VERSION "2021.24.4"

NS_ :

BS_:

BU_: VEH CH Receiver X

BO_ 259 VCRIGHT_doorStatus: 8 VEH
 SG_ VCRIGHT_frontHandlePWM: 14|7@1+ (1,0) [0|0] "%" X
 SG_ VCRIGHT_frontHandlePulled: 10|1@1+ (1,0) [0|0] "" X
 SG_ VCRIGHT_frontHandlePulledPersist: 30|1@1+ (1,0) [0|0] "" X
 SG_ VCRIGHT_frontIntSwitchPressed: 31|1@1+ (1,0) [0|0] "" X
 SG_ VCRIGHT_frontLatchStatus: 0|4@1+ (1,0) [0|0] "" X
 SG_ VCRIGHT_frontLatchSwitch: 8|1@1+ (1,0) [0|0] "" X
 SG_ VCRIGHT_frontRelActuatorSwitch: 12|1@1+ (1,0) [0|0] "" X
 SG_ VCRIGHT_mirrorDipped: 63|1@1+ (1,0) [0|0] "" X
 SG_ VCRIGHT_mirrorFoldState: 52|3@1+ (1,0) [0|0] "" X
 SG_ VCRIGHT_mirrorRecallState: 60|3@1+ (1,0) [0|0] "" X
 SG_ VCRIGHT_mirrorState: 49|3@1+ (1,0) [0|0] "" X
 SG_ VCRIGHT_mirrorTiltXPosition: 33|8@1+ (0.02,0) [0|0] "V" X
 SG_ VCRIGHT_mirrorTiltYPosition: 41|8@1+ (0.02,0) [0|0] "V" X
 SG_ VCRIGHT_rearHandlePWM: 21|7@1+ (1,0) [0|0] "%" X
 SG_ VCRIGHT_rearHandlePulled: 11|1@1+ (1,0) [0|0] "" X
 SG_ VCRIGHT_rearIntSwitchPressed: 32|1@1+ (1,0) [0|0] "" X
 SG_ VCRIGHT_rearLatchStatus: 4|4@1+ (1,0) [0|0] "" X
 SG_ VCRIGHT_rearLatchSwitch: 9|1@1+ (1,0) [0|0] "" X
 SG_ VCRIGHT_rearRelActuatorSwitch: 13|1@1+ (1,0) [0|0] "" X
 SG_ VCRIGHT_reservedForBackCompat: 28|2@1+ (1,0) [0|0] "" X
 SG_ VCRIGHT_trunkLatchStatus: 56|4@1+ (1,0) [0|0] "" X

BO_ 915 ID393VCRIGHT_epbmDebug: 8 VEH
 SG_ VCRIGHT_epbmDebugIndex M : 0|1@1+ (1,0) [0|1] ""  Receiver
 SG_ VCRIGHT_cdpEnumDummy m1 : 24|2@1+ (1,0) [0|2] ""  Receiver
 SG_ VCRIGHT_epbFaultStatus m0 : 58|2@1+ (1,0) [0|3] ""  Receiver
 SG_ VCRIGHT_epbMotorCurrent m0 : 5|11@1+ (0.01,0) [0|20.47] "A"  Receiver
 SG_ VCRIGHT_epbSummonState m0 : 45|3@1+ (1,0) [0|6] ""  Receiver
 SG_ VCRIGHT_epbUnitStatus m0 : 51|5@1+ (1,0) [0|22] ""  Receiver
 SG_ VCRIGHT_epbmApplyVoltage m0 : 16|11@1+ (0.01,0) [0|20.47] "A"  Receiver
 SG_ VCRIGHT_epbmCaliperState m0 : 1|3@1+ (1,0) [0|6] ""  Receiver
 SG_ VCRIGHT_epbmDynApplyingAllowed m1 : 9|1@1+ (1,0) [0|1] ""  Receiver
 SG_ VCRIGHT_epbmDynamicAllowed m1 : 2|1@1+ (1,0) [0|1] ""  Receiver
 SG_ VCRIGHT_epbmFaultAllowed m1 : 11|1@1+ (1,0) [0|1] ""  Receiver
 SG_ VCRIGHT_epbmFaultStatus m0 : 56|2@1+ (1,0) [0|3] ""  ui
 SG_ VCRIGHT_epbmMotorEnabled m0 : 4|1@1+ (1,0) [0|1] ""  Receiver
 SG_ VCRIGHT_epbmOpenAllowed m1 : 1|1@1+ (1,0) [0|1] ""  Receiver
 SG_ VCRIGHT_epbmParkAllowed m1 : 3|1@1+ (1,0) [0|1] ""  Receiver
 SG_ VCRIGHT_epbmParkingAllowed m1 : 8|1@1+ (1,0) [0|1] ""  Receiver
 SG_ VCRIGHT_epbmReleaseVoltage m0 : 27|11@1+ (0.01,0) [0|20.47] "A"  Receiver
 SG_ VCRIGHT_epbmReleasingAllowed m1 : 10|1@1+ (1,0) [0|1] ""  Receiver
 SG_ VCRIGHT_epbmServiceAllowed m1 : 5|1@1+ (1,0) [0|1] ""  Receiver
 SG_ VCRIGHT_epbmStartAllowed m1 : 4|1@1+ (1,0) [0|1] ""  Receiver
 SG_ VCRIGHT_epbmSummonAllowed m1 : 12|1@1+ (1,0) [0|1] ""  Receiver
 SG_ VCRIGHT_epbmSummonParkAllowed m1 : 13|1@1+ (1,0) [0|1] ""  Receiver
 SG_ VCRIGHT_epbmSummonReleaseAllowed m1 : 14|1@1+ (1,0) [0|1] ""  Receiver
 SG_ VCRIGHT_epbmSummonState m0 : 48|3@1+ (1,0) [0|6] ""  Receiver
 SG_ VCRIGHT_epbmSystemStatus m0 : 60|4@1+ (1,0) [0|8] ""  Receiver
 SG_ VCRIGHT_epbmUnknownAllowed m1 : 16|1@1+ (1,0) [0|1] ""  Receiver
 SG_ VCRIGHT_epbmWinchAllowed m1 : 6|1@1+ (1,0) [0|1] ""  Receiver
 SG_ VCRIGHT_epbmWinchReleaseAllowed m1 : 7|1@1+ (1,0) [0|1] ""  Receiver
 SG_ VCRIGHT_summonActiveAllowed m1 : 19|1@1+ (1,0) [0|1] ""  Receiver
 SG_ VCRIGHT_summonArmedAllowed m1 : 18|1@1+ (1,0) [0|1] ""  Receiver
 SG_ VCRIGHT_summonCompleteAllowed m1 : 20|1@1+ (1,0) [0|1] ""  Receiver
 SG_ VCRIGHT_summonFaultAllowed m1 : 21|1@1+ (1,0) [0|1] ""  Receiver
 SG_ VCRIGHT_summonFaultReason m0 : 40|5@1+ (1,0) [0|28] ""  Receiver
 SG_ VCRIGHT_summonIdleAllowed m1 : 17|1@1+ (1,0) [0|1] ""  Receiver
 SG_ VCRIGHT_summonInitAllowed m1 : 15|1@1+ (1,0) [0|1] ""  Receiver
 SG_ VCRIGHT_summonUnavailableAllowed m1 : 22|1@1+ (1,0) [0|1] ""  Receiver

BO_ 579 VCRIGHT_hvacStatus: 8 Vector__XXX
 SG_ VCRIGHT_hvacOverheatProtActive m3 : 63|1@1+ (1,0) [0|0] "" Vector__XXX
 SG_ VCRIGHT_hvacModelInitStatus m0 : 60|4@1+ (1,0) [0|0] "" Vector__XXX
 SG_ VCRIGHT_extendedHvacPerfTestSupportState m2 : 59|4@1+ (1,0) [0|0] "" Vector__XXX
 SG_ VCRIGHT_hvacLimitedReasonLeft m3 : 59|3@1+ (1,0) [0|0] "" Vector__XXX
 SG_ VCRIGHT_hvacSystemNominal m0 : 59|1@1+ (1,0) [0|0] "" Vector__XXX
 SG_ VCRIGHT_hvacDuctTargetRight m1 : 56|8@1+ (0.5,-40) [0|0] "" Vector__XXX
 SG_ VCRIGHT_hvacLimitedReasonRight m3 : 56|3@1+ (1,0) [0|0] "" Vector__XXX
 SG_ VCRIGHT_hvacSecondRowState m0 : 56|3@1+ (1,0) [0|0] "" Vector__XXX
 SG_ VCRIGHT_tempDuctRightLower m4 : 56|8@1+ (0.5,-22) [0|0] "" Vector__XXX
 SG_ VCRIGHT_hvacVentStatus m0 : 54|2@1+ (1,0) [0|0] "" Vector__XXX
 SG_ VCRIGHT_windshieldCameraHeaterDutyRequest m2 : 54|5@1+ (5,0) [0|0] "" Vector__XXX
 SG_ VCRIGHT_hvacRefHighPowerRequest m2 : 53|1@1+ (1,0) [0|0] "" Vector__XXX
 SG_ VCRIGHT_hvacPowerState m0 : 51|3@1+ (1,0) [0|0] "" Vector__XXX
 SG_ VCRIGHT_hvacACRunning m0 : 50|1@1+ (1,0) [0|0] "" Vector__XXX
 SG_ VCRIGHT_hvacDuctTargetLeft m1 : 48|8@1+ (0.5,-40) [0|0] "" Vector__XXX
 SG_ VCRIGHT_hvacRecirc m0 : 48|2@1+ (1,0) [0|0] "" Vector__XXX
 SG_ VCRIGHT_minsToSunset m3 : 48|8@1+ (10,0) [0|0] "" Vector__XXX
 SG_ VCRIGHT_refrigDistCommanded m2 : 48|1@1+ (1,0) [0|0] "" Vector__XXX
 SG_ VCRIGHT_tempDuctLeftLower m4 : 48|8@1+ (0.5,-22) [0|0] "" Vector__XXX
 SG_ VCRIGHT_hvacBlowerSegment m0 : 44|4@1+ (1,0) [0|0] "" Vector__XXX
 SG_ VCRIGHT_hvacAirDistributionMode m0 : 41|3@1+ (1,0) [0|0] "" Vector__XXX
 SG_ VCRIGHT_minsToSunrise m3 : 40|8@1+ (10,0) [0|0] "" Vector__XXX
 SG_ VCRIGHT_solarLoadOnVehicle m2 : 40|8@1+ (4,0) [0|0] "" Vector__XXX
 SG_ VCRIGHT_autoHvacBlowerShouldLimit m2 : 37|1@1+ (1,0) [0|0] "" Vector__XXX
 SG_ VCRIGHT_hvacQdotRight m4 : 34|14@1+ (1,-8191) [0|0] "" Vector__XXX
 SG_ VCRIGHT_blowerTorqueIndex m5 : 32|7@1+ (1,0) [0|0] "" Vector__XXX
 SG_ VCRIGHT_hvacAirflowReason m2 : 32|5@1+ (1,0) [0|0] "" Vector__XXX
 SG_ VCRIGHT_tempDuctRight m1 : 32|8@1+ (0.5,-22) [0|0] "" Vector__XXX
 SG_ VCRIGHT_solarElevation m3 : 31|9@1- (0.5,0) [0|0] "" Vector__XXX
 SG_ VCRIGHT_hvacCabinAtTempTarget m2 : 30|1@1+ (1,0) [0|0] "" Vector__XXX
 SG_ VCRIGHT_hvacCabinTempEst m0 : 30|11@1+ (0.1,-40) [0|0] "" Vector__XXX
 SG_ VCRIGHT_tempMonitorNotNominal m2 : 29|1@1+ (1,0) [0|0] "" Vector__XXX
 SG_ VCRIGHT_COPNotRunningReasonFiltered m0 : 27|3@1+ (1,0) [0|0] "" Vector__XXX
 SG_ VCRIGHT_autoDefogStatus m3 : 26|2@1+ (1,0) [0|0] "" Vector__XXX
 SG_ VCRIGHT_hvacCabinTempEstValid m0 : 26|1@1+ (1,0) [0|0] "" Vector__XXX
 SG_ VCRIGHT_hvacMassflowRefrigSystem m1 : 24|8@1+ (1,0) [0|0] "" Vector__XXX
 SG_ VCRIGHT_steeringWheelHeatStatus m3 : 24|2@1+ (1,0) [0|0] "" Vector__XXX
 SG_ VCRIGHT_dogModeState m0 : 22|4@1+ (1,0) [0|0] "" Vector__XXX
 SG_ VCRIGHT_hvacRequestsAutoIntake m3 : 22|1@1+ (1,0) [0|0] "" Vector__XXX
 SG_ VCRIGHT_passengerPresentHvacCycle m3 : 21|1@1+ (1,0) [0|0] "" Vector__XXX
 SG_ VCRIGHT_childModeHVACState m0 : 20|2@1+ (1,0) [0|0] "" Vector__XXX
 SG_ VCRIGHT_hvacQdotLeft m4 : 20|14@1+ (1,-8191) [0|0] "" Vector__XXX
 SG_ VCRIGHT_hvacEvapInletTempEstimate m2 : 19|10@1+ (0.13,-40) [0|0] "" Vector__XXX
 SG_ VCRIGHT_hpSplitTempsEnabled m2 : 18|1@1+ (1,0) [0|0] "" Vector__XXX
 SG_ VCRIGHT_hvacFrontLeftSeatHeatStatus m4 : 18|2@1+ (1,0) [0|0] "" Vector__XXX
 SG_ VCRIGHT_hvacRequestsFullAuto m3 : 17|3@1+ (1,0) [0|0] "" Vector__XXX
 SG_ VCRIGHT_tempDuctLeft m1 : 16|8@1+ (0.5,-22) [0|0] "" Vector__XXX
 SG_ VCRIGHT_coolingDownStatus m0 : 15|5@1+ (3,7) [0|0] "" Vector__XXX
 SG_ VCRIGHT_hvacManualToAutoNotify m3 : 14|3@1+ (1,0) [0|0] "" Vector__XXX
 SG_ VCRIGHT_hvacRecircDoorPercent m1 : 10|6@1+ (1.6,0) [0|0] "" Vector__XXX
 SG_ VCRIGHT_tempDuctLeftUpper m4 : 10|8@1+ (0.5,-22) [0|0] "" Vector__XXX
 SG_ VCRIGHT_tempDuctRightUpper m2 : 10|8@1+ (0.5,-22) [0|0] "" Vector__XXX
 SG_ VCRIGHT_warmingUpStatus m0 : 10|5@1+ (3,7) [0|0] "" Vector__XXX
 SG_ VCRIGHT_autoSwingAvailable m4 : 9|1@1+ (1,0) [0|0] "" Vector__XXX
 SG_ VCRIGHT_enableTripleCameraFanPowerInSleep m2 : 9|1@1+ (1,0) [0|0] "" Vector__XXX
 SG_ VCRIGHT_foggingControllerResetReason m5 : 9|15@1+ (1,0) [0|0] "" Vector__XXX
 SG_ VCRIGHT_hvacSeatFrontLeftTempTarget m3 : 6|8@1+ (0.5,-40) [0|0] "" Vector__XXX
 SG_ VCRIGHT_hvacFrontRightSeatHeatStatus m3 : 4|2@1+ (1,0) [0|0] "" Vector__XXX
 SG_ VCRIGHT_hvacStatusIndex M : 0|3@1+ (1,0) [0|0] "" Vector__XXX

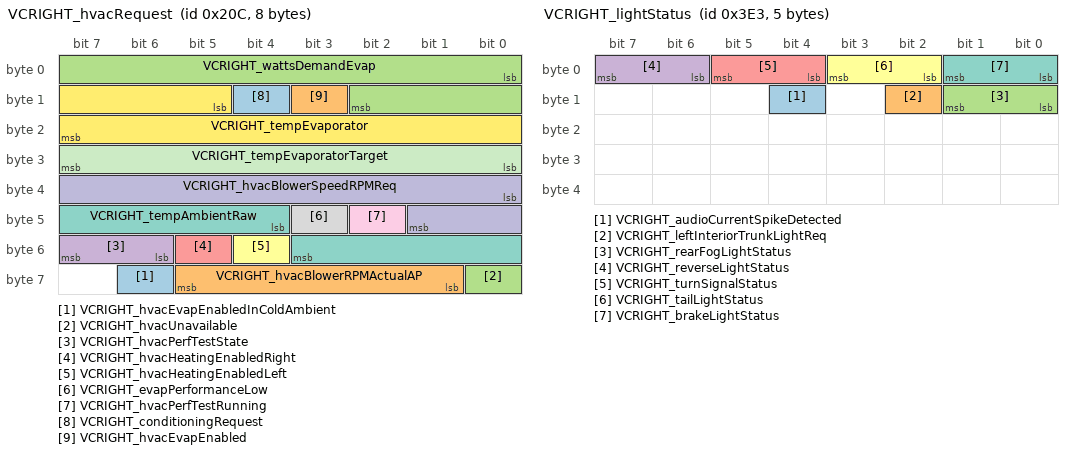
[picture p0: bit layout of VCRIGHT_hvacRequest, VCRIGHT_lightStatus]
BO_ 524 VCRIGHT_hvacRequest: 8 Vector__XXX
 SG_ VCRIGHT_hvacEvapEnabledInColdAmbient : 62|1@1+ (1,0) [0|0] "" Vector__XXX
 SG_ VCRIGHT_hvacBlowerRPMActualAP : 57|5@1+ (200,0) [0|0] "" Vector__XXX
 SG_ VCRIGHT_hvacUnavailable : 56|1@1+ (1,0) [0|0] "" Vector__XXX
 SG_ VCRIGHT_hvacPerfTestState : 54|2@1+ (1,0) [0|0] "" Vector__XXX
 SG_ VCRIGHT_hvacHeatingEnabledRight : 53|1@1+ (1,0) [0|0] "" Vector__XXX
 SG_ VCRIGHT_hvacHeatingEnabledLeft : 52|1@1+ (1,0) [0|0] "" Vector__XXX
 SG_ VCRIGHT_tempAmbientRaw : 44|8@1+ (0.5,-40) [0|0] "" Vector__XXX
 SG_ VCRIGHT_evapPerformanceLow : 43|1@1+ (1,0) [0|0] "" Vector__XXX
 SG_ VCRIGHT_hvacPerfTestRunning : 42|1@1+ (1,0) [0|0] "" Vector__XXX
 SG_ VCRIGHT_hvacBlowerSpeedRPMReq : 32|10@1+ (5,0) [0|0] "" Vector__XXX
 SG_ VCRIGHT_tempEvaporatorTarget : 24|8@1+ (0.2,0) [0|0] "" Vector__XXX
 SG_ VCRIGHT_tempEvaporator : 13|11@1+ (0.1,-40) [0|0] "" Vector__XXX
 SG_ VCRIGHT_conditioningRequest : 12|1@1+ (1,0) [0|0] "" Vector__XXX
 SG_ VCRIGHT_hvacEvapEnabled : 11|1@1+ (1,0) [0|0] "" Vector__XXX
 SG_ VCRIGHT_wattsDemandEvap : 0|11@1+ (5,0) [0|0] "" Vector__XXX

BO_ 774 VCRIGHT_info_306: 8 VEH
 SG_ VCRIGHT_infoIndex M: 0|8@1+ (1,0) [0|0] "" X
 SG_ VCRIGHT_infoBuildType m10: 8|3@1+ (1,0) [0|0] "" X
 SG_ VCRIGHT_infoBuildConfigId m10: 16|16@1+ (1,0) [0|0] "" X
 SG_ VCRIGHT_infoHardwareId m10: 32|16@1+ (1,0) [0|0] "" X
 SG_ VCRIGHT_infoComponentId m10: 48|16@1+ (1,0) [0|0] "" X
 SG_ VCRIGHT_infoPcbaId m11: 8|8@1+ (1,0) [0|0] "" X
 SG_ VCRIGHT_infoAssemblyId m11: 16|8@1+ (1,0) [0|0] "" X
 SG_ VCRIGHT_infoUsageId m11: 24|16@1+ (1,0) [0|0] "" X
 SG_ VCRIGHT_infoSubUsageId m11: 40|16@1+ (1,0) [0|0] "" X
 SG_ VCRIGHT_infoAppCrc m13: 8|32@1+ (1,0) [0|0] "" X
 SG_ VCRIGHT_infoAppGitHash m17: 10|54@1+ (4,0) [0|0] "" X
 SG_ VCRIGHT_infoBootGitHash m18: 10|54@1+ (4,0) [0|0] "" X
 SG_ VCRIGHT_infoPlatformType m19: 8|8@1+ (1,0) [0|0] "" X
 SG_ VCRIGHT_infoBootUdsProtoVersion m20: 8|16@1+ (1,0) [0|0] "" X
 SG_ VCRIGHT_infoBootCrc m20: 24|32@1+ (1,0) [0|0] "" X

BO_ 995 VCRIGHT_lightStatus: 5 Vector__XXX
 SG_ VCRIGHT_audioCurrentSpikeDetected : 12|1@1+ (1,0) [0|0] "" Vector__XXX
 SG_ VCRIGHT_leftInteriorTrunkLightReq : 10|1@1+ (1,0) [0|0] "" Vector__XXX
 SG_ VCRIGHT_rearFogLightStatus : 8|2@1+ (1,0) [0|0] "" Vector__XXX
 SG_ VCRIGHT_reverseLightStatus : 6|2@1+ (1,0) [0|0] "" Vector__XXX
 SG_ VCRIGHT_turnSignalStatus : 4|2@1+ (1,0) [0|0] "" Vector__XXX
 SG_ VCRIGHT_tailLightStatus : 2|2@1+ (1,0) [0|0] "" Vector__XXX
 SG_ VCRIGHT_brakeLightStatus : 0|2@1+ (1,0) [0|0] "" Vector__XXX

BO_ 611 VCRIGHT_logging10Hz: 8 Vector__XXX
 SG_ VCRIGHT_ptcHeaterBadRodDetectionState m2 : 56|4@1+ (1,0) [0|0] "" Vector__XXX
 SG_ VCRIGHT_windshieldRHExteriorSurface m3 : 56|8@1+ (1,0) [0|0] "" Vector__XXX
 SG_ VCRIGHT_hvacIntakePosition m1 : 53|8@1+ (0.4,0) [0|0] "" Vector__XXX
 SG_ VCRIGHT_hvacIntakeTarget m0 : 53|8@1+ (0.4,0) [0|0] "" Vector__XXX
 SG_ VCRIGHT_tempDuctRightEst m2 : 48|8@1+ (0.5,-22) [0|0] "" Vector__XXX
 SG_ VCRIGHT_hvacLowerModePosition m1 : 45|8@1+ (0.4,0) [0|0] "" Vector__XXX
 SG_ VCRIGHT_hvacLowerModeTarget m0 : 45|8@1+ (0.4,0) [0|0] "" Vector__XXX
 SG_ VCRIGHT_frontRightSeatTempTargetQuasiSS m4 : 42|6@1+ (1,20) [0|0] "" Vector__XXX
 SG_ VCRIGHT_tempDuctLeftEst m2 : 40|8@1+ (0.5,-22) [0|0] "" Vector__XXX
 SG_ VCRIGHT_frontLeftSeatTempTargetQuasiSS m4 : 36|6@1+ (0.75,20) [0|0] "" Vector__XXX
 SG_ VCRIGHT_hvacUpperModePosition m1 : 35|10@1+ (0.1,0) [0|0] "" Vector__XXX
 SG_ VCRIGHT_hvacUpperModeTarget m0 : 35|10@1+ (0.1,0) [0|0] "" Vector__XXX
 SG_ VCRIGHT_tempDatRightEst m2 : 30|9@1+ (0.5,-22) [0|0] "" Vector__XXX
 SG_ VCRIGHT_hvacRHVanePosition m1 : 27|8@1+ (0.4,0) [0|0] "" Vector__XXX
 SG_ VCRIGHT_hvacRHVaneTarget m0 : 27|8@1+ (0.4,0) [0|0] "" Vector__XXX
 SG_ VCRIGHT_tempDatLeftEst m2 : 21|9@1+ (0.5,-22) [0|0] "" Vector__XXX
 SG_ VCRIGHT_EvapPulldownBiasActive m2 : 20|1@1+ (1,0) [0|0] "" Vector__XXX
 SG_ VCRIGHT_hvacLHVanePosition m1 : 19|8@1+ (0.4,0) [0|0] "" Vector__XXX
 SG_ VCRIGHT_hvacLHVaneTarget m0 : 19|8@1+ (0.4,0) [0|0] "" Vector__XXX
 SG_ VCRIGHT_hvacIntakeActuatorState m2 : 16|2@1+ (1,0) [0|0] "" Vector__XXX
 SG_ VCRIGHT_hvacLowerModeActState m2 : 14|2@1+ (1,0) [0|0] "" Vector__XXX
 SG_ VCRIGHT_hvacUpperModeActState m2 : 12|2@1+ (1,0) [0|0] "" Vector__XXX
 SG_ VCRIGHT_hvacRHBleedPosition m1 : 11|8@1+ (0.4,0) [0|0] "" Vector__XXX
 SG_ VCRIGHT_hvacRHBleedTarget m0 : 11|8@1+ (0.4,0) [0|0] "" Vector__XXX
 SG_ VCRIGHT_hvacRHVaneActuatorState m2 : 10|2@1+ (1,0) [0|0] "" Vector__XXX
 SG_ VCRIGHT_hvacLHVaneActuatorState m2 : 8|2@1+ (1,0) [0|0] "" Vector__XXX
 SG_ VCRIGHT_hvacRHBleedActuatorState m2 : 5|2@1+ (1,0) [0|0] "" Vector__XXX
 SG_ VCRIGHT_hvacLHBleedActuatorState m2 : 3|2@1+ (1,0) [0|0] "" Vector__XXX
 SG_ VCRIGHT_hvacLHBleedPosition m1 : 3|8@1+ (0.4,0) [0|0] "" Vector__XXX
 SG_ VCRIGHT_hvacLHBleedTarget m0 : 3|8@1+ (0.4,0) [0|0] "" Vector__XXX
 SG_ VCRIGHT_logging10HzIndex M : 0|3@1+ (1,0) [0|0] "" Vector__XXX

BO_ 691 VCRIGHT_logging1Hz: 8 VEH
 SG_ VCRIGHT_logging1HzIndex M : 0|4@1+ (1,0) [0|11] "" X
 SG_ VCRIGHT_LHPanelAirflowBlocked m3 : 54|1@1+ (1,0) [0|1] "" X
 SG_ VCRIGHT_RHPanelAirflowBlocked m3 : 55|1@1+ (1,0) [0|1] "" X
 SG_ VCRIGHT_cabinTempBreathLevel m1 : 56|8@1+ (0.5,-40) [-40|80] "C" X
 SG_ VCRIGHT_cabinTempFanCurrent m9 : 15|6@1- (0.001,0) [-0.01|0.05] "A" X
 SG_ VCRIGHT_cabinTempFanOutput m9 : 14|1@1+ (1,0) [0|1] "" X
 SG_ VCRIGHT_cabinTempGlassRoof m1 : 8|8@1+ (0.5,-40) [-40|80] "C" X
 SG_ VCRIGHT_cabinTempInterior m1 : 24|8@1+ (0.5,-40) [-40|80] "C" X
 SG_ VCRIGHT_cabinTempInteriorL2 m0 : 24|8@1+ (0.5,-40) [-40|80] "C" X
 SG_ VCRIGHT_cabinTempInteriorL3 m9 : 40|8@1+ (0.5,-40) [-40|80] "C" X
 SG_ VCRIGHT_cabinTempInteriorSunny m1 : 32|8@1+ (0.6,-40) [-40|100] "C" X
 SG_ VCRIGHT_cabinTempInteriorSunnyL2 m0 : 40|8@1+ (0.6,-40) [-40|100] "C" X
 SG_ VCRIGHT_cabinTempInteriorSunnyL3 m9 : 48|8@1+ (0.6,-40) [-40|100] "C" X
 SG_ VCRIGHT_cabinTempSideGlassLeft m1 : 40|8@1+ (0.5,-40) [-40|80] "C" X
 SG_ VCRIGHT_cabinTempSideGlassRight m1 : 48|8@1+ (0.5,-40) [-40|80] "C" X
 SG_ VCRIGHT_cabinTempTopPadAir m9 : 56|8@1+ (0.6,-40) [-40|100] "C" X
 SG_ VCRIGHT_cabinTempWindshield m1 : 16|8@1+ (0.5,-40) [-40|80] "C" X
 SG_ VCRIGHT_cloudinessProbability m9 : 33|7@1+ (1,0) [0|100] "%" X
 SG_ VCRIGHT_convectionDeliveredLeft m4 : 24|8@1+ (2,-254) [-254|256] "W/m2" X
 SG_ VCRIGHT_convectionDeliveredRight m4 : 32|8@1+ (2,-254) [-254|256] "W/m2" X
 SG_ VCRIGHT_convectionTargetLeft m4 : 8|8@1+ (2,-254) [-254|256] "W/m2" X
 SG_ VCRIGHT_convectionTargetRight m4 : 16|8@1+ (2,-254) [-254|256] "W/m2" X
 SG_ VCRIGHT_defrostAirflowBlocked m3 : 57|1@1+ (1,0) [0|1] "" X
 SG_ VCRIGHT_evapCondensationRate m10 : 47|9@1- (0.007,0) [-1|1] "g/s" X
 SG_ VCRIGHT_evapDryingRoutineRuntime m10 : 56|5@1+ (2,0) [0|60] "" X
 SG_ VCRIGHT_evapLoadInFresh m5 : 32|8@1+ (35,0) [0|8000] "W" X
 SG_ VCRIGHT_evapLoadInRecirc m5 : 40|8@1+ (35,0) [0|8000] "W" X
 SG_ VCRIGHT_evapWaterMass m10 : 40|7@1+ (6,0) [0|380] "Grams" X
 SG_ VCRIGHT_filterLifeBlowerTorque m9 : 4|10@1+ (0.006,-1.5) [-1.5|4.5] "Nm" X
 SG_ VCRIGHT_floorAirflowBlocked m3 : 56|1@1+ (1,0) [0|1] "" X
 SG_ VCRIGHT_hvacAirFlowModeRow1 m3 : 29|3@1+ (1,0) [0|7] "" X
 SG_ VCRIGHT_hvacAirFlowModeRow2 m3 : 32|3@1+ (1,0) [0|7] "" X
 SG_ VCRIGHT_hvacAirflowReason m3 : 48|4@1+ (1,0) [0|14] "" X
 SG_ VCRIGHT_hvacAutoTransitionReason m3 : 24|5@1+ (1,0) [0|19] "" X
 SG_ VCRIGHT_hvacCabOvrheatProtActive m9 : 30|1@1+ (1,0) [0|1] "" X
 SG_ VCRIGHT_hvacCabOvrheatProtAllowe m9 : 32|1@1+ (1,0) [0|1] "" X
 SG_ VCRIGHT_hvacCabinPurgeActive m9 : 29|1@1+ (1,0) [0|1] "" X
 SG_ VCRIGHT_hvacCabinPurgeAllowed m9 : 31|1@1+ (1,0) [0|1] "" X
 SG_ VCRIGHT_hvacIntakeEndStop m7 : 56|8@1+ (0.02,0) [0|5] "V" X
 SG_ VCRIGHT_hvacIntakeVoltage m6 : 56|8@1+ (0.02,0) [0|5] "V" X
 SG_ VCRIGHT_hvacIntakeZeroStop m8 : 56|8@1+ (0.02,0) [0|5] "V" X
 SG_ VCRIGHT_hvacLHBleedEndStop m7 : 8|8@1+ (0.02,0) [0|5] "V" X
 SG_ VCRIGHT_hvacLHBleedVoltage m6 : 8|8@1+ (0.02,0) [0|5] "V" X
 SG_ VCRIGHT_hvacLHBleedZeroStop m8 : 8|8@1+ (0.02,0) [0|5] "V" X
 SG_ VCRIGHT_hvacLHVaneEndStop m7 : 24|8@1+ (0.02,0) [0|5] "V" X
 SG_ VCRIGHT_hvacLHVaneVoltage m6 : 24|8@1+ (0.02,0) [0|5] "V" X
 SG_ VCRIGHT_hvacLHVaneZeroStop m8 : 24|8@1+ (0.02,0) [0|5] "V" X
 SG_ VCRIGHT_hvacLowerModeEndStop m7 : 48|8@1+ (0.02,0) [0|5] "V" X
 SG_ VCRIGHT_hvacLowerModeVoltage m6 : 48|8@1+ (0.02,0) [0|5] "V" X
 SG_ VCRIGHT_hvacLowerModeZeroStop m8 : 48|8@1+ (0.02,0) [0|5] "V" X
 SG_ VCRIGHT_hvacMassflowTarget m3 : 40|8@1+ (1,0) [0|200] "g/s" X
 SG_ VCRIGHT_hvacQdotFeedforward m5 : 16|16@1+ (1,-32767) [-32767|32767] "W" X
 SG_ VCRIGHT_hvacQdotLimitedLeft m3 : 52|1@1+ (1,0) [0|1] "" X
 SG_ VCRIGHT_hvacQdotLimitedRight m3 : 53|1@1+ (1,0) [0|1] "" X
 SG_ VCRIGHT_hvacRHBleedEndStop m7 : 16|8@1+ (0.02,0) [0|5] "V" X
 SG_ VCRIGHT_hvacRHBleedVoltage m6 : 16|8@1+ (0.02,0) [0|5] "V" X
 SG_ VCRIGHT_hvacRHBleedZeroStop m8 : 16|8@1+ (0.02,0) [0|5] "V" X
 SG_ VCRIGHT_hvacRHVaneEndStop m7 : 32|8@1+ (0.02,0) [0|5] "V" X
 SG_ VCRIGHT_hvacRHVaneVoltage m6 : 32|8@1+ (0.02,0) [0|5] "V" X
 SG_ VCRIGHT_hvacRHVaneZeroStop m8 : 32|8@1+ (0.02,0) [0|5] "V" X
 SG_ VCRIGHT_hvacSetTempActualLeft m3 : 8|8@1+ (0.1,15) [15|28] "C" X
 SG_ VCRIGHT_hvacSetTempActualRight m3 : 16|8@1+ (0.1,15) [15|28] "C" X
 SG_ VCRIGHT_hvacUpperModeEndStop m7 : 40|8@1+ (0.02,0) [0|5] "V" X
 SG_ VCRIGHT_hvacUpperModeVoltage m6 : 40|8@1+ (0.02,0) [0|5] "V" X
 SG_ VCRIGHT_hvacUpperModeZeroStop m8 : 40|8@1+ (0.02,0) [0|5] "V" X
 SG_ VCRIGHT_leftHeatOvertempProtect m10 : 61|1@1+ (1,0) [0|1] "" X
 SG_ VCRIGHT_pcbaTemperature m2 : 4|11@1+ (0.125,-40) [-40|150] "C" X
 SG_ VCRIGHT_ptcHeaterHvacActNotReady m5 : 7|1@1+ (1,0) [0|1] "" X
 SG_ VCRIGHT_ptcHeaterLAirPathBlocked m5 : 10|1@1+ (1,0) [0|1] "" X
 SG_ VCRIGHT_ptcHeaterNoAirflow m5 : 6|1@1+ (1,0) [0|1] "" X
 SG_ VCRIGHT_ptcHeaterNoHighVoltage m5 : 9|1@1+ (1,0) [0|1] "" X
 SG_ VCRIGHT_ptcHeaterNoUiRequest m5 : 8|1@1+ (1,0) [0|1] "" X
 SG_ VCRIGHT_ptcHeaterPwrDemandLeft m2 : 40|8@1+ (20,0) [0|5000] "W" X
 SG_ VCRIGHT_ptcHeaterPwrDemandRight m2 : 48|8@1+ (20,0) [0|5000] "W" X
 SG_ VCRIGHT_ptcHeaterRAirPathBlocked m5 : 11|1@1+ (1,0) [0|1] "" X
 SG_ VCRIGHT_ptcHeaterReqAirpathBlock m5 : 12|1@1+ (1,0) [0|1] "" X
 SG_ VCRIGHT_ptcHeaterTempDuctFault m5 : 5|1@1+ (1,0) [0|1] "" X
 SG_ VCRIGHT_ptcHeaterTempDuctHigh m5 : 4|1@1+ (1,0) [0|1] "" X
 SG_ VCRIGHT_rightHeatOvertempProtect m10 : 62|1@1+ (1,0) [0|1] "" X
 SG_ VCRIGHT_solarLoadLeftOccupant m4 : 48|7@1+ (2,0) [0|254] "W/m2" X
 SG_ VCRIGHT_solarLoadOnVehFiltered m9 : 21|8@1+ (4,0) [0|1020] "W/m2" X
 SG_ VCRIGHT_solarLoadOnVehicle m4 : 56|8@1+ (4,0) [0|1020] "W/m2" X
 SG_ VCRIGHT_solarLoadRightOccupant m4 : 40|7@1+ (2,0) [0|254] "W/m2" X
 SG_ VCRIGHT_tempDuctModeledLeft m10 : 4|9@1+ (0.3,-40) [-40|105] "C" X
 SG_ VCRIGHT_tempDuctModeledRight m10 : 13|9@1+ (0.3,-40) [-40|105] "C" X
 SG_ VCRIGHT_tempHtrSurfaceModeledL m10 : 22|9@1+ (0.3,-40) [-40|105] "C" X
 SG_ VCRIGHT_tempHtrSurfaceModeledR m10 : 31|9@1+ (0.3,-40) [-40|105] "C" X
 SG_ VCRIGHT_tempIncarCabinDeep m0 : 16|8@1+ (0.5,-40) [-40|85] "C" X
 SG_ VCRIGHT_tempIncarCabinMid m0 : 32|8@1+ (0.5,-40) [-40|85] "C" X
 SG_ VCRIGHT_tempIncarCabinProbe m0 : 8|8@1+ (0.5,-40) [-40|85] "C" X
 SG_ VCRIGHT_wattsHeaterLeftTotal m2 : 16|10@1+ (5,0) [0|4000] "W" X
 SG_ VCRIGHT_wattsHeaterRightTotal m2 : 26|10@1+ (5,0) [0|4000] "W" X

BO_ 1859 VCRIGHT_recallStatus: 1 VEH
 SG_ VCRIGHT_mirrorRecallStatus: 4|2@1+ (1,0) [0|0] "" X
 SG_ VCRIGHT_seatRecallStatus: 2|2@1+ (1,0) [0|0] "" X
 SG_ VCRIGHT_systemRecallStatus: 0|2@1+ (1,0) [0|0] "" X

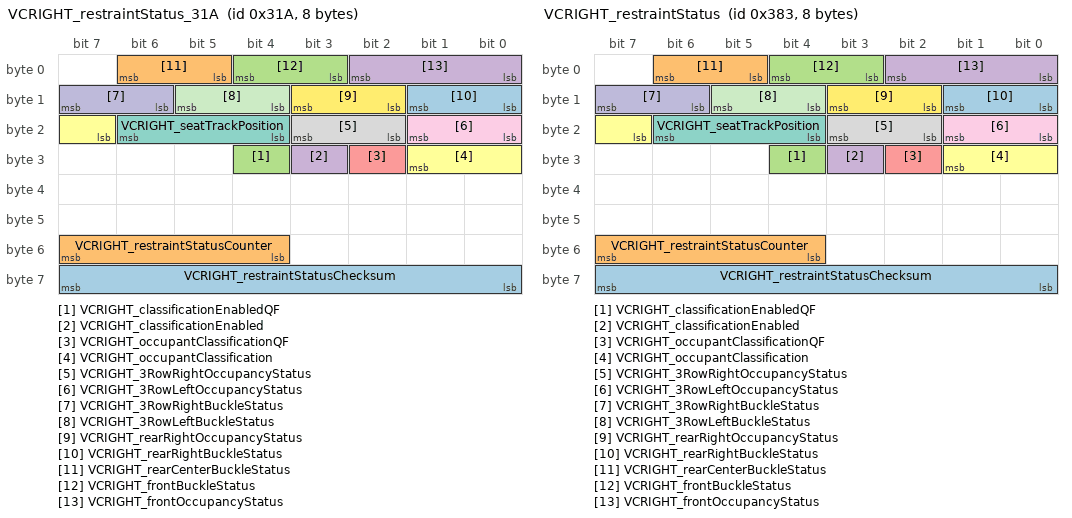
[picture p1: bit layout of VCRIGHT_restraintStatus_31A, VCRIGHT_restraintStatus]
BO_ 794 VCRIGHT_restraintStatus_31A: 8 Vector__XXX
 SG_ VCRIGHT_restraintStatusChecksum : 56|8@1+ (1,0) [0|0] "" Vector__XXX
 SG_ VCRIGHT_restraintStatusCounter : 52|4@1+ (1,0) [0|0] "" Vector__XXX
 SG_ VCRIGHT_classificationEnabledQF : 28|1@1+ (1,0) [0|0] "" Vector__XXX
 SG_ VCRIGHT_classificationEnabled : 27|1@1+ (1,0) [0|0] "" Vector__XXX
 SG_ VCRIGHT_occupantClassificationQF : 26|1@1+ (1,0) [0|0] "" Vector__XXX
 SG_ VCRIGHT_occupantClassification : 23|3@1+ (1,0) [0|0] "" Vector__XXX
 SG_ VCRIGHT_seatTrackPosition : 20|3@1+ (1,0) [0|0] "" Vector__XXX
 SG_ VCRIGHT_3RowRightOccupancyStatus : 18|2@1+ (1,0) [0|0] "" Vector__XXX
 SG_ VCRIGHT_3RowLeftOccupancyStatus : 16|2@1+ (1,0) [0|0] "" Vector__XXX
 SG_ VCRIGHT_3RowRightBuckleStatus : 14|2@1+ (1,0) [0|0] "" Vector__XXX
 SG_ VCRIGHT_3RowLeftBuckleStatus : 12|2@1+ (1,0) [0|0] "" Vector__XXX
 SG_ VCRIGHT_rearRightOccupancyStatus : 10|2@1+ (1,0) [0|0] "" Vector__XXX
 SG_ VCRIGHT_rearRightBuckleStatus : 8|2@1+ (1,0) [0|0] "" Vector__XXX
 SG_ VCRIGHT_rearCenterBuckleStatus : 5|2@1+ (1,0) [0|0] "" Vector__XXX
 SG_ VCRIGHT_frontBuckleStatus : 3|2@1+ (1,0) [0|0] "" Vector__XXX
 SG_ VCRIGHT_frontOccupancyStatus : 0|3@1+ (1,0) [0|0] "" Vector__XXX

BO_ 1251 VCRIGHT_seatStatus: 8 Vector__XXX
 SG_ VCRIGHT_lumbarDevMaxPumpPressB m4 : 60|1@1+ (1,0) [0|0] "" Vector__XXX
 SG_ VCRIGHT_lumbarDevMaxPumpPressA m4 : 59|1@1+ (1,0) [0|0] "" Vector__XXX
 SG_ VCRIGHT_lumbarGeneralErr m4 : 58|1@1+ (1,0) [0|0] "" Vector__XXX
 SG_ VCRIGHT_lumbarMinPErr m4 : 57|1@1+ (1,0) [0|0] "" Vector__XXX
 SG_ VCRIGHT_lumbarMaxOperatingPErr m4 : 56|1@1+ (1,0) [0|0] "" Vector__XXX
 SG_ VCRIGHT_frontSeatBackPercentage m1 : 55|7@1+ (1,0) [0|0] "" Vector__XXX
 SG_ VCRIGHT_frontSeatLiftPercentage m2 : 55|7@1+ (1,0) [0|0] "" Vector__XXX
 SG_ VCRIGHT_frontSeatTiltPercentage m3 : 55|7@1+ (1,0) [0|0] "" Vector__XXX
 SG_ VCRIGHT_frontSeatTrackPercentage m0 : 55|7@1+ (1,0) [0|0] "" Vector__XXX
 SG_ VCRIGHT_lumbarOvercurrentErr m4 : 55|1@1+ (1,0) [0|0] "" Vector__XXX
 SG_ VCRIGHT_lumbarMaxPErr m4 : 54|1@1+ (1,0) [0|0] "" Vector__XXX
 SG_ VCRIGHT_frontSeatBackBridgeSt m1 : 53|2@1+ (1,0) [0|0] "" Vector__XXX
 SG_ VCRIGHT_frontSeatLiftBridgeSt m2 : 53|2@1+ (1,0) [0|0] "" Vector__XXX
 SG_ VCRIGHT_frontSeatTiltBridgeSt m3 : 53|2@1+ (1,0) [0|0] "" Vector__XXX
 SG_ VCRIGHT_frontSeatTrackBridgeSt m0 : 53|2@1+ (1,0) [0|0] "" Vector__XXX
 SG_ VCRIGHT_lumbarActiveTooLongErr m4 : 53|1@1+ (1,0) [0|0] "" Vector__XXX
 SG_ VCRIGHT_frontSeatBackLog m1 : 52|1@1+ (1,0) [0|0] "" Vector__XXX
 SG_ VCRIGHT_frontSeatLiftLog m2 : 52|1@1+ (1,0) [0|0] "" Vector__XXX
 SG_ VCRIGHT_frontSeatTiltLog m3 : 52|1@1+ (1,0) [0|0] "" Vector__XXX
 SG_ VCRIGHT_frontSeatTrackLog m0 : 52|1@1+ (1,0) [0|0] "" Vector__XXX
 SG_ VCRIGHT_frontSeatBackCalibrated m1 : 51|1@1+ (1,0) [0|0] "" Vector__XXX
 SG_ VCRIGHT_frontSeatLiftCalibrated m2 : 51|1@1+ (1,0) [0|0] "" Vector__XXX
 SG_ VCRIGHT_frontSeatTiltCalibrated m3 : 51|1@1+ (1,0) [0|0] "" Vector__XXX
 SG_ VCRIGHT_frontSeatTrackCalibrated m0 : 51|1@1+ (1,0) [0|0] "" Vector__XXX
 SG_ VCRIGHT_frontSeatBackState m1 : 48|3@1+ (1,0) [0|0] "" Vector__XXX
 SG_ VCRIGHT_frontSeatLiftState m2 : 48|3@1+ (1,0) [0|0] "" Vector__XXX
 SG_ VCRIGHT_frontSeatTiltState m3 : 48|3@1+ (1,0) [0|0] "" Vector__XXX
 SG_ VCRIGHT_frontSeatTrackState m0 : 48|3@1+ (1,0) [0|0] "" Vector__XXX
 SG_ VCRIGHT_lumbarBPressureHpaFilt m4 : 43|10@1+ (1,0) [0|0] "" Vector__XXX
 SG_ VCRIGHT_frontSeatTiltPosOffset m6 : 40|12@1- (0.1,0) [0|0] "" Vector__XXX
 SG_ VCRIGHT_frontSeatTiltPosReal m5 : 40|12@1- (0.1,0) [0|0] "" Vector__XXX
 SG_ VCRIGHT_frontSeatBackDuty m1 : 36|12@1- (0.1,0) [0|0] "" Vector__XXX
 SG_ VCRIGHT_frontSeatLiftDuty m2 : 36|12@1- (0.1,0) [0|0] "" Vector__XXX
 SG_ VCRIGHT_frontSeatTiltDuty m3 : 36|12@1- (0.1,0) [0|0] "" Vector__XXX
 SG_ VCRIGHT_frontSeatTrackDuty m0 : 36|12@1- (0.1,0) [0|0] "" Vector__XXX
 SG_ VCRIGHT_lumbarBPressureHpa m4 : 31|12@1+ (1,0) [0|0] "" Vector__XXX
 SG_ VCRIGHT_frontSeatLiftPosOffset m6 : 28|12@1- (1,0) [0|0] "" Vector__XXX
 SG_ VCRIGHT_frontSeatLiftPosReal m5 : 28|12@1- (1,0) [0|0] "" Vector__XXX
 SG_ VCRIGHT_frontSeatBackCurrent m1 : 24|12@1- (0.01,0) [0|0] "" Vector__XXX
 SG_ VCRIGHT_frontSeatLiftCurrent m2 : 24|12@1- (0.01,0) [0|0] "" Vector__XXX
 SG_ VCRIGHT_frontSeatTiltCurrent m3 : 24|12@1- (0.01,0) [0|0] "" Vector__XXX
 SG_ VCRIGHT_frontSeatTrackCurrent m0 : 24|12@1- (0.01,0) [0|0] "" Vector__XXX
 SG_ VCRIGHT_lumbarAPressureHpaFilt m4 : 21|10@1+ (1,0) [0|0] "" Vector__XXX
 SG_ VCRIGHT_frontSeatBackPosOffset m6 : 16|12@1- (0.1,0) [0|0] "" Vector__XXX
 SG_ VCRIGHT_frontSeatBackPosReal m5 : 16|12@1- (0.1,0) [0|0] "" Vector__XXX
 SG_ VCRIGHT_lumbarBPressurePercentage m7 : 10|7@1+ (1,0) [0|0] "" Vector__XXX
 SG_ VCRIGHT_lumbarAPressureHpa m4 : 9|12@1+ (1,0) [0|0] "" Vector__XXX
 SG_ VCRIGHT_frontSeatBackPos m1 : 8|16@1- (1,0) [0|0] "" Vector__XXX
 SG_ VCRIGHT_frontSeatLiftPos m2 : 8|16@1- (1,0) [0|0] "" Vector__XXX
 SG_ VCRIGHT_frontSeatTiltPos m3 : 8|16@1- (1,0) [0|0] "" Vector__XXX
 SG_ VCRIGHT_frontSeatTrackPos m0 : 8|16@1- (1,0) [0|0] "" Vector__XXX
 SG_ VCRIGHT_lumbarBState m4 : 6|3@1+ (1,0) [0|0] "" Vector__XXX
 SG_ VC_AH_1RowRightSeatMovementHealth m0 : 5|3@1+ (1,0) [0|0] "" Vector__XXX
 SG_ VCRIGHT_frontSeatTrackPosOffset m6 : 3|12@1- (1,0) [0|0] "" Vector__XXX
 SG_ VCRIGHT_frontSeatTrackPosReal m5 : 3|12@1- (1,0) [0|0] "" Vector__XXX
 SG_ VCRIGHT_lumbarAPressurePercentage m7 : 3|7@1+ (1,0) [0|0] "" Vector__XXX
 SG_ VCRIGHT_lumbarAState m4 : 3|3@1+ (1,0) [0|0] "" Vector__XXX
 SG_ VCRIGHT_seatStatusIndex M : 0|3@1+ (1,0) [0|0] "" Vector__XXX

BO_ 899 VCRIGHT_restraintStatus: 8 Vector__XXX
 SG_ VCRIGHT_restraintStatusChecksum : 56|8@1+ (1,0) [0|0] "" Vector__XXX
 SG_ VCRIGHT_restraintStatusCounter : 52|4@1+ (1,0) [0|0] "" Vector__XXX
 SG_ VCRIGHT_classificationEnabledQF : 28|1@1+ (1,0) [0|0] "" Vector__XXX
 SG_ VCRIGHT_classificationEnabled : 27|1@1+ (1,0) [0|0] "" Vector__XXX
 SG_ VCRIGHT_occupantClassificationQF : 26|1@1+ (1,0) [0|0] "" Vector__XXX
 SG_ VCRIGHT_occupantClassification : 23|3@1+ (1,0) [0|0] "" Vector__XXX
 SG_ VCRIGHT_seatTrackPosition : 20|3@1+ (1,0) [0|0] "" Vector__XXX
 SG_ VCRIGHT_3RowRightOccupancyStatus : 18|2@1+ (1,0) [0|0] "" Vector__XXX
 SG_ VCRIGHT_3RowLeftOccupancyStatus : 16|2@1+ (1,0) [0|0] "" Vector__XXX
 SG_ VCRIGHT_3RowRightBuckleStatus : 14|2@1+ (1,0) [0|0] "" Vector__XXX
 SG_ VCRIGHT_3RowLeftBuckleStatus : 12|2@1+ (1,0) [0|0] "" Vector__XXX
 SG_ VCRIGHT_rearRightOccupancyStatus : 10|2@1+ (1,0) [0|0] "" Vector__XXX
 SG_ VCRIGHT_rearRightBuckleStatus : 8|2@1+ (1,0) [0|0] "" Vector__XXX
 SG_ VCRIGHT_rearCenterBuckleStatus : 5|2@1+ (1,0) [0|0] "" Vector__XXX
 SG_ VCRIGHT_frontBuckleStatus : 3|2@1+ (1,0) [0|0] "" Vector__XXX
 SG_ VCRIGHT_frontOccupancyStatus : 0|3@1+ (1,0) [0|0] "" Vector__XXX

BO_ 857 VCSEC_DeviceStatus: 8 Vector__XXX
 SG_ VCSEC_Device0Stationary m0 : 63|1@1+ (1,0) [0|0] "" Vector__XXX
 SG_ VCSEC_Device10Stationary m60 : 63|1@1+ (1,0) [0|0] "" Vector__XXX
 SG_ VCSEC_Device11Stationary m66 : 63|1@1+ (1,0) [0|0] "" Vector__XXX
 SG_ VCSEC_Device12Stationary m72 : 63|1@1+ (1,0) [0|0] "" Vector__XXX
 SG_ VCSEC_Device13Stationary m78 : 63|1@1+ (1,0) [0|0] "" Vector__XXX
 SG_ VCSEC_Device14Stationary m84 : 63|1@1+ (1,0) [0|0] "" Vector__XXX
 SG_ VCSEC_Device15Stationary m90 : 63|1@1+ (1,0) [0|0] "" Vector__XXX
 SG_ VCSEC_Device16Stationary m96 : 63|1@1+ (1,0) [0|0] "" Vector__XXX
 SG_ VCSEC_Device17Stationary m102 : 63|1@1+ (1,0) [0|0] "" Vector__XXX
 SG_ VCSEC_Device18Stationary m108 : 63|1@1+ (1,0) [0|0] "" Vector__XXX
 SG_ VCSEC_Device19Stationary m114 : 63|1@1+ (1,0) [0|0] "" Vector__XXX
 SG_ VCSEC_Device1Stationary m6 : 63|1@1+ (1,0) [0|0] "" Vector__XXX
 SG_ VCSEC_Device2Stationary m12 : 63|1@1+ (1,0) [0|0] "" Vector__XXX
 SG_ VCSEC_Device3Stationary m18 : 63|1@1+ (1,0) [0|0] "" Vector__XXX
 SG_ VCSEC_Device4Stationary m24 : 63|1@1+ (1,0) [0|0] "" Vector__XXX
 SG_ VCSEC_Device5Stationary m30 : 63|1@1+ (1,0) [0|0] "" Vector__XXX
 SG_ VCSEC_Device6Stationary m36 : 63|1@1+ (1,0) [0|0] "" Vector__XXX
 SG_ VCSEC_Device7Stationary m42 : 63|1@1+ (1,0) [0|0] "" Vector__XXX
 SG_ VCSEC_Device8Stationary m48 : 63|1@1+ (1,0) [0|0] "" Vector__XXX
 SG_ VCSEC_Device9Stationary m54 : 63|1@1+ (1,0) [0|0] "" Vector__XXX
 SG_ VCSEC_Device0BlacklistStatus m0 : 62|1@1+ (1,0) [0|0] "" Vector__XXX
 SG_ VCSEC_Device10BlacklistStatus m60 : 62|1@1+ (1,0) [0|0] "" Vector__XXX
 SG_ VCSEC_Device11BlacklistStatus m66 : 62|1@1+ (1,0) [0|0] "" Vector__XXX
 SG_ VCSEC_Device12BlacklistStatus m72 : 62|1@1+ (1,0) [0|0] "" Vector__XXX
 SG_ VCSEC_Device13BlacklistStatus m78 : 62|1@1+ (1,0) [0|0] "" Vector__XXX
 SG_ VCSEC_Device14BlacklistStatus m84 : 62|1@1+ (1,0) [0|0] "" Vector__XXX
 SG_ VCSEC_Device15BlacklistStatus m90 : 62|1@1+ (1,0) [0|0] "" Vector__XXX
 SG_ VCSEC_Device16BlacklistStatus m96 : 62|1@1+ (1,0) [0|0] "" Vector__XXX
 SG_ VCSEC_Device17BlacklistStatus m102 : 62|1@1+ (1,0) [0|0] "" Vector__XXX
 SG_ VCSEC_Device18BlacklistStatus m108 : 62|1@1+ (1,0) [0|0] "" Vector__XXX
 SG_ VCSEC_Device19BlacklistStatus m114 : 62|1@1+ (1,0) [0|0] "" Vector__XXX
 SG_ VCSEC_Device1BlacklistStatus m6 : 62|1@1+ (1,0) [0|0] "" Vector__XXX
 SG_ VCSEC_Device2BlacklistStatus m12 : 62|1@1+ (1,0) [0|0] "" Vector__XXX
 SG_ VCSEC_Device3BlacklistStatus m18 : 62|1@1+ (1,0) [0|0] "" Vector__XXX
 SG_ VCSEC_Device4BlacklistStatus m24 : 62|1@1+ (1,0) [0|0] "" Vector__XXX
 SG_ VCSEC_Device5BlacklistStatus m30 : 62|1@1+ (1,0) [0|0] "" Vector__XXX
 SG_ VCSEC_Device6BlacklistStatus m36 : 62|1@1+ (1,0) [0|0] "" Vector__XXX
 SG_ VCSEC_Device7BlacklistStatus m42 : 62|1@1+ (1,0) [0|0] "" Vector__XXX
 SG_ VCSEC_Device8BlacklistStatus m48 : 62|1@1+ (1,0) [0|0] "" Vector__XXX
 SG_ VCSEC_Device9BlacklistStatus m54 : 62|1@1+ (1,0) [0|0] "" Vector__XXX
 SG_ VCSEC_Device0Formfactor m0 : 57|5@1+ (1,0) [0|0] "" Vector__XXX
 SG_ VCSEC_Device10Formfactor m60 : 57|5@1+ (1,0) [0|0] "" Vector__XXX
 SG_ VCSEC_Device11Formfactor m66 : 57|5@1+ (1,0) [0|0] "" Vector__XXX
 SG_ VCSEC_Device12Formfactor m72 : 57|5@1+ (1,0) [0|0] "" Vector__XXX
 SG_ VCSEC_Device13Formfactor m78 : 57|5@1+ (1,0) [0|0] "" Vector__XXX
 SG_ VCSEC_Device14Formfactor m84 : 57|5@1+ (1,0) [0|0] "" Vector__XXX
 SG_ VCSEC_Device15Formfactor m90 : 57|5@1+ (1,0) [0|0] "" Vector__XXX
 SG_ VCSEC_Device16Formfactor m96 : 57|5@1+ (1,0) [0|0] "" Vector__XXX
 SG_ VCSEC_Device17Formfactor m102 : 57|5@1+ (1,0) [0|0] "" Vector__XXX
 SG_ VCSEC_Device18Formfactor m108 : 57|5@1+ (1,0) [0|0] "" Vector__XXX
 SG_ VCSEC_Device19Formfactor m114 : 57|5@1+ (1,0) [0|0] "" Vector__XXX
 SG_ VCSEC_Device1Formfactor m6 : 57|5@1+ (1,0) [0|0] "" Vector__XXX
 SG_ VCSEC_Device2Formfactor m12 : 57|5@1+ (1,0) [0|0] "" Vector__XXX
 SG_ VCSEC_Device3Formfactor m18 : 57|5@1+ (1,0) [0|0] "" Vector__XXX
 SG_ VCSEC_Device4Formfactor m24 : 57|5@1+ (1,0) [0|0] "" Vector__XXX
 SG_ VCSEC_Device5Formfactor m30 : 57|5@1+ (1,0) [0|0] "" Vector__XXX
 SG_ VCSEC_Device6Formfactor m36 : 57|5@1+ (1,0) [0|0] "" Vector__XXX
 SG_ VCSEC_Device7Formfactor m42 : 57|5@1+ (1,0) [0|0] "" Vector__XXX
 SG_ VCSEC_Device8Formfactor m48 : 57|5@1+ (1,0) [0|0] "" Vector__XXX
 SG_ VCSEC_Device9Formfactor m54 : 57|5@1+ (1,0) [0|0] "" Vector__XXX
 SG_ VCSEC_Device0BatteryLevel m0 : 49|8@1+ (0.015625,0) [0|0] "" Vector__XXX
 SG_ VCSEC_Device10BatteryLevel m60 : 49|8@1+ (0.015625,0) [0|0] "" Vector__XXX
 SG_ VCSEC_Device11BatteryLevel m66 : 49|8@1+ (0.015625,0) [0|0] "" Vector__XXX
 SG_ VCSEC_Device12BatteryLevel m72 : 49|8@1+ (0.015625,0) [0|0] "" Vector__XXX
 SG_ VCSEC_Device13BatteryLevel m78 : 49|8@1+ (0.015625,0) [0|0] "" Vector__XXX
 SG_ VCSEC_Device14BatteryLevel m84 : 49|8@1+ (0.015625,0) [0|0] "" Vector__XXX
 SG_ VCSEC_Device15BatteryLevel m90 : 49|8@1+ (0.015625,0) [0|0] "" Vector__XXX
 SG_ VCSEC_Device16BatteryLevel m96 : 49|8@1+ (0.015625,0) [0|0] "" Vector__XXX
 SG_ VCSEC_Device17BatteryLevel m102 : 49|8@1+ (0.015625,0) [0|0] "" Vector__XXX
 SG_ VCSEC_Device18BatteryLevel m108 : 49|8@1+ (0.015625,0) [0|0] "" Vector__XXX
 SG_ VCSEC_Device19BatteryLevel m114 : 49|8@1+ (0.015625,0) [0|0] "" Vector__XXX
 SG_ VCSEC_Device1BatteryLevel m6 : 49|8@1+ (0.015625,0) [0|0] "" Vector__XXX
 SG_ VCSEC_Device2BatteryLevel m12 : 49|8@1+ (0.015625,0) [0|0] "" Vector__XXX
 SG_ VCSEC_Device3BatteryLevel m18 : 49|8@1+ (0.015625,0) [0|0] "" Vector__XXX
 SG_ VCSEC_Device4BatteryLevel m24 : 49|8@1+ (0.015625,0) [0|0] "" Vector__XXX
 SG_ VCSEC_Device5BatteryLevel m30 : 49|8@1+ (0.015625,0) [0|0] "" Vector__XXX
 SG_ VCSEC_Device6BatteryLevel m36 : 49|8@1+ (0.015625,0) [0|0] "" Vector__XXX
 SG_ VCSEC_Device7BatteryLevel m42 : 49|8@1+ (0.015625,0) [0|0] "" Vector__XXX
 SG_ VCSEC_Device8BatteryLevel m48 : 49|8@1+ (0.015625,0) [0|0] "" Vector__XXX
 SG_ VCSEC_Device9BatteryLevel m54 : 49|8@1+ (0.015625,0) [0|0] "" Vector__XXX
 SG_ VCSEC_Device0OSVersion m0 : 37|12@1+ (1,0) [0|0] "" Vector__XXX
 SG_ VCSEC_Device10OSVersion m60 : 37|12@1+ (1,0) [0|0] "" Vector__XXX
 SG_ VCSEC_Device11OSVersion m66 : 37|12@1+ (1,0) [0|0] "" Vector__XXX
 SG_ VCSEC_Device12OSVersion m72 : 37|12@1+ (1,0) [0|0] "" Vector__XXX
 SG_ VCSEC_Device13OSVersion m78 : 37|12@1+ (1,0) [0|0] "" Vector__XXX
 SG_ VCSEC_Device14OSVersion m84 : 37|12@1+ (1,0) [0|0] "" Vector__XXX
 SG_ VCSEC_Device15OSVersion m90 : 37|12@1+ (1,0) [0|0] "" Vector__XXX
 SG_ VCSEC_Device16OSVersion m96 : 37|12@1+ (1,0) [0|0] "" Vector__XXX
 SG_ VCSEC_Device17OSVersion m102 : 37|12@1+ (1,0) [0|0] "" Vector__XXX
 SG_ VCSEC_Device18OSVersion m108 : 37|12@1+ (1,0) [0|0] "" Vector__XXX
 SG_ VCSEC_Device19OSVersion m114 : 37|12@1+ (1,0) [0|0] "" Vector__XXX
 SG_ VCSEC_Device1OSVersion m6 : 37|12@1+ (1,0) [0|0] "" Vector__XXX
 SG_ VCSEC_Device2OSVersion m12 : 37|12@1+ (1,0) [0|0] "" Vector__XXX
 SG_ VCSEC_Device3OSVersion m18 : 37|12@1+ (1,0) [0|0] "" Vector__XXX
 SG_ VCSEC_Device4OSVersion m24 : 37|12@1+ (1,0) [0|0] "" Vector__XXX
 SG_ VCSEC_Device5OSVersion m30 : 37|12@1+ (1,0) [0|0] "" Vector__XXX
 SG_ VCSEC_Device6OSVersion m36 : 37|12@1+ (1,0) [0|0] "" Vector__XXX
 SG_ VCSEC_Device7OSVersion m42 : 37|12@1+ (1,0) [0|0] "" Vector__XXX
 SG_ VCSEC_Device8OSVersion m48 : 37|12@1+ (1,0) [0|0] "" Vector__XXX
 SG_ VCSEC_Device9OSVersion m54 : 37|12@1+ (1,0) [0|0] "" Vector__XXX
 SG_ VCSEC_Device0CpuTime m1 : 34|30@1+ (1,0) [0|0] "" Vector__XXX
 SG_ VCSEC_Device10CpuTime m61 : 34|30@1+ (1,0) [0|0] "" Vector__XXX
 SG_ VCSEC_Device11CpuTime m67 : 34|30@1+ (1,0) [0|0] "" Vector__XXX
 SG_ VCSEC_Device12CpuTime m73 : 34|30@1+ (1,0) [0|0] "" Vector__XXX
 SG_ VCSEC_Device13CpuTime m79 : 34|30@1+ (1,0) [0|0] "" Vector__XXX
 SG_ VCSEC_Device14CpuTime m85 : 34|30@1+ (1,0) [0|0] "" Vector__XXX
 SG_ VCSEC_Device15CpuTime m91 : 34|30@1+ (1,0) [0|0] "" Vector__XXX
 SG_ VCSEC_Device16CpuTime m97 : 34|30@1+ (1,0) [0|0] "" Vector__XXX
 SG_ VCSEC_Device17CpuTime m103 : 34|30@1+ (1,0) [0|0] "" Vector__XXX
 SG_ VCSEC_Device18CpuTime m109 : 34|30@1+ (1,0) [0|0] "" Vector__XXX
 SG_ VCSEC_Device19CpuTime m115 : 34|30@1+ (1,0) [0|0] "" Vector__XXX
 SG_ VCSEC_Device1CpuTime m7 : 34|30@1+ (1,0) [0|0] "" Vector__XXX
 SG_ VCSEC_Device2CpuTime m13 : 34|30@1+ (1,0) [0|0] "" Vector__XXX
 SG_ VCSEC_Device3CpuTime m19 : 34|30@1+ (1,0) [0|0] "" Vector__XXX
 SG_ VCSEC_Device4CpuTime m25 : 34|30@1+ (1,0) [0|0] "" Vector__XXX
 SG_ VCSEC_Device5CpuTime m31 : 34|30@1+ (1,0) [0|0] "" Vector__XXX
 SG_ VCSEC_Device6CpuTime m37 : 34|30@1+ (1,0) [0|0] "" Vector__XXX
 SG_ VCSEC_Device7CpuTime m43 : 34|30@1+ (1,0) [0|0] "" Vector__XXX
 SG_ VCSEC_Device8CpuTime m49 : 34|30@1+ (1,0) [0|0] "" Vector__XXX
 SG_ VCSEC_Device9CpuTime m55 : 34|30@1+ (1,0) [0|0] "" Vector__XXX
 SG_ VCSEC_Device0BuildNumberHashBits m5 : 32|32@1+ (1,0) [0|0] "" Vector__XXX
 SG_ VCSEC_Device0Permissions m3 : 32|32@1+ (1,0) [0|0] "" Vector__XXX
 SG_ VCSEC_Device0SHA1 m2 : 32|32@1+ (1,0) [0|0] "" Vector__XXX
 SG_ VCSEC_Device0WLEntry m0 : 32|5@1+ (1,0) [0|0] "" Vector__XXX
 SG_ VCSEC_Device10BuildNumberHashBit m65 : 32|32@1+ (1,0) [0|0] "" Vector__XXX
 SG_ VCSEC_Device10Permissions m63 : 32|32@1+ (1,0) [0|0] "" Vector__XXX
 SG_ VCSEC_Device10SHA1 m62 : 32|32@1+ (1,0) [0|0] "" Vector__XXX
 SG_ VCSEC_Device10WLEntry m60 : 32|5@1+ (1,0) [0|0] "" Vector__XXX
 SG_ VCSEC_Device11BuildNumberHashBit m71 : 32|32@1+ (1,0) [0|0] "" Vector__XXX
 SG_ VCSEC_Device11Permissions m69 : 32|32@1+ (1,0) [0|0] "" Vector__XXX
 SG_ VCSEC_Device11SHA1 m68 : 32|32@1+ (1,0) [0|0] "" Vector__XXX
 SG_ VCSEC_Device11WLEntry m66 : 32|5@1+ (1,0) [0|0] "" Vector__XXX
 SG_ VCSEC_Device12BuildNumberHashBit m77 : 32|32@1+ (1,0) [0|0] "" Vector__XXX
 SG_ VCSEC_Device12Permissions m75 : 32|32@1+ (1,0) [0|0] "" Vector__XXX
 SG_ VCSEC_Device12SHA1 m74 : 32|32@1+ (1,0) [0|0] "" Vector__XXX
 SG_ VCSEC_Device12WLEntry m72 : 32|5@1+ (1,0) [0|0] "" Vector__XXX
 SG_ VCSEC_Device13BuildNumberHashBit m83 : 32|32@1+ (1,0) [0|0] "" Vector__XXX
 SG_ VCSEC_Device13Permissions m81 : 32|32@1+ (1,0) [0|0] "" Vector__XXX
 SG_ VCSEC_Device13SHA1 m80 : 32|32@1+ (1,0) [0|0] "" Vector__XXX
 SG_ VCSEC_Device13WLEntry m78 : 32|5@1+ (1,0) [0|0] "" Vector__XXX
 SG_ VCSEC_Device14BuildNumberHashBit m89 : 32|32@1+ (1,0) [0|0] "" Vector__XXX
 SG_ VCSEC_Device14Permissions m87 : 32|32@1+ (1,0) [0|0] "" Vector__XXX
 SG_ VCSEC_Device14SHA1 m86 : 32|32@1+ (1,0) [0|0] "" Vector__XXX
 SG_ VCSEC_Device14WLEntry m84 : 32|5@1+ (1,0) [0|0] "" Vector__XXX
 SG_ VCSEC_Device15BuildNumberHashBit m95 : 32|32@1+ (1,0) [0|0] "" Vector__XXX
 SG_ VCSEC_Device15Permissions m93 : 32|32@1+ (1,0) [0|0] "" Vector__XXX
 SG_ VCSEC_Device15SHA1 m92 : 32|32@1+ (1,0) [0|0] "" Vector__XXX
 SG_ VCSEC_Device15WLEntry m90 : 32|5@1+ (1,0) [0|0] "" Vector__XXX
 SG_ VCSEC_Device16BuildNumberHashBit m101 : 32|32@1+ (1,0) [0|0] "" Vector__XXX
 SG_ VCSEC_Device16Permissions m99 : 32|32@1+ (1,0) [0|0] "" Vector__XXX
 SG_ VCSEC_Device16SHA1 m98 : 32|32@1+ (1,0) [0|0] "" Vector__XXX
 SG_ VCSEC_Device16WLEntry m96 : 32|5@1+ (1,0) [0|0] "" Vector__XXX
 SG_ VCSEC_Device17BuildNumberHashBit m107 : 32|32@1+ (1,0) [0|0] "" Vector__XXX
 SG_ VCSEC_Device17Permissions m105 : 32|32@1+ (1,0) [0|0] "" Vector__XXX
 SG_ VCSEC_Device17SHA1 m104 : 32|32@1+ (1,0) [0|0] "" Vector__XXX
 SG_ VCSEC_Device17WLEntry m102 : 32|5@1+ (1,0) [0|0] "" Vector__XXX
 SG_ VCSEC_Device18BuildNumberHashBit m113 : 32|32@1+ (1,0) [0|0] "" Vector__XXX
 SG_ VCSEC_Device18Permissions m111 : 32|32@1+ (1,0) [0|0] "" Vector__XXX
 SG_ VCSEC_Device18SHA1 m110 : 32|32@1+ (1,0) [0|0] "" Vector__XXX
 SG_ VCSEC_Device18WLEntry m108 : 32|5@1+ (1,0) [0|0] "" Vector__XXX
 SG_ VCSEC_Device19BuildNumberHashBit m119 : 32|32@1+ (1,0) [0|0] "" Vector__XXX
 SG_ VCSEC_Device19Permissions m117 : 32|32@1+ (1,0) [0|0] "" Vector__XXX
 SG_ VCSEC_Device19SHA1 m116 : 32|32@1+ (1,0) [0|0] "" Vector__XXX
 SG_ VCSEC_Device19WLEntry m114 : 32|5@1+ (1,0) [0|0] "" Vector__XXX
 SG_ VCSEC_Device1BuildNumberHashBits m11 : 32|32@1+ (1,0) [0|0] "" Vector__XXX
 SG_ VCSEC_Device1Permissions m9 : 32|32@1+ (1,0) [0|0] "" Vector__XXX
 SG_ VCSEC_Device1SHA1 m8 : 32|32@1+ (1,0) [0|0] "" Vector__XXX
 SG_ VCSEC_Device1WLEntry m6 : 32|5@1+ (1,0) [0|0] "" Vector__XXX
 SG_ VCSEC_Device2BuildNumberHashBits m17 : 32|32@1+ (1,0) [0|0] "" Vector__XXX
 SG_ VCSEC_Device2Permissions m15 : 32|32@1+ (1,0) [0|0] "" Vector__XXX
 SG_ VCSEC_Device2SHA1 m14 : 32|32@1+ (1,0) [0|0] "" Vector__XXX
 SG_ VCSEC_Device2WLEntry m12 : 32|5@1+ (1,0) [0|0] "" Vector__XXX
 SG_ VCSEC_Device3BuildNumberHashBits m23 : 32|32@1+ (1,0) [0|0] "" Vector__XXX
 SG_ VCSEC_Device3Permissions m21 : 32|32@1+ (1,0) [0|0] "" Vector__XXX
 SG_ VCSEC_Device3SHA1 m20 : 32|32@1+ (1,0) [0|0] "" Vector__XXX
 SG_ VCSEC_Device3WLEntry m18 : 32|5@1+ (1,0) [0|0] "" Vector__XXX
 SG_ VCSEC_Device4BuildNumberHashBits m29 : 32|32@1+ (1,0) [0|0] "" Vector__XXX
 SG_ VCSEC_Device4Permissions m27 : 32|32@1+ (1,0) [0|0] "" Vector__XXX
 SG_ VCSEC_Device4SHA1 m26 : 32|32@1+ (1,0) [0|0] "" Vector__XXX
 SG_ VCSEC_Device4WLEntry m24 : 32|5@1+ (1,0) [0|0] "" Vector__XXX
 SG_ VCSEC_Device5BuildNumberHashBits m35 : 32|32@1+ (1,0) [0|0] "" Vector__XXX
 SG_ VCSEC_Device5Permissions m33 : 32|32@1+ (1,0) [0|0] "" Vector__XXX
 SG_ VCSEC_Device5SHA1 m32 : 32|32@1+ (1,0) [0|0] "" Vector__XXX
 SG_ VCSEC_Device5WLEntry m30 : 32|5@1+ (1,0) [0|0] "" Vector__XXX
 SG_ VCSEC_Device6BuildNumberHashBits m41 : 32|32@1+ (1,0) [0|0] "" Vector__XXX
 SG_ VCSEC_Device6Permissions m39 : 32|32@1+ (1,0) [0|0] "" Vector__XXX
 SG_ VCSEC_Device6SHA1 m38 : 32|32@1+ (1,0) [0|0] "" Vector__XXX
 SG_ VCSEC_Device6WLEntry m36 : 32|5@1+ (1,0) [0|0] "" Vector__XXX
 SG_ VCSEC_Device7BuildNumberHashBits m47 : 32|32@1+ (1,0) [0|0] "" Vector__XXX
 SG_ VCSEC_Device7Permissions m45 : 32|32@1+ (1,0) [0|0] "" Vector__XXX
 SG_ VCSEC_Device7SHA1 m44 : 32|32@1+ (1,0) [0|0] "" Vector__XXX
 SG_ VCSEC_Device7WLEntry m42 : 32|5@1+ (1,0) [0|0] "" Vector__XXX
 SG_ VCSEC_Device8BuildNumberHashBits m53 : 32|32@1+ (1,0) [0|0] "" Vector__XXX
 SG_ VCSEC_Device8Permissions m51 : 32|32@1+ (1,0) [0|0] "" Vector__XXX
 SG_ VCSEC_Device8SHA1 m50 : 32|32@1+ (1,0) [0|0] "" Vector__XXX
 SG_ VCSEC_Device8WLEntry m48 : 32|5@1+ (1,0) [0|0] "" Vector__XXX
 SG_ VCSEC_Device9BuildNumberHashBits m59 : 32|32@1+ (1,0) [0|0] "" Vector__XXX
 SG_ VCSEC_Device9Permissions m57 : 32|32@1+ (1,0) [0|0] "" Vector__XXX
 SG_ VCSEC_Device9SHA1 m56 : 32|32@1+ (1,0) [0|0] "" Vector__XXX
 SG_ VCSEC_Device9WLEntry m54 : 32|5@1+ (1,0) [0|0] "" Vector__XXX
 SG_ VCSEC_Device0Version m0 : 16|16@1+ (1,0) [0|0] "" Vector__XXX
 SG_ VCSEC_Device0WhitelistActiveTime m2 : 16|16@1+ (1,0) [0|0] "" Vector__XXX
 SG_ VCSEC_Device10Version m60 : 16|16@1+ (1,0) [0|0] "" Vector__XXX
 SG_ VCSEC_Device10WhitelistActiveTim m62 : 16|16@1+ (1,0) [0|0] "" Vector__XXX
 SG_ VCSEC_Device11Version m66 : 16|16@1+ (1,0) [0|0] "" Vector__XXX
 SG_ VCSEC_Device11WhitelistActiveTim m68 : 16|16@1+ (1,0) [0|0] "" Vector__XXX
 SG_ VCSEC_Device12Version m72 : 16|16@1+ (1,0) [0|0] "" Vector__XXX
 SG_ VCSEC_Device12WhitelistActiveTim m74 : 16|16@1+ (1,0) [0|0] "" Vector__XXX
 SG_ VCSEC_Device13Version m78 : 16|16@1+ (1,0) [0|0] "" Vector__XXX
 SG_ VCSEC_Device13WhitelistActiveTim m80 : 16|16@1+ (1,0) [0|0] "" Vector__XXX
 SG_ VCSEC_Device14Version m84 : 16|16@1+ (1,0) [0|0] "" Vector__XXX
 SG_ VCSEC_Device14WhitelistActiveTim m86 : 16|16@1+ (1,0) [0|0] "" Vector__XXX
 SG_ VCSEC_Device15Version m90 : 16|16@1+ (1,0) [0|0] "" Vector__XXX
 SG_ VCSEC_Device15WhitelistActiveTim m92 : 16|16@1+ (1,0) [0|0] "" Vector__XXX
 SG_ VCSEC_Device16Version m96 : 16|16@1+ (1,0) [0|0] "" Vector__XXX
 SG_ VCSEC_Device16WhitelistActiveTim m98 : 16|16@1+ (1,0) [0|0] "" Vector__XXX
 SG_ VCSEC_Device17Version m102 : 16|16@1+ (1,0) [0|0] "" Vector__XXX
 SG_ VCSEC_Device17WhitelistActiveTim m104 : 16|16@1+ (1,0) [0|0] "" Vector__XXX
 SG_ VCSEC_Device18Version m108 : 16|16@1+ (1,0) [0|0] "" Vector__XXX
 SG_ VCSEC_Device18WhitelistActiveTim m110 : 16|16@1+ (1,0) [0|0] "" Vector__XXX
 SG_ VCSEC_Device19Version m114 : 16|16@1+ (1,0) [0|0] "" Vector__XXX
 SG_ VCSEC_Device19WhitelistActiveTim m116 : 16|16@1+ (1,0) [0|0] "" Vector__XXX
 SG_ VCSEC_Device1Version m6 : 16|16@1+ (1,0) [0|0] "" Vector__XXX
 SG_ VCSEC_Device1WhitelistActiveTime m8 : 16|16@1+ (1,0) [0|0] "" Vector__XXX
 SG_ VCSEC_Device2Version m12 : 16|16@1+ (1,0) [0|0] "" Vector__XXX
 SG_ VCSEC_Device2WhitelistActiveTime m14 : 16|16@1+ (1,0) [0|0] "" Vector__XXX
 SG_ VCSEC_Device3Version m18 : 16|16@1+ (1,0) [0|0] "" Vector__XXX
 SG_ VCSEC_Device3WhitelistActiveTime m20 : 16|16@1+ (1,0) [0|0] "" Vector__XXX
 SG_ VCSEC_Device4Version m24 : 16|16@1+ (1,0) [0|0] "" Vector__XXX
 SG_ VCSEC_Device4WhitelistActiveTime m26 : 16|16@1+ (1,0) [0|0] "" Vector__XXX
 SG_ VCSEC_Device5Version m30 : 16|16@1+ (1,0) [0|0] "" Vector__XXX
 SG_ VCSEC_Device5WhitelistActiveTime m32 : 16|16@1+ (1,0) [0|0] "" Vector__XXX
 SG_ VCSEC_Device6Version m36 : 16|16@1+ (1,0) [0|0] "" Vector__XXX
 SG_ VCSEC_Device6WhitelistActiveTime m38 : 16|16@1+ (1,0) [0|0] "" Vector__XXX
 SG_ VCSEC_Device7Version m42 : 16|16@1+ (1,0) [0|0] "" Vector__XXX
 SG_ VCSEC_Device7WhitelistActiveTime m44 : 16|16@1+ (1,0) [0|0] "" Vector__XXX
 SG_ VCSEC_Device8Version m48 : 16|16@1+ (1,0) [0|0] "" Vector__XXX
 SG_ VCSEC_Device8WhitelistActiveTime m50 : 16|16@1+ (1,0) [0|0] "" Vector__XXX
 SG_ VCSEC_Device9Version m54 : 16|16@1+ (1,0) [0|0] "" Vector__XXX
 SG_ VCSEC_Device9WhitelistActiveTime m56 : 16|16@1+ (1,0) [0|0] "" Vector__XXX
 SG_ VCSEC_Device0SELockedDown m0 : 15|1@1+ (1,0) [0|0] "" Vector__XXX
 SG_ VCSEC_Device10SELockedDown m60 : 15|1@1+ (1,0) [0|0] "" Vector__XXX
 SG_ VCSEC_Device11SELockedDown m66 : 15|1@1+ (1,0) [0|0] "" Vector__XXX
 SG_ VCSEC_Device12SELockedDown m72 : 15|1@1+ (1,0) [0|0] "" Vector__XXX
 SG_ VCSEC_Device13SELockedDown m78 : 15|1@1+ (1,0) [0|0] "" Vector__XXX
 SG_ VCSEC_Device14SELockedDown m84 : 15|1@1+ (1,0) [0|0] "" Vector__XXX
 SG_ VCSEC_Device15SELockedDown m90 : 15|1@1+ (1,0) [0|0] "" Vector__XXX
 SG_ VCSEC_Device16SELockedDown m96 : 15|1@1+ (1,0) [0|0] "" Vector__XXX
 SG_ VCSEC_Device17SELockedDown m102 : 15|1@1+ (1,0) [0|0] "" Vector__XXX
 SG_ VCSEC_Device18SELockedDown m108 : 15|1@1+ (1,0) [0|0] "" Vector__XXX
 SG_ VCSEC_Device19SELockedDown m114 : 15|1@1+ (1,0) [0|0] "" Vector__XXX
 SG_ VCSEC_Device1SELockedDown m6 : 15|1@1+ (1,0) [0|0] "" Vector__XXX
 SG_ VCSEC_Device2SELockedDown m12 : 15|1@1+ (1,0) [0|0] "" Vector__XXX
 SG_ VCSEC_Device3SELockedDown m18 : 15|1@1+ (1,0) [0|0] "" Vector__XXX
 SG_ VCSEC_Device4SELockedDown m24 : 15|1@1+ (1,0) [0|0] "" Vector__XXX
 SG_ VCSEC_Device5SELockedDown m30 : 15|1@1+ (1,0) [0|0] "" Vector__XXX
 SG_ VCSEC_Device6SELockedDown m36 : 15|1@1+ (1,0) [0|0] "" Vector__XXX
 SG_ VCSEC_Device7SELockedDown m42 : 15|1@1+ (1,0) [0|0] "" Vector__XXX
 SG_ VCSEC_Device8SELockedDown m48 : 15|1@1+ (1,0) [0|0] "" Vector__XXX
 SG_ VCSEC_Device9SELockedDown m54 : 15|1@1+ (1,0) [0|0] "" Vector__XXX
 SG_ VCSEC_Device0Impermanent m0 : 14|1@1+ (1,0) [0|0] "" Vector__XXX
 SG_ VCSEC_Device10Impermanent m60 : 14|1@1+ (1,0) [0|0] "" Vector__XXX
 SG_ VCSEC_Device11Impermanent m66 : 14|1@1+ (1,0) [0|0] "" Vector__XXX
 SG_ VCSEC_Device12Impermanent m72 : 14|1@1+ (1,0) [0|0] "" Vector__XXX
 SG_ VCSEC_Device13Impermanent m78 : 14|1@1+ (1,0) [0|0] "" Vector__XXX
 SG_ VCSEC_Device14Impermanent m84 : 14|1@1+ (1,0) [0|0] "" Vector__XXX
 SG_ VCSEC_Device15Impermanent m90 : 14|1@1+ (1,0) [0|0] "" Vector__XXX
 SG_ VCSEC_Device16Impermanent m96 : 14|1@1+ (1,0) [0|0] "" Vector__XXX
 SG_ VCSEC_Device17Impermanent m102 : 14|1@1+ (1,0) [0|0] "" Vector__XXX
 SG_ VCSEC_Device18Impermanent m108 : 14|1@1+ (1,0) [0|0] "" Vector__XXX
 SG_ VCSEC_Device19Impermanent m114 : 14|1@1+ (1,0) [0|0] "" Vector__XXX
 SG_ VCSEC_Device1Impermanent m6 : 14|1@1+ (1,0) [0|0] "" Vector__XXX
 SG_ VCSEC_Device2Impermanent m12 : 14|1@1+ (1,0) [0|0] "" Vector__XXX
 SG_ VCSEC_Device3Impermanent m18 : 14|1@1+ (1,0) [0|0] "" Vector__XXX
 SG_ VCSEC_Device4Impermanent m24 : 14|1@1+ (1,0) [0|0] "" Vector__XXX
 SG_ VCSEC_Device5Impermanent m30 : 14|1@1+ (1,0) [0|0] "" Vector__XXX
 SG_ VCSEC_Device6Impermanent m36 : 14|1@1+ (1,0) [0|0] "" Vector__XXX
 SG_ VCSEC_Device7Impermanent m42 : 14|1@1+ (1,0) [0|0] "" Vector__XXX
 SG_ VCSEC_Device8Impermanent m48 : 14|1@1+ (1,0) [0|0] "" Vector__XXX
 SG_ VCSEC_Device9Impermanent m54 : 14|1@1+ (1,0) [0|0] "" Vector__XXX
 SG_ VCSEC_Device0Role m2 : 9|4@1+ (1,0) [0|0] "" Vector__XXX
 SG_ VCSEC_Device10Role m62 : 9|4@1+ (1,0) [0|0] "" Vector__XXX
 SG_ VCSEC_Device11Role m68 : 9|4@1+ (1,0) [0|0] "" Vector__XXX
 SG_ VCSEC_Device12Role m74 : 9|4@1+ (1,0) [0|0] "" Vector__XXX
 SG_ VCSEC_Device13Role m80 : 9|4@1+ (1,0) [0|0] "" Vector__XXX
 SG_ VCSEC_Device14Role m86 : 9|4@1+ (1,0) [0|0] "" Vector__XXX
 SG_ VCSEC_Device15Role m92 : 9|4@1+ (1,0) [0|0] "" Vector__XXX
 SG_ VCSEC_Device16Role m98 : 9|4@1+ (1,0) [0|0] "" Vector__XXX
 SG_ VCSEC_Device17Role m104 : 9|4@1+ (1,0) [0|0] "" Vector__XXX
 SG_ VCSEC_Device18Role m110 : 9|4@1+ (1,0) [0|0] "" Vector__XXX
 SG_ VCSEC_Device19Role m116 : 9|4@1+ (1,0) [0|0] "" Vector__XXX
 SG_ VCSEC_Device1Role m8 : 9|4@1+ (1,0) [0|0] "" Vector__XXX
 SG_ VCSEC_Device2Role m14 : 9|4@1+ (1,0) [0|0] "" Vector__XXX
 SG_ VCSEC_Device3Role m20 : 9|4@1+ (1,0) [0|0] "" Vector__XXX
 SG_ VCSEC_Device4Role m26 : 9|4@1+ (1,0) [0|0] "" Vector__XXX
 SG_ VCSEC_Device5Role m32 : 9|4@1+ (1,0) [0|0] "" Vector__XXX
 SG_ VCSEC_Device6Role m38 : 9|4@1+ (1,0) [0|0] "" Vector__XXX
 SG_ VCSEC_Device7Role m44 : 9|4@1+ (1,0) [0|0] "" Vector__XXX
 SG_ VCSEC_Device8Role m50 : 9|4@1+ (1,0) [0|0] "" Vector__XXX
 SG_ VCSEC_Device9Role m56 : 9|4@1+ (1,0) [0|0] "" Vector__XXX
 SG_ VCSEC_Device0Bonded m2 : 8|1@1+ (1,0) [0|0] "" Vector__XXX
 SG_ VCSEC_Device0ManufacturerHashBit m5 : 8|24@1+ (1,0) [0|0] "" Vector__XXX
 SG_ VCSEC_Device0ModelHash m4 : 8|56@1+ (1,0) [0|0] "" Vector__XXX
 SG_ VCSEC_Device10Bonded m62 : 8|1@1+ (1,0) [0|0] "" Vector__XXX
 SG_ VCSEC_Device10ManufacturerHashBi m65 : 8|24@1+ (1,0) [0|0] "" Vector__XXX
 SG_ VCSEC_Device10ModelHash m64 : 8|56@1+ (1,0) [0|0] "" Vector__XXX
 SG_ VCSEC_Device11Bonded m68 : 8|1@1+ (1,0) [0|0] "" Vector__XXX
 SG_ VCSEC_Device11ManufacturerHashBi m71 : 8|24@1+ (1,0) [0|0] "" Vector__XXX
 SG_ VCSEC_Device11ModelHash m70 : 8|56@1+ (1,0) [0|0] "" Vector__XXX
 SG_ VCSEC_Device12Bonded m74 : 8|1@1+ (1,0) [0|0] "" Vector__XXX
 SG_ VCSEC_Device12ManufacturerHashBi m77 : 8|24@1+ (1,0) [0|0] "" Vector__XXX
 SG_ VCSEC_Device12ModelHash m76 : 8|56@1+ (1,0) [0|0] "" Vector__XXX
 SG_ VCSEC_Device13Bonded m80 : 8|1@1+ (1,0) [0|0] "" Vector__XXX
 SG_ VCSEC_Device13ManufacturerHashBi m83 : 8|24@1+ (1,0) [0|0] "" Vector__XXX
 SG_ VCSEC_Device13ModelHash m82 : 8|56@1+ (1,0) [0|0] "" Vector__XXX
 SG_ VCSEC_Device14Bonded m86 : 8|1@1+ (1,0) [0|0] "" Vector__XXX
 SG_ VCSEC_Device14ManufacturerHashBi m89 : 8|24@1+ (1,0) [0|0] "" Vector__XXX
 SG_ VCSEC_Device14ModelHash m88 : 8|56@1+ (1,0) [0|0] "" Vector__XXX
 SG_ VCSEC_Device15Bonded m92 : 8|1@1+ (1,0) [0|0] "" Vector__XXX
 SG_ VCSEC_Device15ManufacturerHashBi m95 : 8|24@1+ (1,0) [0|0] "" Vector__XXX
 SG_ VCSEC_Device15ModelHash m94 : 8|56@1+ (1,0) [0|0] "" Vector__XXX
 SG_ VCSEC_Device16Bonded m98 : 8|1@1+ (1,0) [0|0] "" Vector__XXX
 SG_ VCSEC_Device16ManufacturerHashBi m101 : 8|24@1+ (1,0) [0|0] "" Vector__XXX
 SG_ VCSEC_Device16ModelHash m100 : 8|56@1+ (1,0) [0|0] "" Vector__XXX
 SG_ VCSEC_Device17Bonded m104 : 8|1@1+ (1,0) [0|0] "" Vector__XXX
 SG_ VCSEC_Device17ManufacturerHashBi m107 : 8|24@1+ (1,0) [0|0] "" Vector__XXX
 SG_ VCSEC_Device17ModelHash m106 : 8|56@1+ (1,0) [0|0] "" Vector__XXX
 SG_ VCSEC_Device18Bonded m110 : 8|1@1+ (1,0) [0|0] "" Vector__XXX
 SG_ VCSEC_Device18ManufacturerHashBi m113 : 8|24@1+ (1,0) [0|0] "" Vector__XXX
 SG_ VCSEC_Device18ModelHash m112 : 8|56@1+ (1,0) [0|0] "" Vector__XXX
 SG_ VCSEC_Device19Bonded m116 : 8|1@1+ (1,0) [0|0] "" Vector__XXX
 SG_ VCSEC_Device19ManufacturerHashBi m119 : 8|24@1+ (1,0) [0|0] "" Vector__XXX
 SG_ VCSEC_Device19ModelHash m118 : 8|56@1+ (1,0) [0|0] "" Vector__XXX
 SG_ VCSEC_Device1Bonded m8 : 8|1@1+ (1,0) [0|0] "" Vector__XXX
 SG_ VCSEC_Device1ManufacturerHashBit m11 : 8|24@1+ (1,0) [0|0] "" Vector__XXX
 SG_ VCSEC_Device1ModelHash m10 : 8|56@1+ (1,0) [0|0] "" Vector__XXX
 SG_ VCSEC_Device2Bonded m14 : 8|1@1+ (1,0) [0|0] "" Vector__XXX
 SG_ VCSEC_Device2ManufacturerHashBit m17 : 8|24@1+ (1,0) [0|0] "" Vector__XXX
 SG_ VCSEC_Device2ModelHash m16 : 8|56@1+ (1,0) [0|0] "" Vector__XXX
 SG_ VCSEC_Device3Bonded m20 : 8|1@1+ (1,0) [0|0] "" Vector__XXX
 SG_ VCSEC_Device3ManufacturerHashBit m23 : 8|24@1+ (1,0) [0|0] "" Vector__XXX
 SG_ VCSEC_Device3ModelHash m22 : 8|56@1+ (1,0) [0|0] "" Vector__XXX
 SG_ VCSEC_Device4Bonded m26 : 8|1@1+ (1,0) [0|0] "" Vector__XXX
 SG_ VCSEC_Device4ManufacturerHashBit m29 : 8|24@1+ (1,0) [0|0] "" Vector__XXX
 SG_ VCSEC_Device4ModelHash m28 : 8|56@1+ (1,0) [0|0] "" Vector__XXX
 SG_ VCSEC_Device5Bonded m32 : 8|1@1+ (1,0) [0|0] "" Vector__XXX
 SG_ VCSEC_Device5ManufacturerHashBit m35 : 8|24@1+ (1,0) [0|0] "" Vector__XXX
 SG_ VCSEC_Device5ModelHash m34 : 8|56@1+ (1,0) [0|0] "" Vector__XXX
 SG_ VCSEC_Device6Bonded m38 : 8|1@1+ (1,0) [0|0] "" Vector__XXX
 SG_ VCSEC_Device6ManufacturerHashBit m41 : 8|24@1+ (1,0) [0|0] "" Vector__XXX
 SG_ VCSEC_Device6ModelHash m40 : 8|56@1+ (1,0) [0|0] "" Vector__XXX
 SG_ VCSEC_Device7Bonded m44 : 8|1@1+ (1,0) [0|0] "" Vector__XXX
 SG_ VCSEC_Device7ManufacturerHashBit m47 : 8|24@1+ (1,0) [0|0] "" Vector__XXX
 SG_ VCSEC_Device7ModelHash m46 : 8|56@1+ (1,0) [0|0] "" Vector__XXX
 SG_ VCSEC_Device8Bonded m50 : 8|1@1+ (1,0) [0|0] "" Vector__XXX
 SG_ VCSEC_Device8ManufacturerHashBit m53 : 8|24@1+ (1,0) [0|0] "" Vector__XXX
 SG_ VCSEC_Device8ModelHash m52 : 8|56@1+ (1,0) [0|0] "" Vector__XXX
 SG_ VCSEC_Device9Bonded m56 : 8|1@1+ (1,0) [0|0] "" Vector__XXX
 SG_ VCSEC_Device9ManufacturerHashBit m59 : 8|24@1+ (1,0) [0|0] "" Vector__XXX
 SG_ VCSEC_Device9ModelHash m58 : 8|56@1+ (1,0) [0|0] "" Vector__XXX
 SG_ VCSEC_Device0AuthResponseTime m0 : 7|7@1+ (50,0) [0|0] "" Vector__XXX
 SG_ VCSEC_Device0AwakeTime m1 : 7|27@1+ (1,0) [0|0] "" Vector__XXX
 SG_ VCSEC_Device10AuthResponseTime m60 : 7|7@1+ (50,0) [0|0] "" Vector__XXX
 SG_ VCSEC_Device10AwakeTime m61 : 7|27@1+ (1,0) [0|0] "" Vector__XXX
 SG_ VCSEC_Device11AuthResponseTime m66 : 7|7@1+ (50,0) [0|0] "" Vector__XXX
 SG_ VCSEC_Device11AwakeTime m67 : 7|27@1+ (1,0) [0|0] "" Vector__XXX
 SG_ VCSEC_Device12AuthResponseTime m72 : 7|7@1+ (50,0) [0|0] "" Vector__XXX
 SG_ VCSEC_Device12AwakeTime m73 : 7|27@1+ (1,0) [0|0] "" Vector__XXX
 SG_ VCSEC_Device13AuthResponseTime m78 : 7|7@1+ (50,0) [0|0] "" Vector__XXX
 SG_ VCSEC_Device13AwakeTime m79 : 7|27@1+ (1,0) [0|0] "" Vector__XXX
 SG_ VCSEC_Device14AuthResponseTime m84 : 7|7@1+ (50,0) [0|0] "" Vector__XXX
 SG_ VCSEC_Device14AwakeTime m85 : 7|27@1+ (1,0) [0|0] "" Vector__XXX
 SG_ VCSEC_Device15AuthResponseTime m90 : 7|7@1+ (50,0) [0|0] "" Vector__XXX
 SG_ VCSEC_Device15AwakeTime m91 : 7|27@1+ (1,0) [0|0] "" Vector__XXX
 SG_ VCSEC_Device16AuthResponseTime m96 : 7|7@1+ (50,0) [0|0] "" Vector__XXX
 SG_ VCSEC_Device16AwakeTime m97 : 7|27@1+ (1,0) [0|0] "" Vector__XXX
 SG_ VCSEC_Device17AuthResponseTime m102 : 7|7@1+ (50,0) [0|0] "" Vector__XXX
 SG_ VCSEC_Device17AwakeTime m103 : 7|27@1+ (1,0) [0|0] "" Vector__XXX
 SG_ VCSEC_Device18AuthResponseTime m108 : 7|7@1+ (50,0) [0|0] "" Vector__XXX
 SG_ VCSEC_Device18AwakeTime m109 : 7|27@1+ (1,0) [0|0] "" Vector__XXX
 SG_ VCSEC_Device19AuthResponseTime m114 : 7|7@1+ (50,0) [0|0] "" Vector__XXX
 SG_ VCSEC_Device19AwakeTime m115 : 7|27@1+ (1,0) [0|0] "" Vector__XXX
 SG_ VCSEC_Device1AuthResponseTime m6 : 7|7@1+ (50,0) [0|0] "" Vector__XXX
 SG_ VCSEC_Device1AwakeTime m7 : 7|27@1+ (1,0) [0|0] "" Vector__XXX
 SG_ VCSEC_Device2AuthResponseTime m12 : 7|7@1+ (50,0) [0|0] "" Vector__XXX
 SG_ VCSEC_Device2AwakeTime m13 : 7|27@1+ (1,0) [0|0] "" Vector__XXX
 SG_ VCSEC_Device3AuthResponseTime m18 : 7|7@1+ (50,0) [0|0] "" Vector__XXX
 SG_ VCSEC_Device3AwakeTime m19 : 7|27@1+ (1,0) [0|0] "" Vector__XXX
 SG_ VCSEC_Device4AuthResponseTime m24 : 7|7@1+ (50,0) [0|0] "" Vector__XXX
 SG_ VCSEC_Device4AwakeTime m25 : 7|27@1+ (1,0) [0|0] "" Vector__XXX
 SG_ VCSEC_Device5AuthResponseTime m30 : 7|7@1+ (50,0) [0|0] "" Vector__XXX
 SG_ VCSEC_Device5AwakeTime m31 : 7|27@1+ (1,0) [0|0] "" Vector__XXX
 SG_ VCSEC_Device6AuthResponseTime m36 : 7|7@1+ (50,0) [0|0] "" Vector__XXX
 SG_ VCSEC_Device6AwakeTime m37 : 7|27@1+ (1,0) [0|0] "" Vector__XXX
 SG_ VCSEC_Device7AuthResponseTime m42 : 7|7@1+ (50,0) [0|0] "" Vector__XXX
 SG_ VCSEC_Device7AwakeTime m43 : 7|27@1+ (1,0) [0|0] "" Vector__XXX
 SG_ VCSEC_Device8AuthResponseTime m48 : 7|7@1+ (50,0) [0|0] "" Vector__XXX
 SG_ VCSEC_Device8AwakeTime m49 : 7|27@1+ (1,0) [0|0] "" Vector__XXX
 SG_ VCSEC_Device9AuthResponseTime m54 : 7|7@1+ (50,0) [0|0] "" Vector__XXX
 SG_ VCSEC_Device9AwakeTime m55 : 7|27@1+ (1,0) [0|0] "" Vector__XXX
 SG_ VCSEC_DeviceStatusIndex M : 0|7@1+ (1,0) [0|0] "" Vector__XXX

BO_ 969 VCSEC_BLEEndpointInfo: 8 Vector__XXX
 SG_ VCSEC_BLECENTERUsageID m1 : 40|16@1+ (1,0) [0|0] "" Vector__XXX
 SG_ VCSEC_BLELEFTUsageID m4 : 40|16@1+ (1,0) [0|0] "" Vector__XXX
 SG_ VCSEC_BLEREARUsageID m10 : 40|16@1+ (1,0) [0|0] "" Vector__XXX
 SG_ VCSEC_BLERIGHTUsageID m7 : 40|16@1+ (1,0) [0|0] "" Vector__XXX
 SG_ VCSEC_BLECENTERAssemblyID m1 : 32|8@1+ (1,0) [0|0] "" Vector__XXX
 SG_ VCSEC_BLELEFTAssemblyID m4 : 32|8@1+ (1,0) [0|0] "" Vector__XXX
 SG_ VCSEC_BLEREARAssemblyID m10 : 32|8@1+ (1,0) [0|0] "" Vector__XXX
 SG_ VCSEC_BLERIGHTAssemblyID m7 : 32|8@1+ (1,0) [0|0] "" Vector__XXX
 SG_ VCSEC_BLECENTERPcbaID m1 : 24|8@1+ (1,0) [0|0] "" Vector__XXX
 SG_ VCSEC_BLELEFTPcbaID m4 : 24|8@1+ (1,0) [0|0] "" Vector__XXX
 SG_ VCSEC_BLEREARPcbaID m10 : 24|8@1+ (1,0) [0|0] "" Vector__XXX
 SG_ VCSEC_BLERIGHTPcbaID m7 : 24|8@1+ (1,0) [0|0] "" Vector__XXX
 SG_ VCSEC_BLECENTERAppGitHashByte m0 : 8|56@1+ (1,0) [0|0] "" Vector__XXX
 SG_ VCSEC_BLECENTERComponentID m1 : 8|16@1+ (1,0) [0|0] "" Vector__XXX
 SG_ VCSEC_BLECENTERCrc m2 : 8|32@1+ (1,0) [0|0] "" Vector__XXX
 SG_ VCSEC_BLELEFTAppGitHashByte m3 : 8|56@1+ (1,0) [0|0] "" Vector__XXX
 SG_ VCSEC_BLELEFTComponentID m4 : 8|16@1+ (1,0) [0|0] "" Vector__XXX
 SG_ VCSEC_BLELEFTCrc m5 : 8|32@1+ (1,0) [0|0] "" Vector__XXX
 SG_ VCSEC_BLEREARAppGitHashByte m9 : 8|56@1+ (1,0) [0|0] "" Vector__XXX
 SG_ VCSEC_BLEREARComponentID m10 : 8|16@1+ (1,0) [0|0] "" Vector__XXX
 SG_ VCSEC_BLEREARCrc m11 : 8|32@1+ (1,0) [0|0] "" Vector__XXX
 SG_ VCSEC_BLERIGHTAppGitHashByte m6 : 8|56@1+ (1,0) [0|0] "" Vector__XXX
 SG_ VCSEC_BLERIGHTComponentID m7 : 8|16@1+ (1,0) [0|0] "" Vector__XXX
 SG_ VCSEC_BLERIGHTCrc m8 : 8|32@1+ (1,0) [0|0] "" Vector__XXX
 SG_ VCSEC_BLEEndpointInfoIndex M : 0|8@1+ (1,0) [0|0] "" Vector__XXX

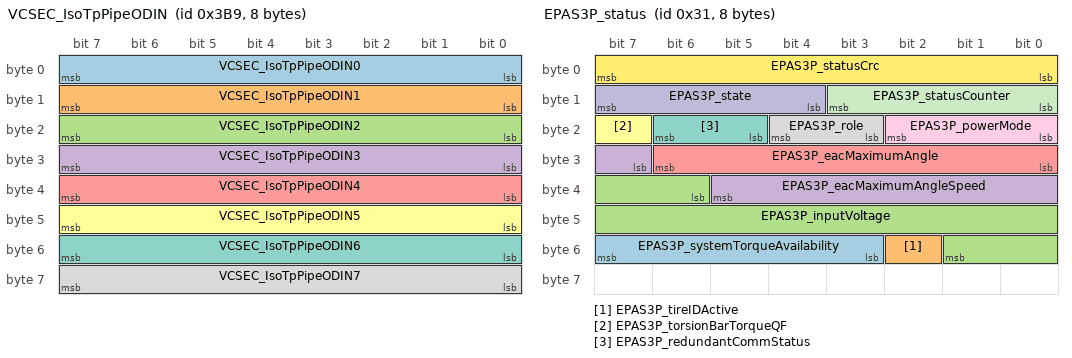
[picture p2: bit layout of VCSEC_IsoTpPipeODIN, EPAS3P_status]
BO_ 953 VCSEC_IsoTpPipeODIN: 8 VEH
 SG_ VCSEC_IsoTpPipeODIN0: 0|8@1+ (1,0) [0|0] "" X
 SG_ VCSEC_IsoTpPipeODIN1: 8|8@1+ (1,0) [0|0] "" X
 SG_ VCSEC_IsoTpPipeODIN2: 16|8@1+ (1,0) [0|0] "" X
 SG_ VCSEC_IsoTpPipeODIN3: 24|8@1+ (1,0) [0|0] "" X
 SG_ VCSEC_IsoTpPipeODIN4: 32|8@1+ (1,0) [0|0] "" X
 SG_ VCSEC_IsoTpPipeODIN5: 40|8@1+ (1,0) [0|0] "" X
 SG_ VCSEC_IsoTpPipeODIN6: 48|8@1+ (1,0) [0|0] "" X
 SG_ VCSEC_IsoTpPipeODIN7: 56|8@1+ (1,0) [0|0] "" X

BO_ 473 VCSEC_IsoTpUDPPipeUI: 3 Vector__XXX
 SG_ VCSEC_IsoTpUDPPipeUI2 : 16|8@1+ (1,0) [0|0] "" Vector__XXX
 SG_ VCSEC_IsoTpUDPPipeUI1 : 8|8@1+ (1,0) [0|0] "" Vector__XXX
 SG_ VCSEC_IsoTpUDPPipeUI0 : 0|8@1+ (1,0) [0|0] "" Vector__XXX

BO_ 1017 VCSEC_alertMatrix: 8 Vector__XXX
 SG_ VCSEC_a060_engineeringBuild m0 : 63|1@1+ (1,0) [0|0] "" Vector__XXX
 SG_ VCSEC_a120_DI_DRIVE_MIA m1 : 63|1@1+ (1,0) [0|0] "" Vector__XXX
 SG_ VCSEC_a180_wlistRemovedPermissio m2 : 63|1@1+ (1,0) [0|0] "" Vector__XXX
 SG_ VCSEC_a240_noKeysPaired m3 : 63|1@1+ (1,0) [0|0] "" Vector__XXX
 SG_ VCSEC_a300_scheduleItKeyAdded m4 : 63|1@1+ (1,0) [0|0] "" Vector__XXX
 SG_ VCSEC_a480_handlePullWithoutAuth m7 : 63|1@1+ (1,0) [0|0] "" Vector__XXX
 SG_ VCSEC_a540_dummyAlertMax m8 : 63|1@1+ (1,0) [0|0] "" Vector__XXX
 SG_ VCSEC_a059_inputResistanceHigh m0 : 62|1@1+ (1,0) [0|0] "" Vector__XXX
 SG_ VCSEC_a119_SCCM_MIA m1 : 62|1@1+ (1,0) [0|0] "" Vector__XXX
 SG_ VCSEC_a179_InfotainmentNotPaired m2 : 62|1@1+ (1,0) [0|0] "" Vector__XXX
 SG_ VCSEC_a239_TPMSIdleConnection m3 : 62|1@1+ (1,0) [0|0] "" Vector__XXX
 SG_ VCSEC_a479_handlePullWithoutAuth m7 : 62|1@1+ (1,0) [0|0] "" Vector__XXX
 SG_ VCSEC_a058_inputRHighSyncDebug m0 : 61|1@1+ (1,0) [0|0] "" Vector__XXX
 SG_ VCSEC_a118_VCFRONT_MIA m1 : 61|1@1+ (1,0) [0|0] "" Vector__XXX
 SG_ VCSEC_a178_whitelistRemovedKey m2 : 61|1@1+ (1,0) [0|0] "" Vector__XXX
 SG_ VCSEC_a238_TPMSLocationsUpdated m3 : 61|1@1+ (1,0) [0|0] "" Vector__XXX
 SG_ VCSEC_a478_handlePullWithoutAuth m7 : 61|1@1+ (1,0) [0|0] "" Vector__XXX
 SG_ VCSEC_a057_HVP_MIA m0 : 60|1@1+ (1,0) [0|0] "" Vector__XXX
 SG_ VCSEC_a117_VCLEFT_MIA m1 : 60|1@1+ (1,0) [0|0] "" Vector__XXX
 SG_ VCSEC_a177_whitelistAddedKey m2 : 60|1@1+ (1,0) [0|0] "" Vector__XXX
 SG_ VCSEC_a237_keyNotReadyToReceiveI m3 : 60|1@1+ (1,0) [0|0] "" Vector__XXX
 SG_ VCSEC_a477_phoneStartedBonding m7 : 60|1@1+ (1,0) [0|0] "" Vector__XXX
 SG_ VCSEC_a116_VCRIGHT_MIA m1 : 59|1@1+ (1,0) [0|0] "" Vector__XXX
 SG_ VCSEC_a236_keyIdentificationMaxA m3 : 59|1@1+ (1,0) [0|0] "" Vector__XXX
 SG_ VCSEC_a476_handlePullWithoutAuth m7 : 59|1@1+ (1,0) [0|0] "" Vector__XXX
 SG_ VCSEC_a115_VCSEC_MIA m1 : 58|1@1+ (1,0) [0|0] "" Vector__XXX
 SG_ VCSEC_a175_BLEUnexpectedResetRe m2 : 58|1@1+ (1,0) [0|0] "" Vector__XXX
 SG_ VCSEC_a235_presentWithoutHandleP m3 : 58|1@1+ (1,0) [0|0] "" Vector__XXX
 SG_ VCSEC_a475_handlePullWithoutAuth m7 : 58|1@1+ (1,0) [0|0] "" Vector__XXX
 SG_ VCSEC_a114_ESP_MIA m1 : 57|1@1+ (1,0) [0|0] "" Vector__XXX
 SG_ VCSEC_a174_BLEUnexpectedResetRi m2 : 57|1@1+ (1,0) [0|0] "" Vector__XXX
 SG_ VCSEC_a474_handlePullWithoutAuth m7 : 57|1@1+ (1,0) [0|0] "" Vector__XXX
 SG_ VCSEC_a113_UI_MIA m1 : 56|1@1+ (1,0) [0|0] "" Vector__XXX
 SG_ VCSEC_a173_BLEUnexpectedResetL m2 : 56|1@1+ (1,0) [0|0] "" Vector__XXX
 SG_ VCSEC_a473_handlePullWithoutAuth m7 : 56|1@1+ (1,0) [0|0] "" Vector__XXX
 SG_ VCSEC_a112_EPBL_MIA m1 : 55|1@1+ (1,0) [0|0] "" Vector__XXX
 SG_ VCSEC_a172_BLEUnexpectedResetC m2 : 55|1@1+ (1,0) [0|0] "" Vector__XXX
 SG_ VCSEC_a472_peerRemovedInformatio m7 : 55|1@1+ (1,0) [0|0] "" Vector__XXX
 SG_ VCSEC_a111_EPBR_MIA m1 : 54|1@1+ (1,0) [0|0] "" Vector__XXX
 SG_ VCSEC_a110_GTW_MIA m1 : 53|1@1+ (1,0) [0|0] "" Vector__XXX
 SG_ VCSEC_a170_BLERearSoftReset m2 : 53|1@1+ (1,0) [0|0] "" Vector__XXX
 SG_ VCSEC_a109_RCM_MIA m1 : 52|1@1+ (1,0) [0|0] "" Vector__XXX
 SG_ VCSEC_a169_BLERightSoftReset m2 : 52|1@1+ (1,0) [0|0] "" Vector__XXX
 SG_ VCSEC_a529_TPMSTiresRotated m8 : 52|1@1+ (1,0) [0|0] "" Vector__XXX
 SG_ VCSEC_a108_DIF_MIA m1 : 51|1@1+ (1,0) [0|0] "" Vector__XXX
 SG_ VCSEC_a168_BLELeftSoftReset m2 : 51|1@1+ (1,0) [0|0] "" Vector__XXX
 SG_ VCSEC_a228_TPMSHardWarning m3 : 51|1@1+ (1,0) [0|0] "" Vector__XXX
 SG_ VCSEC_a528_TPMSLocalizationMulti m8 : 51|1@1+ (1,0) [0|0] "" Vector__XXX
 SG_ VCSEC_a107_BMS_MIA m1 : 50|1@1+ (1,0) [0|0] "" Vector__XXX
 SG_ VCSEC_a167_BLECenterSoftReset m2 : 50|1@1+ (1,0) [0|0] "" Vector__XXX
 SG_ VCSEC_a227_connectionWithoutLink m3 : 50|1@1+ (1,0) [0|0] "" Vector__XXX
 SG_ VCSEC_a527_TPMSLocalizationMulti m8 : 50|1@1+ (1,0) [0|0] "" Vector__XXX
 SG_ VCSEC_a046_Task1000msError m0 : 49|1@1+ (1,0) [0|0] "" Vector__XXX
 SG_ VCSEC_a106_PCS_MIA m1 : 49|1@1+ (1,0) [0|0] "" Vector__XXX
 SG_ VCSEC_a166_BLECenterPowerCycled m2 : 49|1@1+ (1,0) [0|0] "" Vector__XXX
 SG_ VCSEC_a226_TPMSSensorConnectionC m3 : 49|1@1+ (1,0) [0|0] "" Vector__XXX
 SG_ VCSEC_a526_TPMSLocalizationMulti m8 : 49|1@1+ (1,0) [0|0] "" Vector__XXX
 SG_ VCSEC_a045_Task100msError m0 : 48|1@1+ (1,0) [0|0] "" Vector__XXX
 SG_ VCSEC_a105_TAS_MIA m1 : 48|1@1+ (1,0) [0|0] "" Vector__XXX
 SG_ VCSEC_a165_ephemeralKeyGenerated m2 : 48|1@1+ (1,0) [0|0] "" Vector__XXX
 SG_ VCSEC_a225_TPMSSensorConnectionC m3 : 48|1@1+ (1,0) [0|0] "" Vector__XXX
 SG_ VCSEC_a525_TPMSLocalizationMulti m8 : 48|1@1+ (1,0) [0|0] "" Vector__XXX
 SG_ VCSEC_a044_Task10msError m0 : 47|1@1+ (1,0) [0|0] "" Vector__XXX
 SG_ VCSEC_a104_DAS_MIA m1 : 47|1@1+ (1,0) [0|0] "" Vector__XXX
 SG_ VCSEC_a164_attrsWentMissingC m2 : 47|1@1+ (1,0) [0|0] "" Vector__XXX
 SG_ VCSEC_a224_TPMSSensorConnectionC m3 : 47|1@1+ (1,0) [0|0] "" Vector__XXX
 SG_ VCSEC_a524_TPMSSensorLowConfiden m8 : 47|1@1+ (1,0) [0|0] "" Vector__XXX
 SG_ VCSEC_a043_Task1msError m0 : 46|1@1+ (1,0) [0|0] "" Vector__XXX
 SG_ VCSEC_a103_CP_MIA m1 : 46|1@1+ (1,0) [0|0] "" Vector__XXX
 SG_ VCSEC_a223_TPMSSensorConnectionC m3 : 46|1@1+ (1,0) [0|0] "" Vector__XXX
 SG_ VCSEC_a283_TPMSLowBattery3 m4 : 46|1@1+ (1,0) [0|0] "" Vector__XXX
 SG_ VCSEC_a523_TPMSSensorLowConfiden m8 : 46|1@1+ (1,0) [0|0] "" Vector__XXX
 SG_ VCSEC_a042_HighStackUsage m0 : 45|1@1+ (1,0) [0|0] "" Vector__XXX
 SG_ VCSEC_a102_PTC_MIA m1 : 45|1@1+ (1,0) [0|0] "" Vector__XXX
 SG_ VCSEC_a162_hciDebugRe m2 : 45|1@1+ (1,0) [0|0] "" Vector__XXX
 SG_ VCSEC_a222_TPMSSystemMalfunction m3 : 45|1@1+ (1,0) [0|0] "" Vector__XXX
 SG_ VCSEC_a282_TPMSLowBattery2 m4 : 45|1@1+ (1,0) [0|0] "" Vector__XXX
 SG_ VCSEC_a462_TPMSCertCheckFailedSe m7 : 45|1@1+ (1,0) [0|0] "" Vector__XXX
 SG_ VCSEC_a522_TPMSSensorLowConfiden m8 : 45|1@1+ (1,0) [0|0] "" Vector__XXX
 SG_ VCSEC_a041_HighCPULoad m0 : 44|1@1+ (1,0) [0|0] "" Vector__XXX
 SG_ VCSEC_a101_PM_MIA m1 : 44|1@1+ (1,0) [0|0] "" Vector__XXX
 SG_ VCSEC_a161_hciDebugR m2 : 44|1@1+ (1,0) [0|0] "" Vector__XXX
 SG_ VCSEC_a221_TPMSSoftWarning m3 : 44|1@1+ (1,0) [0|0] "" Vector__XXX
 SG_ VCSEC_a281_TPMSLowBattery1 m4 : 44|1@1+ (1,0) [0|0] "" Vector__XXX
 SG_ VCSEC_a461_TPMSCertCheckFailedSe m7 : 44|1@1+ (1,0) [0|0] "" Vector__XXX
 SG_ VCSEC_a521_TPMSSensorLowConfiden m8 : 44|1@1+ (1,0) [0|0] "" Vector__XXX
 SG_ VCSEC_a100_CANbus_MIA m1 : 43|1@1+ (1,0) [0|0] "" Vector__XXX
 SG_ VCSEC_a220_TPMSSensorPairingNotC m3 : 43|1@1+ (1,0) [0|0] "" Vector__XXX
 SG_ VCSEC_a280_TPMSLowBattery0 m4 : 43|1@1+ (1,0) [0|0] "" Vector__XXX
 SG_ VCSEC_a460_TPMSCertCheckFailedSe m7 : 43|1@1+ (1,0) [0|0] "" Vector__XXX
 SG_ VCSEC_a520_TPMSOutOfRangePressur m8 : 43|1@1+ (1,0) [0|0] "" Vector__XXX
 SG_ VCSEC_a099_PARK_MIA m1 : 42|1@1+ (1,0) [0|0] "" Vector__XXX
 SG_ VCSEC_a159_hciDebugL m2 : 42|1@1+ (1,0) [0|0] "" Vector__XXX
 SG_ VCSEC_a219_TPMSSensorPairingRemo m3 : 42|1@1+ (1,0) [0|0] "" Vector__XXX
 SG_ VCSEC_a459_TPMSCertCheckFailedSe m7 : 42|1@1+ (1,0) [0|0] "" Vector__XXX
 SG_ VCSEC_a519_TPMSOutOfRangePressur m8 : 42|1@1+ (1,0) [0|0] "" Vector__XXX
 SG_ VCSEC_a098_DIR_MIA m1 : 41|1@1+ (1,0) [0|0] "" Vector__XXX
 SG_ VCSEC_a158_hciDebugC m2 : 41|1@1+ (1,0) [0|0] "" Vector__XXX
 SG_ VCSEC_a218_TPMSUnexpectedDisconn m3 : 41|1@1+ (1,0) [0|0] "" Vector__XXX
 SG_ VCSEC_a458_TPMSOverPressureWarni m7 : 41|1@1+ (1,0) [0|0] "" Vector__XXX
 SG_ VCSEC_a518_TPMSOutOfRangePressur m8 : 41|1@1+ (1,0) [0|0] "" Vector__XXX
 SG_ VCSEC_a097_CMP_MIA m1 : 40|1@1+ (1,0) [0|0] "" Vector__XXX
 SG_ VCSEC_a217_TPMSUnexpectedDisconn m3 : 40|1@1+ (1,0) [0|0] "" Vector__XXX
 SG_ VCSEC_a457_TPMSOverPressureWarni m7 : 40|1@1+ (1,0) [0|0] "" Vector__XXX
 SG_ VCSEC_a517_TPMSOutOfRangePressur m8 : 40|1@1+ (1,0) [0|0] "" Vector__XXX
 SG_ VCSEC_a096_OCS1P_MIA m1 : 39|1@1+ (1,0) [0|0] "" Vector__XXX
 SG_ VCSEC_a156_srvcCmdTimeoutRe m2 : 39|1@1+ (1,0) [0|0] "" Vector__XXX
 SG_ VCSEC_a216_TPMSUnexpectedDisconn m3 : 39|1@1+ (1,0) [0|0] "" Vector__XXX
 SG_ VCSEC_a456_TPMSOverPressureWarni m7 : 39|1@1+ (1,0) [0|0] "" Vector__XXX
 SG_ VCSEC_a516_TPMSConnectionStatsNo m8 : 39|1@1+ (1,0) [0|0] "" Vector__XXX
 SG_ VCSEC_a095_CHG_MIA m1 : 38|1@1+ (1,0) [0|0] "" Vector__XXX
 SG_ VCSEC_a155_srvcCmdTimeoutR m2 : 38|1@1+ (1,0) [0|0] "" Vector__XXX
 SG_ VCSEC_a215_TPMSUnexpectedDisconn m3 : 38|1@1+ (1,0) [0|0] "" Vector__XXX
 SG_ VCSEC_a455_TPMSOverPressureWarni m7 : 38|1@1+ (1,0) [0|0] "" Vector__XXX
 SG_ VCSEC_a515_TPMSConnectionStatsNo m8 : 38|1@1+ (1,0) [0|0] "" Vector__XXX
 SG_ VCSEC_a094_EPAS3P_MIA m1 : 37|1@1+ (1,0) [0|0] "" Vector__XXX
 SG_ VCSEC_a154_srvcCmdTimeoutL m2 : 37|1@1+ (1,0) [0|0] "" Vector__XXX
 SG_ VCSEC_a214_gattServFalseWaitToBo m3 : 37|1@1+ (1,0) [0|0] "" Vector__XXX
 SG_ VCSEC_a274_handlePullWithoutAuth m4 : 37|1@1+ (1,0) [0|0] "" Vector__XXX
 SG_ VCSEC_a454_TPMSOverPressureWarni m7 : 37|1@1+ (1,0) [0|0] "" Vector__XXX
 SG_ VCSEC_a514_TPMSConnectionStatsNo m8 : 37|1@1+ (1,0) [0|0] "" Vector__XXX
 SG_ VCSEC_a093_VCSEATP_MIA m1 : 36|1@1+ (1,0) [0|0] "" Vector__XXX
 SG_ VCSEC_a153_srvcCmdTimeoutC m2 : 36|1@1+ (1,0) [0|0] "" Vector__XXX
 SG_ VCSEC_a213_gattTimeoutWithExptdC m3 : 36|1@1+ (1,0) [0|0] "" Vector__XXX
 SG_ VCSEC_a273_TPMSHardWarningRearRi m4 : 36|1@1+ (1,0) [0|0] "" Vector__XXX
 SG_ VCSEC_a453_passiveDisabled m7 : 36|1@1+ (1,0) [0|0] "" Vector__XXX
 SG_ VCSEC_a513_TPMSConnectionStatsNo m8 : 36|1@1+ (1,0) [0|0] "" Vector__XXX
 SG_ VCSEC_a092_VCSEATD_MIA m1 : 35|1@1+ (1,0) [0|0] "" Vector__XXX
 SG_ VCSEC_a212_snifferRSSIMIA m3 : 35|1@1+ (1,0) [0|0] "" Vector__XXX
 SG_ VCSEC_a272_TPMSHardWarningRearLe m4 : 35|1@1+ (1,0) [0|0] "" Vector__XXX
 SG_ VCSEC_a031_UDSActive m0 : 34|1@1+ (1,0) [0|0] "" Vector__XXX
 SG_ VCSEC_a091_CMPD_MIA m1 : 34|1@1+ (1,0) [0|0] "" Vector__XXX
 SG_ VCSEC_a151_attrsWentMissingRe m2 : 34|1@1+ (1,0) [0|0] "" Vector__XXX
 SG_ VCSEC_a211_handlePullWithoutAuth m3 : 34|1@1+ (1,0) [0|0] "" Vector__XXX
 SG_ VCSEC_a271_TPMSHardWarningFrontR m4 : 34|1@1+ (1,0) [0|0] "" Vector__XXX
 SG_ VCSEC_a511_phoneKeyStationary m8 : 34|1@1+ (1,0) [0|0] "" Vector__XXX
 SG_ VCSEC_a030_ECULogUploadRequest m0 : 33|1@1+ (1,0) [0|0] "" Vector__XXX
 SG_ VCSEC_a090_APS_MIA m1 : 33|1@1+ (1,0) [0|0] "" Vector__XXX
 SG_ VCSEC_a150_attrsWentMissingR m2 : 33|1@1+ (1,0) [0|0] "" Vector__XXX
 SG_ VCSEC_a210_keyDeviceBatteryLow m3 : 33|1@1+ (1,0) [0|0] "" Vector__XXX
 SG_ VCSEC_a270_TPMSHardWarningFrontL m4 : 33|1@1+ (1,0) [0|0] "" Vector__XXX
 SG_ VCSEC_a510_watchKeyOffWrist m8 : 33|1@1+ (1,0) [0|0] "" Vector__XXX
 SG_ VCSEC_a029_CoreDump m0 : 32|1@1+ (1,0) [0|0] "" Vector__XXX
 SG_ VCSEC_a089_IBST_MIA m1 : 32|1@1+ (1,0) [0|0] "" Vector__XXX
 SG_ VCSEC_a149_attrsWentMissingL m2 : 32|1@1+ (1,0) [0|0] "" Vector__XXX
 SG_ VCSEC_a209_BLECenterAssertFailur m3 : 32|1@1+ (1,0) [0|0] "" Vector__XXX
 SG_ VCSEC_a269_TPMSSoftWarningRearRi m4 : 32|1@1+ (1,0) [0|0] "" Vector__XXX
 SG_ VCSEC_a088_DIRER_MIA m1 : 31|1@1+ (1,0) [0|0] "" Vector__XXX
 SG_ VCSEC_a148_keyWhitelistFull m2 : 31|1@1+ (1,0) [0|0] "" Vector__XXX
 SG_ VCSEC_a208_BLERearAssertFailure m3 : 31|1@1+ (1,0) [0|0] "" Vector__XXX
 SG_ VCSEC_a268_TPMSSoftWarningRearLe m4 : 31|1@1+ (1,0) [0|0] "" Vector__XXX
 SG_ VCSEC_a087_DIREL_MIA m1 : 30|1@1+ (1,0) [0|0] "" Vector__XXX
 SG_ VCSEC_a147_protobufRXTimeout m2 : 30|1@1+ (1,0) [0|0] "" Vector__XXX
 SG_ VCSEC_a207_BLERightAssertFailure m3 : 30|1@1+ (1,0) [0|0] "" Vector__XXX
 SG_ VCSEC_a267_TPMSSoftWarningFrontR m4 : 30|1@1+ (1,0) [0|0] "" Vector__XXX
 SG_ VCSEC_a086_VCBATT_MIA m1 : 29|1@1+ (1,0) [0|0] "" Vector__XXX
 SG_ VCSEC_a206_BLELeftAssertFailure m3 : 29|1@1+ (1,0) [0|0] "" Vector__XXX
 SG_ VCSEC_a266_TPMSSoftWarningFrontL m4 : 29|1@1+ (1,0) [0|0] "" Vector__XXX
 SG_ VCSEC_a085_CCCM_MIA m1 : 28|1@1+ (1,0) [0|0] "" Vector__XXX
 SG_ VCSEC_a145_bleGattAlertRe m2 : 28|1@1+ (1,0) [0|0] "" Vector__XXX
 SG_ VCSEC_a205_MTUUpdateNotConfirmed m3 : 28|1@1+ (1,0) [0|0] "" Vector__XXX
 SG_ VCSEC_a265_tooManyPopulatedMessa m4 : 28|1@1+ (1,0) [0|0] "" Vector__XXX
 SG_ VCSEC_a084_TPMS_MIA m1 : 27|1@1+ (1,0) [0|0] "" Vector__XXX
 SG_ VCSEC_a144_bleGattAlertR m2 : 27|1@1+ (1,0) [0|0] "" Vector__XXX
 SG_ VCSEC_a204_SharedSecretsWritten m3 : 27|1@1+ (1,0) [0|0] "" Vector__XXX
 SG_ VCSEC_a264_noOnePopulatedMessage m4 : 27|1@1+ (1,0) [0|0] "" Vector__XXX
 SG_ VCSEC_a083_VCLEFT_IPC_MIA m1 : 26|1@1+ (1,0) [0|0] "" Vector__XXX
 SG_ VCSEC_a143_bleGattAlertL m2 : 26|1@1+ (1,0) [0|0] "" Vector__XXX
 SG_ VCSEC_a203_rearEndpointLostComm m3 : 26|1@1+ (1,0) [0|0] "" Vector__XXX
 SG_ VCSEC_a263_dispatchCouldNotBeCom m4 : 26|1@1+ (1,0) [0|0] "" Vector__XXX
 SG_ VCSEC_a022_TaskInitError m0 : 25|1@1+ (1,0) [0|0] "" Vector__XXX
 SG_ VCSEC_a082_VCRIGHT_IPC_MIA m1 : 25|1@1+ (1,0) [0|0] "" Vector__XXX
 SG_ VCSEC_a142_bleGattAlertC m2 : 25|1@1+ (1,0) [0|0] "" Vector__XXX
 SG_ VCSEC_a202_rightEndpointLostComm m3 : 25|1@1+ (1,0) [0|0] "" Vector__XXX
 SG_ VCSEC_a262_flowControlBackedUp m4 : 25|1@1+ (1,0) [0|0] "" Vector__XXX
 SG_ VCSEC_a502_TPMSAssertFailure3 m8 : 25|1@1+ (1,0) [0|0] "" Vector__XXX
 SG_ VCSEC_a021_TaskSchedulerError m0 : 24|1@1+ (1,0) [0|0] "" Vector__XXX
 SG_ VCSEC_a141_tooFewKeysOnWhitelist m2 : 24|1@1+ (1,0) [0|0] "" Vector__XXX
 SG_ VCSEC_a201_leftEndpointLostComm m3 : 24|1@1+ (1,0) [0|0] "" Vector__XXX
 SG_ VCSEC_a261_TPMSFactoryLearnActiv m4 : 24|1@1+ (1,0) [0|0] "" Vector__XXX
 SG_ VCSEC_a501_TPMSAssertFailure2 m8 : 24|1@1+ (1,0) [0|0] "" Vector__XXX
 SG_ VCSEC_a140_nfcAuthentication m2 : 23|1@1+ (1,0) [0|0] "" Vector__XXX
 SG_ VCSEC_a200_centerEndpointLostCom m3 : 23|1@1+ (1,0) [0|0] "" Vector__XXX
 SG_ VCSEC_a260_prsntPhoneKeyDisconne m4 : 23|1@1+ (1,0) [0|0] "" Vector__XXX
 SG_ VCSEC_a500_TPMSAssertFailure1 m8 : 23|1@1+ (1,0) [0|0] "" Vector__XXX
 SG_ VCSEC_a199_CenterNFCReaderMIA m3 : 22|1@1+ (1,0) [0|0] "" Vector__XXX
 SG_ VCSEC_a499_TPMSAssertFailure0 m8 : 22|1@1+ (1,0) [0|0] "" Vector__XXX
 SG_ VCSEC_a138_rearEndpointBusy m2 : 21|1@1+ (1,0) [0|0] "" Vector__XXX
 SG_ VCSEC_a198_BPillarNFCReaderMIA m3 : 21|1@1+ (1,0) [0|0] "" Vector__XXX
 SG_ VCSEC_a258_keyIsExpiring m4 : 21|1@1+ (1,0) [0|0] "" Vector__XXX
 SG_ VCSEC_a498_TPMSFeature0Reached m8 : 21|1@1+ (1,0) [0|0] "" Vector__XXX
 SG_ VCSEC_a017_NVMMStatusDbg m0 : 20|1@1+ (1,0) [0|0] "" Vector__XXX
 SG_ VCSEC_a137_rightEndpointBusy m2 : 20|1@1+ (1,0) [0|0] "" Vector__XXX
 SG_ VCSEC_a197_indicationFault m3 : 20|1@1+ (1,0) [0|0] "" Vector__XXX
 SG_ VCSEC_a257_connectedKeyIsExpirin m4 : 20|1@1+ (1,0) [0|0] "" Vector__XXX
 SG_ VCSEC_a016_NVMMRecordError m0 : 19|1@1+ (1,0) [0|0] "" Vector__XXX
 SG_ VCSEC_a136_leftEndpointBusy m2 : 19|1@1+ (1,0) [0|0] "" Vector__XXX
 SG_ VCSEC_a196_protobufTXTimeout m3 : 19|1@1+ (1,0) [0|0] "" Vector__XXX
 SG_ VCSEC_a256_whitelistOperationFai m4 : 19|1@1+ (1,0) [0|0] "" Vector__XXX
 SG_ VCSEC_a316_ltkRequestRejected m5 : 19|1@1+ (1,0) [0|0] "" Vector__XXX
 SG_ VCSEC_a436_uhfHWDoesNotMatchCoun m7 : 19|1@1+ (1,0) [0|0] "" Vector__XXX
 SG_ VCSEC_a496_handlePullWithoutAuth m8 : 19|1@1+ (1,0) [0|0] "" Vector__XXX
 SG_ VCSEC_a015_NVMMError m0 : 18|1@1+ (1,0) [0|0] "" Vector__XXX
 SG_ VCSEC_a135_centerEndpointBusy m2 : 18|1@1+ (1,0) [0|0] "" Vector__XXX
 SG_ VCSEC_a195_keyMissingInDrive m3 : 18|1@1+ (1,0) [0|0] "" Vector__XXX
 SG_ VCSEC_a255_wlistUpdatedPermissio m4 : 18|1@1+ (1,0) [0|0] "" Vector__XXX
 SG_ VCSEC_a315_bleBondingEvent m5 : 18|1@1+ (1,0) [0|0] "" Vector__XXX
 SG_ VCSEC_a435_NFCCardPresentWhileCh m7 : 18|1@1+ (1,0) [0|0] "" Vector__XXX
 SG_ VCSEC_a495_handlePullWithoutAuth m8 : 18|1@1+ (1,0) [0|0] "" Vector__XXX
 SG_ VCSEC_a134_noVINLoaded m2 : 17|1@1+ (1,0) [0|0] "" Vector__XXX
 SG_ VCSEC_a194_macIDWlistingFailedRe m3 : 17|1@1+ (1,0) [0|0] "" Vector__XXX
 SG_ VCSEC_a254_whitelistUpdatedKey m4 : 17|1@1+ (1,0) [0|0] "" Vector__XXX
 SG_ VCSEC_a013_AlertManagerFault m0 : 16|1@1+ (1,0) [0|0] "" Vector__XXX
 SG_ VCSEC_a133_alarmTriggered m2 : 16|1@1+ (1,0) [0|0] "" Vector__XXX
 SG_ VCSEC_a193_macIDWlistingFailedRi m3 : 16|1@1+ (1,0) [0|0] "" Vector__XXX
 SG_ VCSEC_a012_CPUReset m0 : 15|1@1+ (1,0) [0|0] "" Vector__XXX
 SG_ VCSEC_a192_macIDWlistingFailedL m3 : 15|1@1+ (1,0) [0|0] "" Vector__XXX
 SG_ VCSEC_a252_TPMSUpdateCompleteSen m4 : 15|1@1+ (1,0) [0|0] "" Vector__XXX
 SG_ VCSEC_a312_unexpectedBLEDisconne m5 : 15|1@1+ (1,0) [0|0] "" Vector__XXX
 SG_ VCSEC_a191_macIDWlistingFailedC m3 : 14|1@1+ (1,0) [0|0] "" Vector__XXX
 SG_ VCSEC_a251_TPMSUpdateCompleteSen m4 : 14|1@1+ (1,0) [0|0] "" Vector__XXX
 SG_ VCSEC_a311_moreThanThreeKeysPres m5 : 14|1@1+ (1,0) [0|0] "" Vector__XXX
 SG_ VCSEC_a010_ExtSupplyVoltError m0 : 13|1@1+ (1,0) [0|0] "" Vector__XXX
 SG_ VCSEC_a190_protoTooManyBytes m3 : 13|1@1+ (1,0) [0|0] "" Vector__XXX
 SG_ VCSEC_a250_TPMSUpdateCompleteSen m4 : 13|1@1+ (1,0) [0|0] "" Vector__XXX
 SG_ VCSEC_a310_chargePortFilterFalse m5 : 13|1@1+ (1,0) [0|0] "" Vector__XXX
 SG_ VCSEC_a189_protoExpLengthTooLarg m3 : 12|1@1+ (1,0) [0|0] "" Vector__XXX
 SG_ VCSEC_a249_TPMSUpdateCompleteSen m4 : 12|1@1+ (1,0) [0|0] "" Vector__XXX
 SG_ VCSEC_a309_serviceKeyConditionsN m5 : 12|1@1+ (1,0) [0|0] "" Vector__XXX
 SG_ VCSEC_a188_protobufDecodeError m3 : 11|1@1+ (1,0) [0|0] "" Vector__XXX
 SG_ VCSEC_a248_TPMSUpdateInterrupted m4 : 11|1@1+ (1,0) [0|0] "" Vector__XXX
 SG_ VCSEC_a308_NonConnectableAdvRece m5 : 11|1@1+ (1,0) [0|0] "" Vector__XXX
 SG_ VCSEC_a187_badConnectionDropped m3 : 10|1@1+ (1,0) [0|0] "" Vector__XXX
 SG_ VCSEC_a247_TPMSUpdateInterrupted m4 : 10|1@1+ (1,0) [0|0] "" Vector__XXX
 SG_ VCSEC_a307_ATTTimeout m5 : 10|1@1+ (1,0) [0|0] "" Vector__XXX
 SG_ VCSEC_a487_unrecognizedProto m8 : 10|1@1+ (1,0) [0|0] "" Vector__XXX
 SG_ VCSEC_a006_CANTX_cyclicError m0 : 9|1@1+ (1,0) [0|0] "" Vector__XXX
 SG_ VCSEC_a186_rearEndpointRFMia m3 : 9|1@1+ (1,0) [0|0] "" Vector__XXX
 SG_ VCSEC_a246_TPMSUpdateInterrupted m4 : 9|1@1+ (1,0) [0|0] "" Vector__XXX
 SG_ VCSEC_a306_KeyfobAdvReceivedWhil m5 : 9|1@1+ (1,0) [0|0] "" Vector__XXX
 SG_ VCSEC_a005_CANTXError m0 : 8|1@1+ (1,0) [0|0] "" Vector__XXX
 SG_ VCSEC_a185_passengerEndpointRFMi m3 : 8|1@1+ (1,0) [0|0] "" Vector__XXX
 SG_ VCSEC_a245_TPMSUpdateInterrupted m4 : 8|1@1+ (1,0) [0|0] "" Vector__XXX
 SG_ VCSEC_a305_ATTFlowControlViolate m5 : 8|1@1+ (1,0) [0|0] "" Vector__XXX
 SG_ VCSEC_a064_busSleepReqTimeout m1 : 7|1@1+ (1,0) [0|0] "" Vector__XXX
 SG_ VCSEC_a184_driverEndpointRFMia m3 : 7|1@1+ (1,0) [0|0] "" Vector__XXX
 SG_ VCSEC_a244_TPMSUpdateStartedSens m4 : 7|1@1+ (1,0) [0|0] "" Vector__XXX
 SG_ VCSEC_a304_KeyfobUpdateComplete m5 : 7|1@1+ (1,0) [0|0] "" Vector__XXX
 SG_ VCSEC_a003_SWAssertion m0 : 6|1@1+ (1,0) [0|0] "" Vector__XXX
 SG_ VCSEC_a063_SwitchFault m1 : 6|1@1+ (1,0) [0|0] "" Vector__XXX
 SG_ VCSEC_a183_centerEndpointRFMia m3 : 6|1@1+ (1,0) [0|0] "" Vector__XXX
 SG_ VCSEC_a243_TPMSUpdateStartedSens m4 : 6|1@1+ (1,0) [0|0] "" Vector__XXX
 SG_ VCSEC_a303_KeyfobUpdateInterrupt m5 : 6|1@1+ (1,0) [0|0] "" Vector__XXX
 SG_ VCSEC_a483_highThermalGradiantDe m8 : 6|1@1+ (1,0) [0|0] "" Vector__XXX
 SG_ VCSEC_a002_PowerLossReset m0 : 5|1@1+ (1,0) [0|0] "" Vector__XXX
 SG_ VCSEC_a062_XCPWasConnected m1 : 5|1@1+ (1,0) [0|0] "" Vector__XXX
 SG_ VCSEC_a182_cryptoHighStackUsage m3 : 5|1@1+ (1,0) [0|0] "" Vector__XXX
 SG_ VCSEC_a242_TPMSUpdateStartedSens m4 : 5|1@1+ (1,0) [0|0] "" Vector__XXX
 SG_ VCSEC_a302_unfused m5 : 5|1@1+ (1,0) [0|0] "" Vector__XXX
 SG_ VCSEC_a482_VINChanged m8 : 5|1@1+ (1,0) [0|0] "" Vector__XXX
 SG_ VCSEC_a001_WatchdogReset m0 : 4|1@1+ (1,0) [0|0] "" Vector__XXX
 SG_ VCSEC_a061_XCPConnected m1 : 4|1@1+ (1,0) [0|0] "" Vector__XXX
 SG_ VCSEC_a121_ICR_MIA m2 : 4|1@1+ (1,0) [0|0] "" Vector__XXX
 SG_ VCSEC_a181_signedMessageFault m3 : 4|1@1+ (1,0) [0|0] "" Vector__XXX
 SG_ VCSEC_a241_TPMSUpdateStartedSens m4 : 4|1@1+ (1,0) [0|0] "" Vector__XXX
 SG_ VCSEC_a301_imposterDetected m5 : 4|1@1+ (1,0) [0|0] "" Vector__XXX
 SG_ VCSEC_a481_handlePullWithoutAuth m8 : 4|1@1+ (1,0) [0|0] "" Vector__XXX
 SG_ VCSEC_matrixIndex M : 0|4@1+ (1,0) [0|0] "" Vector__XXX

BO_ 825 VCSEC_authentication: 8 VEH
 SG_ VCSEC_MCUCommandType: 36|3@1+ (1,0) [0|0] "" X
 SG_ VCSEC_alarmStatus: 43|4@1+ (1,0) [0|0] "" X
 SG_ VCSEC_authRequested: 60|1@1+ (1,0) [0|0] "" X
 SG_ VCSEC_authenticationStatus: 16|2@1+ (1,0) [0|0] "" X
 SG_ VCSEC_chargePortLockStatus: 18|1@1+ (1,0) [0|0] "" X
 SG_ VCSEC_frunkRequest: 34|2@1+ (1,0) [0|0] "" X
 SG_ VCSEC_immobilizerState: 48|3@1+ (1,0) [0|0] "" X
 SG_ VCSEC_keyChannelIndexed: 56|4@1+ (1,0) [0|0] "" X
 SG_ VCSEC_leftFrontLockStatus: 19|1@1+ (1,0) [0|0] "" X
 SG_ VCSEC_leftRearLockStatus: 20|1@1+ (1,0) [0|0] "" X
 SG_ VCSEC_lockIndicationRequest: 51|3@1+ (1,0) [0|0] "" X
 SG_ VCSEC_lockRequestType: 24|5@1+ (1,0) [0|0] "" X
 SG_ VCSEC_numberOfPubKeysOnWhitelist: 6|5@1+ (1,0) [0|0] "" X
 SG_ VCSEC_prsntRsnDeltaD: 3|1@1+ (1,0) [0|0] "" X
 SG_ VCSEC_prsntRsnDeltaP: 39|1@1+ (1,0) [0|0] "" X
 SG_ VCSEC_prsntRsnDeltaR: 4|1@1+ (1,0) [0|0] "" X
 SG_ VCSEC_prsntRsnHighThresholdC: 0|1@1+ (1,0) [0|0] "" X
 SG_ VCSEC_prsntRsnHighThresholdD: 1|1@1+ (1,0) [0|0] "" X
 SG_ VCSEC_prsntRsnHighThresholdP: 2|1@1+ (1,0) [0|0] "" X
 SG_ VCSEC_prsntRsnHighThresholdR: 5|1@1+ (1,0) [0|0] "" X
 SG_ VCSEC_rightFrontLockStatus: 21|1@1+ (1,0) [0|0] "" X
 SG_ VCSEC_rightRearLockStatus: 22|1@1+ (1,0) [0|0] "" X
 SG_ VCSEC_simpleLockStatus: 54|2@1+ (1,0) [0|0] "" X
 SG_ VCSEC_summonRequest: 29|3@1+ (1,0) [0|0] "" X
 SG_ VCSEC_trunkLockStatus: 23|1@1+ (1,0) [0|0] "" X
 SG_ VCSEC_trunkRequest: 32|2@1+ (1,0) [0|0] "" X
 SG_ VCSEC_usingModifiedMACAddress: 40|1@1+ (1,0) [0|0] "" X
 SG_ VCSEC_vehicleLockStatus: 12|4@1+ (1,0) [0|0] "" X

BO_ 793 VCSEC_info: 8 Vector__XXX
 SG_ VCSEC_infoComponentId m10 : 48|16@1+ (1,0) [0|0] "" Vector__XXX
 SG_ VCSEC_infoSubUsageId m11 : 48|16@1+ (1,0) [0|0] "" Vector__XXX
 SG_ VCSEC_infoAppCrc m13 : 32|32@1+ (1,0) [0|0] "" Vector__XXX
 SG_ VCSEC_infoHardwareId m10 : 32|16@1+ (1,0) [0|0] "" Vector__XXX
 SG_ VCSEC_infoSubcomponent1 m16 : 32|32@1+ (1,0) [0|0] "" Vector__XXX
 SG_ VCSEC_infoSubcomponent10 m37 : 32|32@1+ (1,0) [0|0] "" Vector__XXX
 SG_ VCSEC_infoSubcomponent11 m38 : 32|32@1+ (1,0) [0|0] "" Vector__XXX
 SG_ VCSEC_infoSubcomponent12 m39 : 32|32@1+ (1,0) [0|0] "" Vector__XXX
 SG_ VCSEC_infoSubcomponent13 m40 : 32|32@1+ (1,0) [0|0] "" Vector__XXX
 SG_ VCSEC_infoSubcomponent14 m41 : 32|32@1+ (1,0) [0|0] "" Vector__XXX
 SG_ VCSEC_infoSubcomponent2 m23 : 32|32@1+ (1,0) [0|0] "" Vector__XXX
 SG_ VCSEC_infoSubcomponent3 m24 : 32|32@1+ (1,0) [0|0] "" Vector__XXX
 SG_ VCSEC_infoSubcomponent4 m31 : 32|32@1+ (1,0) [0|0] "" Vector__XXX
 SG_ VCSEC_infoSubcomponent5 m32 : 32|32@1+ (1,0) [0|0] "" Vector__XXX
 SG_ VCSEC_infoSubcomponent6 m33 : 32|32@1+ (1,0) [0|0] "" Vector__XXX
 SG_ VCSEC_infoSubcomponent7 m34 : 32|32@1+ (1,0) [0|0] "" Vector__XXX
 SG_ VCSEC_infoSubcomponent8 m35 : 32|32@1+ (1,0) [0|0] "" Vector__XXX
 SG_ VCSEC_infoSubcomponent9 m36 : 32|32@1+ (1,0) [0|0] "" Vector__XXX
 SG_ VCSEC_infoUsageId m11 : 32|16@1+ (1,0) [0|0] "" Vector__XXX
 SG_ VCSEC_infoBootCrc m20 : 24|32@1+ (1,0) [0|0] "" Vector__XXX
 SG_ VCSEC_infoAssemblyId m11 : 16|8@1+ (1,0) [0|0] "" Vector__XXX
 SG_ VCSEC_infoBuildConfigId m10 : 16|16@1+ (1,0) [0|0] "" Vector__XXX
 SG_ VCSEC_infoAppGitHash m17 : 8|56@1+ (1,0) [0|0] "" Vector__XXX
 SG_ VCSEC_infoBootGitHash m18 : 8|56@1+ (1,0) [0|0] "" Vector__XXX
 SG_ VCSEC_infoBootUdsProtoVersion m20 : 8|16@1+ (1,0) [0|0] "" Vector__XXX
 SG_ VCSEC_infoBuildType m10 : 8|3@1+ (1,0) [0|0] "" Vector__XXX
 SG_ VCSEC_infoPcbaId m11 : 8|8@1+ (1,0) [0|0] "" Vector__XXX
 SG_ VCSEC_infoPlatformType m19 : 8|8@1+ (1,0) [0|0] "" Vector__XXX
 SG_ VCSEC_infoIndex M : 0|8@1+ (1,0) [0|0] "" Vector__XXX

BO_ 505 VCSEC_requests: 8 Vector__XXX
 SG_ VCSEC_frontTrunkRequestReason : 54|3@1+ (1,0) [0|0] "" Vector__XXX
 SG_ VCSEC_frontTrunkClosureRequest : 51|3@1+ (1,0) [0|0] "" Vector__XXX
 SG_ VCSEC_chargeportRequestReason : 47|3@1+ (1,0) [0|0] "" Vector__XXX
 SG_ VCSEC_snapshotRequested : 43|4@1+ (1,0) [0|0] "" Vector__XXX
 SG_ VCSEC_closeAllStatus : 41|2@1+ (1,0) [0|0] "" Vector__XXX
 SG_ VCSEC_driveAttemptedWithoutAuth : 36|4@1+ (1,0) [0|0] "" Vector__XXX
 SG_ VCSEC_rdMapDumpRequested : 35|1@1+ (1,0) [0|0] "" Vector__XXX
 SG_ VCSEC_rearTrunkRequestReason : 32|3@1+ (1,0) [0|0] "" Vector__XXX
 SG_ VCSEC_rearRightRequestReason : 29|3@1+ (1,0) [0|0] "" Vector__XXX
 SG_ VCSEC_rearLeftRequestReason : 26|3@1+ (1,0) [0|0] "" Vector__XXX
 SG_ VCSEC_frontRightRequestReason : 23|3@1+ (1,0) [0|0] "" Vector__XXX
 SG_ VCSEC_frontLeftRequestReason : 20|3@1+ (1,0) [0|0] "" Vector__XXX
 SG_ VCSEC_rearTrunkClosureRequest : 17|3@1+ (1,0) [0|0] "" Vector__XXX
 SG_ VCSEC_rearRightClosureRequest : 14|3@1+ (1,0) [0|0] "" Vector__XXX
 SG_ VCSEC_rearLeftClosureRequest : 11|3@1+ (1,0) [0|0] "" Vector__XXX
 SG_ VCSEC_frontRightClosureRequest : 8|3@1+ (1,0) [0|0] "" Vector__XXX
 SG_ VCSEC_frontLeftClosureRequest : 5|3@1+ (1,0) [0|0] "" Vector__XXX
 SG_ VCSEC_presentHandles : 4|1@1+ (1,0) [0|0] "" Vector__XXX
 SG_ VCSEC_chargePortRequest : 0|2@1+ (1,0) [0|0] "" Vector__XXX

BO_ 1657 UI_ambientLightingCtrls: 8 VEH
 SG_ UI_ambientLightingRed : 8|8@1+ (1,0) [0|255] "" X
 SG_ UI_ambientLightingGreen : 16|8@1+ (1,0) [0|255] "" X
 SG_ UI_ambientLightingBlue : 24|8@1+ (1,0) [0|255] "" X
 SG_ UI_ambientLightingBrightness : 32|7@1+ (1,0) [0|100] "%" X

BA_DEF_ BO_ "GenMsgSendType" ENUM "Cyclic";
BA_DEF_ BO_ "GenMsgCycleTime" INT 0 10000;

BA_ "GenMsgSendType" BO_ 259 0;
BA_ "GenMsgCycleTime" BO_ 259 100;

BA_ "GenMsgSendType" BO_ 915 0;
BA_ "GenMsgCycleTime" BO_ 915 50;

BA_ "GenMsgSendType" BO_ 579 0;
BA_ "GenMsgCycleTime" BO_ 579 100;

BA_ "GenMsgSendType" BO_ 524 0;
BA_ "GenMsgCycleTime" BO_ 524 100;

BA_ "GenMsgSendType" BO_ 774 0;
BA_ "GenMsgCycleTime" BO_ 774 1000;

BA_ "GenMsgSendType" BO_ 995 0;
BA_ "GenMsgCycleTime" BO_ 995 100;

BA_ "GenMsgSendType" BO_ 611 0;
BA_ "GenMsgCycleTime" BO_ 611 20;

BA_ "GenMsgSendType" BO_ 691 0;
BA_ "GenMsgCycleTime" BO_ 691 90;

BA_ "GenMsgSendType" BO_ 1859 0;
BA_ "GenMsgCycleTime" BO_ 1859 1000;

BA_ "GenMsgSendType" BO_ 794 0;
BA_ "GenMsgCycleTime" BO_ 794 50;

BA_ "GenMsgSendType" BO_ 1251 0;
BA_ "GenMsgCycleTime" BO_ 1251 100;

BA_ "GenMsgSendType" BO_ 899 0;
BA_ "GenMsgCycleTime" BO_ 899 100;

BA_ "GenMsgSendType" BO_ 857 0;
BA_ "GenMsgCycleTime" BO_ 857 100;

BA_ "GenMsgSendType" BO_ 969 0;
BA_ "GenMsgCycleTime" BO_ 969 1000;

BA_ "GenMsgSendType" BO_ 1017 0;
BA_ "GenMsgCycleTime" BO_ 1017 100;

BA_ "GenMsgSendType" BO_ 825 0;
BA_ "GenMsgCycleTime" BO_ 825 100;

BA_ "GenMsgSendType" BO_ 793 0;
BA_ "GenMsgCycleTime" BO_ 793 1000;

BA_ "GenMsgSendType" BO_ 505 0;
BA_ "GenMsgCycleTime" BO_ 505 100;

VAL_ 259 VCRIGHT_frontLatchStatus 0 "SNA" 1 "OPENED" 2 "CLOSED" 3 "CLOSING" 4 "OPENING" 5 "AJAR" 6 "TIMEOUT" 7 "DEFAULT" 8 "FAULT";
VAL_ 259 VCRIGHT_mirrorFoldState 0 "UNKNOWN" 1 "FOLDED" 2 "UNFOLDED" 3 "FOLDING" 4 "UNFOLDING";
VAL_ 259 VCRIGHT_mirrorRecallState 0 "INIT" 1 "RECALLING_AXIS_1" 2 "RECALLING_AXIS_2" 3 "RECALLING_COMPLETE" 4 "RECALLING_FAILED" 5 "RECALLING_STOPPED";
VAL_ 259 VCRIGHT_mirrorState 0 "IDLE" 1 "TILT_X" 2 "TILT_Y" 3 "FOLD_UNFOLD" 4 "RECALL";
VAL_ 259 VCRIGHT_rearLatchStatus 0 "SNA" 1 "OPENED" 2 "CLOSED" 3 "CLOSING" 4 "OPENING" 5 "AJAR" 6 "TIMEOUT" 7 "DEFAULT" 8 "FAULT";
VAL_ 259 VCRIGHT_trunkLatchStatus 0 "SNA" 1 "OPENED" 2 "CLOSED" 3 "CLOSING" 4 "OPENING" 5 "AJAR" 6 "TIMEOUT" 7 "DEFAULT" 8 "FAULT";

VAL_ 915 VCRIGHT_epbmDebugIndex 0 "STATES" 1 "TRANSITIONS";
VAL_ 915 VCRIGHT_epbmCaliperState 0 "UNSAVED" 1 "UNKNOWN" 2 "REAPPLY" 3 "PARK" 4 "OPEN" 5 "SERVICE";
VAL_ 915 VCRIGHT_summonFaultReason 0 "NONE" 1 "DI_MIA" 2 "DAS_MIA" 3 "ESP_MIA" 4 "EPBM_MIA" 5 "DI_FAULT" 6 "DI_APC_FAULT" 7 "DAS_FAULT" 8 "ESP_FAULT" 9 "VEH_CAN_FAULT" 10 "EAC_NOT_ALLOWED" 11 "EPBM_REQUEST" 12 "SPEED" 13 "EXTERNAL" 14 "PARK_MIA" 15 "PM_MIA" 16 "PM_REQUEST" 17 "OOC" 18 "MISMATCH" 19 "EPB_FAULT" 20 "DI_STATE_INVALID" 21 "PASSIVE_REQUEST" 22 "EPBREMOTE_MIA" 23 "REMOTE_SUMMON_FAULTED" 24 "LOCAL_UNIT_FAULTED" 25 "REMOTE_UNIT_FAULTED" 26 "START_IN_UNAVAILABLE" 27 "INVALID_REMOTE_STATE" 28 "REMOTE_DID_NOT_START";
VAL_ 915 VCRIGHT_epbSummonState 0 "INIT" 1 "IDLE" 2 "ARMED" 3 "ACTIVE" 4 "COMPLETE" 5 "FAULT" 6 "UNAVAILABLE";
VAL_ 915 VCRIGHT_epbmSummonState 0 "INIT" 1 "IDLE" 2 "ARMED" 3 "ACTIVE" 4 "COMPLETE" 5 "FAULT" 6 "UNAVAILABLE";
VAL_ 915 VCRIGHT_epbUnitStatus 0 "UNKNOWN" 1 "OPEN" 2 "DYNAMIC" 3 "PARK" 4 "START" 5 "SERVICE" 6 "WINCHMODE" 7 "WINCHMODE_RELEASING" 8 "PARKING" 9 "DYNAMIC_APPLYING" 10 "RELEASING" 11 "SERVICE_RELEASING" 12 "PARK_PENDING" 13 "WINCHMODE_PENDING" 14 "SUMMON" 15 "SUMMON_RELEASING" 16 "SUMMON_PARKING" 17 "EXTERNAL_DYNAMIC" 18 "RELEASING_FOR_EXTERNAL_PARK" 19 "EXTERNAL_PARKING" 20 "DYNAMIC_PARKING" 21 "COUNT";
VAL_ 915 VCRIGHT_epbmFaultStatus 0 "NOMINAL" 1 "RETRY" 2 "FAULT" 3 "FAULT_IDLE";
VAL_ 915 VCRIGHT_epbFaultStatus 0 "NOMINAL" 1 "RETRY" 2 "FAULT" 3 "FAULT_IDLE";
VAL_ 915 VCRIGHT_cdpEnumDummy 0 "IDLE" 1 "VALID" 2 "INVALID";

VAL_ 774 VCRIGHT_infoIndex 0 "DEPRECATED_0" 1 "DEPRECATED_1" 2 "DEPRECATED_2" 3 "DEPRECATED_3" 4 "DEPRECATED_4" 5 "DEPRECATED_5" 6 "DEPRECATED_6" 7 "DEPRECATED_7" 8 "DEPRECATED_8" 9 "DEPRECATED_9" 10 "BUILD_HWID_COMPONENTID" 11 "PCBAID_ASSYID_USAGEID" 13 "APP_CRC" 14 "BOOTLOADER_SVN" 15 "BOOTLOADER_CRC" 16 "SUBCOMPONENT1" 17 "APP_GITHASH" 18 "BOOTLOADER_GITHASH" 19 "VERSION_DEPRECATED" 20 "UDS_PROTOCOL_BOOTCRC" 23 "SUBCOMPONENT2" 24 "SUBCOMPONENT3" 31 "SUBCOMPONENT4" 255 "END";
VAL_ 774 VCRIGHT_infoBuildType 0 "UNKNOWN_BUILD" 1 "PLATFORM_BUILD" 2 "LOCAL_BUILD" 3 "TRACEABLE_CI_BUILD" 4 "MFG_BUILD";
VAL_ 774 VCRIGHT_infoAssemblyId 1 "ASSEMBLY1" 255 "ASSEMBLY_SNA";

VAL_ 691 VCRIGHT_logging1HzIndex 0 "HVAC_TEMP_SENSORS_AND_ESTIMATES_1" 1 "HVAC_TEMP_SENSORS_AND_ESTIMATES_2" 2 "HVAC_HUMIDITY_HEATER" 3 "HVAC_STATUS_AIRFLOW" 4 "HVAC_COMFORT_SOLAR" 5 "HEATER_AND_DUCT_TARGETS" 6 "HVAC_ACTUATOR_VOLTAGES" 7 "HVAC_ACTUATOR_ENDSTOP" 8 "HVAC_ACTUATOR_ZEROSTOP" 9 "HVAC_MISCELLANEOUS_1" 10 "HVAC_MISCELLANEOUS_2" 11 "END";
VAL_ 691 VCRIGHT_tempIncarCabinProbe 255 "SNA";
VAL_ 691 VCRIGHT_tempIncarCabinMid 250 "SNA";
VAL_ 691 VCRIGHT_tempIncarCabinDeep 255 "SNA";
VAL_ 691 VCRIGHT_cabinTempInteriorL2 240 "SNA";
VAL_ 691 VCRIGHT_cabinTempInteriorSunnyL2 240 "SNA";
VAL_ 691 VCRIGHT_cabinTempGlassRoof 255 "SNA";
VAL_ 691 VCRIGHT_cabinTempWindshield 255 "SNA";
VAL_ 691 VCRIGHT_cabinTempInterior 240 "SNA";
VAL_ 691 VCRIGHT_cabinTempInteriorSunny 240 "SNA";
VAL_ 691 VCRIGHT_cabinTempSideGlassLeft 255 "SNA";
VAL_ 691 VCRIGHT_cabinTempSideGlassRight 255 "SNA";
VAL_ 691 VCRIGHT_cabinTempBreathLevel 255 "SNA";
VAL_ 691 VCRIGHT_hvacAutoTransitionReason 0 "NONE" 1 "HUMIDITY_HIGH" 2 "HUMIDITY_MODERATE" 3 "HUMIDITY_LOW" 4 "TEMP_TARGET_BELOW_THRESHOLD" 5 "TEMP_TARGET_ABOVE_THRESHOLD" 6 "EXCESS_OCCUPANT_CONVECTION" 7 "OCCUPANT_CONVECTION_REQUIREMENT" 8 "TEMP_TARGET_LOW" 9 "DUCTS_COLD" 10 "BI_LEVEL_LANDING" 11 "DEFOG_OVERRIDE" 12 "SET_TEMP_LO" 13 "SET_TEMP_HI" 14 "CABIN_PURGE" 15 "EVAP_DRYING" 16 "HVAC_OFF" 17 "END";
VAL_ 691 VCRIGHT_hvacAirFlowModeRow1 0 "NONE" 1 "FLOOR" 2 "PANEL" 3 "PANEL_FLOOR" 4 "DEFROST" 5 "DEFROST_FLOOR" 6 "DEFROST_PANEL" 7 "DEFROST_PANEL_FLOOR";
VAL_ 691 VCRIGHT_hvacAirFlowModeRow2 0 "NONE" 1 "FLOOR" 2 "PANEL" 3 "PANEL_FLOOR" 4 "DEFROST" 5 "DEFROST_FLOOR" 6 "DEFROST_PANEL" 7 "DEFROST_PANEL_FLOOR";
VAL_ 691 VCRIGHT_hvacAirflowReason 0 "HVAC_OFF" 1 "MANUAL_FAN_SPEED" 2 "UI_SHORTCUT" 3 "CABIN_TEMPERATURE_CONTROL" 4 "MINIMUM_AUTO_AIRFLOW" 5 "STRATIFICATION_GLASS_ROOF" 6 "STRATIFICATION_INTERIOR_SURFACES" 7 "OCCUPANT_CONVECTION_REQUIREMENT" 8 "COLD_DUCT_LOCKOUT" 9 "CABIN_PURGE" 10 "CABIN_OVERHEAT_PROTECT" 11 "SCREEN_PROTECTION" 12 "EVAP_DRYING" 13 "NONE";
VAL_ 691 VCRIGHT_convectionTargetLeft 255 "SNA";
VAL_ 691 VCRIGHT_convectionTargetRight 255 "SNA";
VAL_ 691 VCRIGHT_convectionDeliveredLeft 255 "SNA";
VAL_ 691 VCRIGHT_convectionDeliveredRight 255 "SNA";
VAL_ 691 VCRIGHT_solarLoadRightOccupant 255 "SNA";
VAL_ 691 VCRIGHT_solarLoadLeftOccupant 255 "SNA";
VAL_ 691 VCRIGHT_solarLoadOnVehicle 255 "SNA";
VAL_ 691 VCRIGHT_solarLoadOnVehFiltered 255 "SNA";
VAL_ 691 VCRIGHT_cabinTempInteriorL3 240 "SNA";
VAL_ 691 VCRIGHT_cabinTempInteriorSunnyL3 240 "SNA";
VAL_ 691 VCRIGHT_cabinTempTopPadAir 240 "SNA";
VAL_ 691 VCRIGHT_tempDuctModeledLeft 511 "SNA";
VAL_ 691 VCRIGHT_tempDuctModeledRight 511 "SNA";
VAL_ 691 VCRIGHT_tempHtrSurfaceModeledL 511 "SNA";
VAL_ 691 VCRIGHT_tempHtrSurfaceModeledR 511 "SNA";

VAL_ 1859 VCRIGHT_mirrorRecallStatus 0 "SNA" 1 "IN_PROGRESS" 2 "COMPLETE" 3 "INTERRUPTED";
VAL_ 1859 VCRIGHT_seatRecallStatus 0 "SNA" 1 "IN_PROGRESS" 2 "COMPLETE" 3 "INTERRUPTED";
VAL_ 1859 VCRIGHT_systemRecallStatus 0 "SNA" 1 "IN_PROGRESS" 2 "COMPLETE" 3 "INTERRUPTED";

VAL_ 825 VCSEC_MCUCommandType 0 "NONE" 1 "REMOTE_UNLOCK" 2 "REMOTE_START" 3 "COMMAND3" 4 "COMMAND4" 5 "COMMAND5";
VAL_ 825 VCSEC_alarmStatus 0 "DISARMED" 1 "ARMED" 2 "PARTIAL_ARMED" 3 "TRIGGERED_FLASH_ACTIVE" 4 "ERROR" 5 "TRIGGERED_FLASH_INACTIVE" 6 "IMMINENT" 7 "DEFAULT" 15 "SNA";
VAL_ 825 VCSEC_authenticationStatus 0 "NONE" 1 "AUTHENTICATED_FOR_UNLOCK" 2 "AUTHENTICATED_FOR_DRIVE";
VAL_ 825 VCSEC_chargePortLockStatus 0 "UNLOCKED" 1 "LOCKED";
VAL_ 825 VCSEC_frunkRequest 0 "NONE" 1 "OPEN" 2 "SNA";
VAL_ 825 VCSEC_immobilizerState 0 "IDLE" 1 "PREPARE" 2 "ENCRYPT_BEGIN" 3 "ENCRYPT" 4 "SEND_AUTH_RESPONSE" 5 "SEND_NO_GO_AUTH_RESPONSE";
VAL_ 825 VCSEC_keyChannelIndexed 15 "SNA";
VAL_ 825 VCSEC_leftFrontLockStatus 0 "UNLOCKED" 1 "LOCKED";
VAL_ 825 VCSEC_leftRearLockStatus 0 "UNLOCKED" 1 "LOCKED";
VAL_ 825 VCSEC_lockIndicationRequest 0 "NONE_SNA" 1 "SINGLE" 2 "DOUBLE" 3 "TRIPLE" 4 "HOLD";
VAL_ 825 VCSEC_lockRequestType 0 "NONE" 1 "PASSIVE_SHIFT_TO_P_UNLOCK" 2 "PASSIVE_PARKBUTTON_UNLOCK" 3 "PASSIVE_INTERNAL_HANDLE_UNLOCK" 4 "PASSIVE_DRIVE_AWAY_LOCK" 5 "PASSIVE_BLE_WALKUP_UNLOCK" 6 "PASSIVE_BLE_EXTERIOR_CHARGEHANDLEBUTTON_UNLOCK" 7 "PASSIVE_BLE_EXTERIOR_HANDLE_UNLOCK" 8 "PASSIVE_BLE_INTERIOR_HANDLE_UNLOCK" 9 "PASSIVE_BLE_LOCK" 10 "CRASH_UNLOCK" 11 "ACTIVE_UI_BUTTON_UNLOCK" 12 "ACTIVE_UI_BUTTON_LOCK" 13 "ACTIVE_REMOTE_UNLOCK" 14 "ACTIVE_REMOTE_LOCK" 15 "ACTIVE_NFC_UNLOCK" 16 "ACTIVE_NFC_LOCK" 17 "ACTIVE_BLE_UNLOCK" 18 "ACTIVE_BLE_LOCK" 19 "PASSIVE_INTERNAL_LOCK_PROMOTION";
VAL_ 825 VCSEC_rightFrontLockStatus 0 "UNLOCKED" 1 "LOCKED";
VAL_ 825 VCSEC_rightRearLockStatus 0 "UNLOCKED" 1 "LOCKED";
VAL_ 825 VCSEC_simpleLockStatus 0 "SNA" 1 "UNLOCKED" 2 "LOCKED";
VAL_ 825 VCSEC_summonRequest 0 "IDLE" 1 "PRIME" 2 "FORWARD" 3 "BACKWARD" 4 "STOP" 5 "SNA";
VAL_ 825 VCSEC_trunkLockStatus 0 "UNLOCKED" 1 "LOCKED";
VAL_ 825 VCSEC_trunkRequest 0 "NONE" 1 "OPEN" 2 "SNA";
VAL_ 825 VCSEC_vehicleLockStatus 0 "SNA" 1 "ACTIVE_NFC_UNLOCKED" 2 "ACTIVE_NFC_LOCKED" 3 "PASSIVE_SELECTIVE_UNLOCKED" 4 "PASSIVE_BLE_UNLOCKED" 5 "PASSIVE_BLE_LOCKED" 6 "ACTIVE_SELECTIVE_UNLOCKED" 7 "ACTIVE_BLE_UNLOCKED" 8 "ACTIVE_BLE_LOCKED" 9 "ACTIVE_UI_UNLOCKED" 10 "ACTIVE_UI_LOCKED" 11 "ACTIVE_REMOTE_UNLOCKED" 12 "ACTIVE_REMOTE_LOCKED" 13 "CRASH_UNLOCKED" 14 "PASSIVE_INTERNAL_UNLOCKED" 15 "PASSIVE_INTERNAL_LOCKED";

BO_ 49 EPAS3P_status: 8 Vector__XXX
 SG_ EPAS3P_systemTorqueAvailability : 51|5@1+ (5,0) [0|0] "" Vector__XXX
 SG_ EPAS3P_tireIDActive : 50|1@1+ (1,0) [0|0] "" Vector__XXX
 SG_ EPAS3P_inputVoltage : 38|12@1+ (0.0073,0) [0|0] "" Vector__XXX
 SG_ EPAS3P_eacMaximumAngleSpeed : 31|7@1+ (10,0) [0|0] "" Vector__XXX
 SG_ EPAS3P_eacMaximumAngle : 24|7@1+ (10,0) [0|0] "" Vector__XXX
 SG_ EPAS3P_torsionBarTorqueQF : 23|1@1+ (1,0) [0|0] "" Vector__XXX
 SG_ EPAS3P_redundantCommStatus : 21|2@1+ (1,0) [0|0] "" Vector__XXX
 SG_ EPAS3P_role : 19|2@1+ (1,0) [0|0] "" Vector__XXX
 SG_ EPAS3P_powerMode : 16|3@1+ (1,0) [0|0] "" Vector__XXX
 SG_ EPAS3P_state : 12|4@1+ (1,0) [0|0] "" Vector__XXX
 SG_ EPAS3P_statusCounter : 8|4@1+ (1,0) [0|0] "" Vector__XXX
 SG_ EPAS3P_statusCrc : 0|8@1+ (1,0) [0|0] "" Vector__XXX

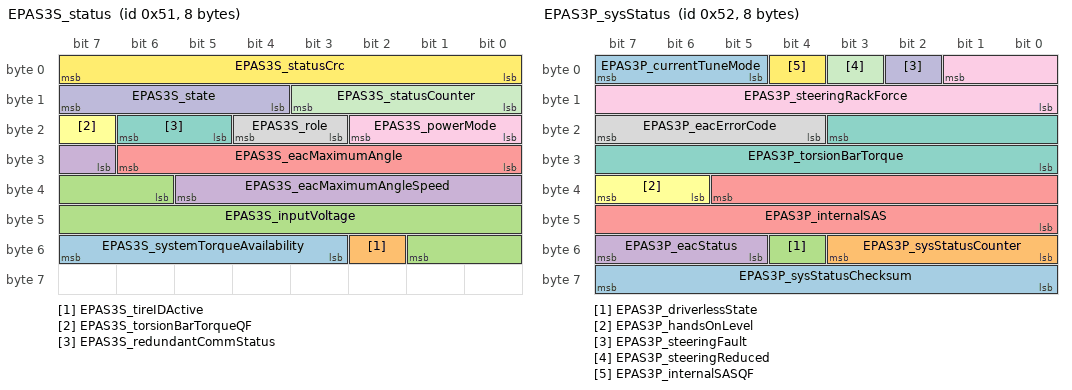
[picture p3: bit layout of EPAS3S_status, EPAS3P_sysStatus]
BO_ 81 EPAS3S_status: 8 Vector__XXX
 SG_ EPAS3S_systemTorqueAvailability : 51|5@1+ (5,0) [0|0] "" Vector__XXX
 SG_ EPAS3S_tireIDActive : 50|1@1+ (1,0) [0|0] "" Vector__XXX
 SG_ EPAS3S_inputVoltage : 38|12@1+ (0.0073,0) [0|0] "" Vector__XXX
 SG_ EPAS3S_eacMaximumAngleSpeed : 31|7@1+ (10,0) [0|0] "" Vector__XXX
 SG_ EPAS3S_eacMaximumAngle : 24|7@1+ (10,0) [0|0] "" Vector__XXX
 SG_ EPAS3S_torsionBarTorqueQF : 23|1@1+ (1,0) [0|0] "" Vector__XXX
 SG_ EPAS3S_redundantCommStatus : 21|2@1+ (1,0) [0|0] "" Vector__XXX
 SG_ EPAS3S_role : 19|2@1+ (1,0) [0|0] "" Vector__XXX
 SG_ EPAS3S_powerMode : 16|3@1+ (1,0) [0|0] "" Vector__XXX
 SG_ EPAS3S_state : 12|4@1+ (1,0) [0|0] "" Vector__XXX
 SG_ EPAS3S_statusCounter : 8|4@1+ (1,0) [0|0] "" Vector__XXX
 SG_ EPAS3S_statusCrc : 0|8@1+ (1,0) [0|0] "" Vector__XXX

BO_ 82 EPAS3P_sysStatus: 8 Vector__XXX
 SG_ EPAS3P_sysStatusChecksum : 63|8@0+ (1,0) [0|0] "" Vector__XXX
 SG_ EPAS3P_sysStatusCounter : 51|4@0+ (1,0) [0|0] "" Vector__XXX
 SG_ EPAS3P_driverlessState : 52|1@0+ (1,0) [0|0] "" Vector__XXX
 SG_ EPAS3P_eacStatus : 55|3@0+ (1,0) [0|0] "" Vector__XXX
 SG_ EPAS3P_internalSAS : 37|14@0+ (0.1,-819.2) [0|0] "" Vector__XXX
 SG_ EPAS3P_handsOnLevel : 39|2@0+ (1,0) [0|0] "" Vector__XXX
 SG_ EPAS3P_torsionBarTorque : 19|12@0+ (0.01,-20.5) [0|0] "" Vector__XXX
 SG_ EPAS3P_eacErrorCode : 23|4@0+ (1,0) [0|0] "" Vector__XXX
 SG_ EPAS3P_steeringRackForce : 1|10@0+ (50,-25575) [0|0] "" Vector__XXX
 SG_ EPAS3P_steeringFault : 2|1@0+ (1,0) [0|0] "" Vector__XXX
 SG_ EPAS3P_steeringReduced : 3|1@0+ (1,0) [0|0] "" Vector__XXX
 SG_ EPAS3P_internalSASQF : 4|1@0+ (1,0) [0|0] "" Vector__XXX
 SG_ EPAS3P_currentTuneMode : 7|3@0+ (1,0) [0|0] "" Vector__XXX

BO_ 290 VCLEFT_doorStatus2: 8 Vector__XXX
 SG_ VCLEFT_mirrorTiltYOffset m1 : 56|8@1- (0.02,0) [0|0] "" Vector__XXX
 SG_ VCLEFT_rearHandlePWM m0 : 56|7@1+ (1,0) [0|0] "" Vector__XXX
 SG_ VCLEFT_frontHandlePWM m0 : 48|7@1+ (1,0) [0|0] "" Vector__XXX
 SG_ VCLEFT_mirrorTiltXOffset m1 : 48|8@1- (0.02,0) [0|0] "" Vector__XXX
 SG_ VCLEFT_mirrorDimmed m0 : 47|1@1+ (1,0) [0|0] "" Vector__XXX
 SG_ VCLEFT_BPillarCameraHeaterCurrent m1 : 40|6@1+ (0.02,0) [0|0] "" Vector__XXX
 SG_ VCLEFT_mirrorFoldCurrent m0 : 40|7@1- (0.05,0) [0|0] "" Vector__XXX
 SG_ VCLEFT_rearHandle5vEnable m0 : 39|1@1+ (1,0) [0|0] "" Vector__XXX
 SG_ VCLEFT_frontHandle5vEnable m0 : 38|1@1+ (1,0) [0|0] "" Vector__XXX
 SG_ VCLEFT_rearHandleDebounceStatus m0 : 35|3@1+ (1,0) [0|0] "" Vector__XXX
 SG_ VCLEFT_frontHandleDebounceStatus m0 : 32|3@1+ (1,0) [0|0] "" Vector__XXX
 SG_ VCLEFT_mirrorFoldType m0 : 30|2@1+ (1,0) [0|0] "" Vector__XXX
 SG_ VCLEFT_rearHandleRawStatus m0 : 27|3@1+ (1,0) [0|0] "" Vector__XXX
 SG_ VCLEFT_frontHandleRawStatus m0 : 24|3@1+ (1,0) [0|0] "" Vector__XXX
 SG_ VCLEFT_rearDoorState m0 : 20|3@1+ (1,0) [0|0] "" Vector__XXX
 SG_ VCLEFT_frontDoorState m0 : 17|3@1+ (1,0) [0|0] "" Vector__XXX
 SG_ VCLEFT_BPillarCameraHeaterState m1 : 16|3@1+ (1,0) [0|0] "" Vector__XXX
 SG_ VCLEFT_vehicleInMotion m0 : 16|1@1+ (1,0) [0|0] "" Vector__XXX
 SG_ VCLEFT_frontLatchRelDuty m1 : 8|8@1+ (1,0) [0|0] "" Vector__XXX
 SG_ VCLEFT_rearLatchRelDuty m0 : 8|8@1+ (1,0) [0|0] "" Vector__XXX
 SG_ VCLEFT_doorStatus2Index M : 0|1@1+ (1,0) [0|0] "" Vector__XXX

BO_ 296 DI_systemLimits: 6 Vector__XXX
 SG_ DI_immobilizerAuthLevel : 33|2@1+ (1,0) [0|0] "" Vector__XXX
 SG_ DI_undersideAbuse : 32|1@1+ (1,0) [0|0] "" Vector__XXX
 SG_ DI_limitClosureNotClosed : 31|1@1+ (1,0) [0|0] "" Vector__XXX
 SG_ DI_proximity : 30|1@1+ (1,0) [0|0] "" Vector__XXX
 SG_ DI_vehicleSpeedLimitReason : 25|5@1+ (1,0) [0|0] "" Vector__XXX
 SG_ DI_vehicleSpeedLimit : 16|9@1+ (1,0) [0|0] "" Vector__XXX
 SG_ DI_vehicleSpeedLimitType : 14|2@1+ (1,0) [0|0] "" Vector__XXX
 SG_ DI_limitCdp : 13|1@1+ (1,0) [0|0] "" Vector__XXX
 SG_ DI_limitSystemSpinDownLearning : 12|1@1+ (1,0) [0|0] "" Vector__XXX
 SG_ DI_limitBmsMiaFreeze : 11|1@1+ (1,0) [0|0] "" Vector__XXX
 SG_ DI_limitVehicleSpeed : 10|1@1+ (1,0) [0|0] "" Vector__XXX
 SG_ DI_limitRegenTorque : 9|1@1+ (1,0) [0|0] "" Vector__XXX
 SG_ DI_limitDriveTorque : 8|1@1+ (1,0) [0|0] "" Vector__XXX
 SG_ DI_limitShift : 7|1@1+ (1,0) [0|0] "" Vector__XXX
 SG_ DI_limitSystemGPO : 6|1@1+ (1,0) [0|0] "" Vector__XXX
 SG_ DI_limitSystemLimp : 5|1@1+ (1,0) [0|0] "" Vector__XXX
 SG_ DI_limitObstacleDetection : 4|1@1+ (1,0) [0|0] "" Vector__XXX
 SG_ DI_limitVBatHigh : 3|1@1+ (1,0) [0|0] "" Vector__XXX
 SG_ DI_limitVBatLow : 2|1@1+ (1,0) [0|0] "" Vector__XXX
 SG_ DI_limitIBat : 1|1@1+ (1,0) [0|0] "" Vector__XXX
 SG_ DI_limitRegenPower : 0|1@1+ (1,0) [0|0] "" Vector__XXX

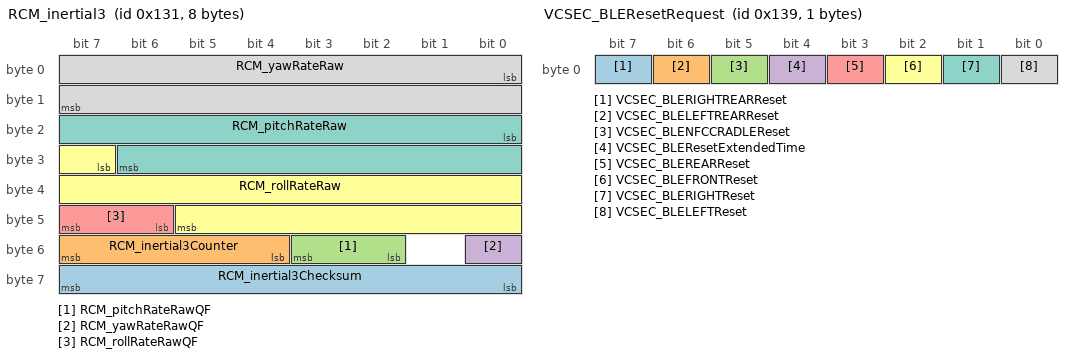
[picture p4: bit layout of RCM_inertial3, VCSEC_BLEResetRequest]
BO_ 305 RCM_inertial3: 8 Vector__XXX
 SG_ RCM_inertial3Checksum : 56|8@1+ (1,0) [0|0] "" Vector__XXX
 SG_ RCM_inertial3Counter : 52|4@1+ (1,0) [0|0] "" Vector__XXX
 SG_ RCM_pitchRateRawQF : 50|2@1+ (1,0) [0|0] "" Vector__XXX
 SG_ RCM_yawRateRawQF : 48|1@1+ (1,0) [0|0] "" Vector__XXX
 SG_ RCM_rollRateRawQF : 46|2@1+ (1,0) [0|0] "" Vector__XXX
 SG_ RCM_rollRateRaw : 31|15@1- (0.00025,0) [0|0] "" Vector__XXX
 SG_ RCM_pitchRateRaw : 16|15@1- (0.00025,0) [0|0] "" Vector__XXX
 SG_ RCM_yawRateRaw : 0|16@1- (0.0001,0) [0|0] "" Vector__XXX

BO_ 313 VCSEC_BLEResetRequest: 1 Vector__XXX
 SG_ VCSEC_BLERIGHTREARReset : 7|1@1+ (1,0) [0|0] "" Vector__XXX
 SG_ VCSEC_BLELEFTREARReset : 6|1@1+ (1,0) [0|0] "" Vector__XXX
 SG_ VCSEC_BLENFCCRADLEReset : 5|1@1+ (1,0) [0|0] "" Vector__XXX
 SG_ VCSEC_BLEResetExtendedTime : 4|1@1+ (1,0) [0|0] "" Vector__XXX
 SG_ VCSEC_BLEREARReset : 3|1@1+ (1,0) [0|0] "" Vector__XXX
 SG_ VCSEC_BLEFRONTReset : 2|1@1+ (1,0) [0|0] "" Vector__XXX
 SG_ VCSEC_BLERIGHTReset : 1|1@1+ (1,0) [0|0] "" Vector__XXX
 SG_ VCSEC_BLELEFTReset : 0|1@1+ (1,0) [0|0] "" Vector__XXX

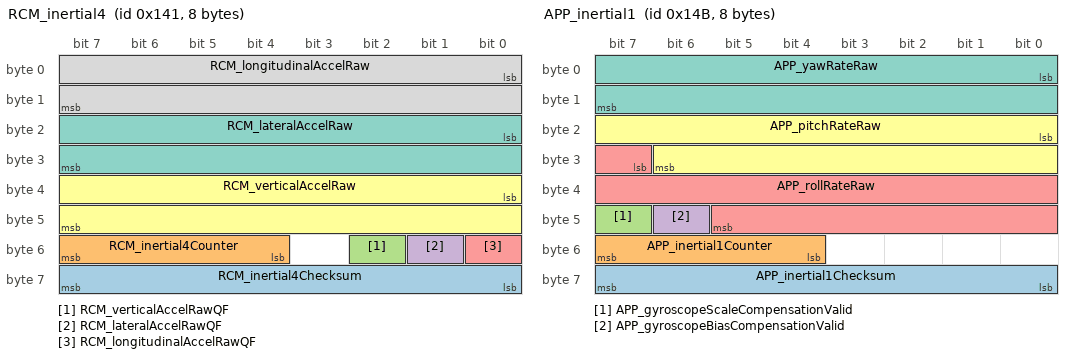
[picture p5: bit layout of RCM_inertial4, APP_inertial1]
BO_ 321 RCM_inertial4: 8 Vector__XXX
 SG_ RCM_inertial4Checksum : 56|8@1+ (1,0) [0|0] "" Vector__XXX
 SG_ RCM_inertial4Counter : 52|4@1+ (1,0) [0|0] "" Vector__XXX
 SG_ RCM_verticalAccelRawQF : 50|1@1+ (1,0) [0|0] "" Vector__XXX
 SG_ RCM_lateralAccelRawQF : 49|1@1+ (1,0) [0|0] "" Vector__XXX
 SG_ RCM_longitudinalAccelRawQF : 48|1@1+ (1,0) [0|0] "" Vector__XXX
 SG_ RCM_verticalAccelRaw : 32|16@1- (0.00125,0) [0|0] "" Vector__XXX
 SG_ RCM_lateralAccelRaw : 16|16@1- (0.00125,0) [0|0] "" Vector__XXX
 SG_ RCM_longitudinalAccelRaw : 0|16@1- (0.00125,0) [0|0] "" Vector__XXX

BO_ 326 ESP_redundantBrakingStatus: 8 Vector__XXX
 SG_ ESP_longitudinalStabilityControlAvailable : 15|1@1+ (1,0) [0|0] "" Vector__XXX
 SG_ ESP_redundantBrakingSystemStatus : 12|3@1+ (1,0) [0|0] "" Vector__XXX
 SG_ ESP_redundantBrakingStatusCounter : 8|4@1+ (1,0) [0|0] "" Vector__XXX
 SG_ ESP_redundantBrakingStatusChecksum : 0|8@1+ (1,0) [0|0] "" Vector__XXX

BO_ 329 IBST_redundantBrakingStatus: 8 Vector__XXX
 SG_ IBST_brakeTorqueTarget : 15|13@1+ (3,0) [0|0] "" Vector__XXX
 SG_ IBST_redundantBrakingSystemStatus : 12|3@1+ (1,0) [0|0] "" Vector__XXX
 SG_ IBST_redundantBrakingStatusCounter : 8|4@1+ (1,0) [0|0] "" Vector__XXX
 SG_ IBST_redundantBrakingStatusChecksum : 0|8@1+ (1,0) [0|0] "" Vector__XXX

BO_ 331 APP_inertial1: 8 Vector__XXX
 SG_ APP_inertial1Checksum : 56|8@1+ (1,0) [0|0] "" Vector__XXX
 SG_ APP_inertial1Counter : 52|4@1+ (1,0) [0|0] "" Vector__XXX
 SG_ APP_gyroscopeScaleCompensationValid : 47|1@1+ (1,0) [0|0] "" Vector__XXX
 SG_ APP_gyroscopeBiasCompensationValid : 46|1@1+ (1,0) [0|0] "" Vector__XXX
 SG_ APP_rollRateRaw : 31|15@1- (0.00025,0) [0|0] "" Vector__XXX
 SG_ APP_pitchRateRaw : 16|15@1- (0.00025,0) [0|0] "" Vector__XXX
 SG_ APP_yawRateRaw : 0|16@1- (0.0001,0) [0|0] "" Vector__XXX

BO_ 337 UNK_151: 8 Vector__XXX
 SG_ UNK_151_state : 48|2@1+ (1,0) [0|3] "" Vector__XXX

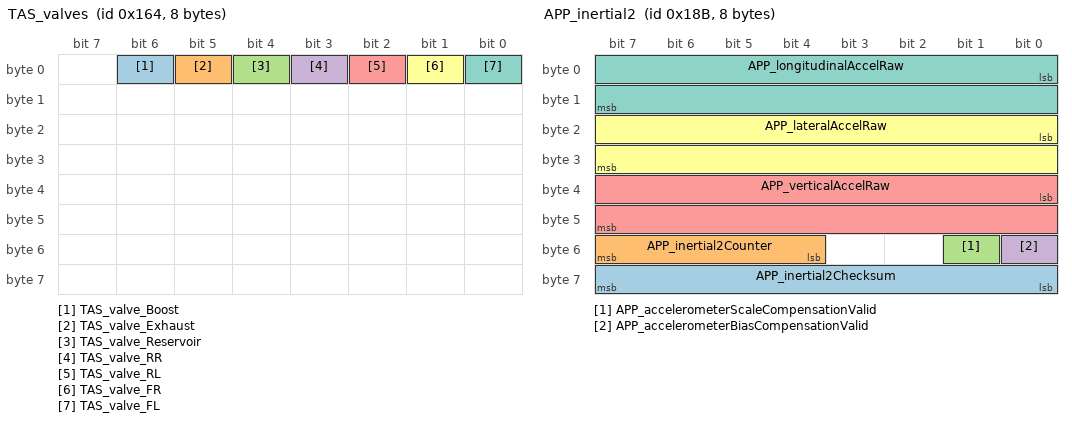
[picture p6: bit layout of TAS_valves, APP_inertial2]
BO_ 356 TAS_valves: 8 Vector__XXX
 SG_ TAS_valve_Boost : 6|1@1+ (1,0) [0|0] "" Vector__XXX
 SG_ TAS_valve_Exhaust : 5|1@1+ (1,0) [0|0] "" Vector__XXX
 SG_ TAS_valve_Reservoir : 4|1@1+ (1,0) [0|0] "" Vector__XXX
 SG_ TAS_valve_RR : 3|1@1+ (1,0) [0|0] "" Vector__XXX
 SG_ TAS_valve_RL : 2|1@1+ (1,0) [0|0] "" Vector__XXX
 SG_ TAS_valve_FR : 1|1@1+ (1,0) [0|0] "" Vector__XXX
 SG_ TAS_valve_FL : 0|1@1+ (1,0) [0|0] "" Vector__XXX

BO_ 357 TAS_voltages: 8 Vector__XXX
 SG_ TAS_5V_onboard : 32|8@1+ (0.025,0) [0|0] "" Vector__XXX
 SG_ TAS_5V_analogSensors : 24|8@1+ (0.025,0) [0|0] "" Vector__XXX
 SG_ TAS_5V_heightSensors : 16|8@1+ (0.025,0) [0|0] "" Vector__XXX
 SG_ TAS_12V_switched : 8|8@1+ (0.075,0) [0|0] "" Vector__XXX
 SG_ TAS_12V_supply : 0|8@1+ (0.075,0) [0|0] "" Vector__XXX

BO_ 358 TAS_temperatures: 8 Vector__XXX
 SG_ TAS_temp_F_CR_HSD m0 : 56|8@1+ (1,-40) [0|0] "" Vector__XXX
 SG_ TAS_temp_R_CR_HSD m1 : 56|8@1+ (1,-40) [0|0] "" Vector__XXX
 SG_ TAS_temp_FR_K m0 : 48|8@1+ (1,-40) [0|0] "" Vector__XXX
 SG_ TAS_temp_RR_K m1 : 48|8@1+ (1,-40) [0|0] "" Vector__XXX
 SG_ TAS_temp_FR_R m0 : 40|8@1+ (1,-40) [0|0] "" Vector__XXX
 SG_ TAS_temp_RR_R m1 : 40|8@1+ (1,-40) [0|0] "" Vector__XXX
 SG_ TAS_temp_FR_C m0 : 32|8@1+ (1,-40) [0|0] "" Vector__XXX
 SG_ TAS_temp_RR_C m1 : 32|8@1+ (1,-40) [0|0] "" Vector__XXX
 SG_ TAS_temp_FL_K m0 : 24|8@1+ (1,-40) [0|0] "" Vector__XXX
 SG_ TAS_temp_RL_K m1 : 24|8@1+ (1,-40) [0|0] "" Vector__XXX
 SG_ TAS_temp_FL_R m0 : 16|8@1+ (1,-40) [0|0] "" Vector__XXX
 SG_ TAS_temp_RL_R m1 : 16|8@1+ (1,-40) [0|0] "" Vector__XXX
 SG_ TAS_temp_VBAT_SW m2 : 16|8@1+ (1,-40) [0|0] "" Vector__XXX
 SG_ TAS_temp_FL_C m0 : 8|8@1+ (1,-40) [0|0] "" Vector__XXX
 SG_ TAS_temp_K_HSD m2 : 8|8@1+ (1,-40) [0|0] "" Vector__XXX
 SG_ TAS_temp_RL_C m1 : 8|8@1+ (1,-40) [0|0] "" Vector__XXX
 SG_ TAS_tempIndex M : 0|2@1+ (1,0) [0|0] "" Vector__XXX

BO_ 359 TAS_currentsSpring: 8 Vector__XXX
 SG_ TAS_current_RR_K : 24|8@1+ (0.01,0) [0|0] "" Vector__XXX
 SG_ TAS_current_RL_K : 16|8@1+ (0.01,0) [0|0] "" Vector__XXX
 SG_ TAS_current_FR_K : 8|8@1+ (0.01,0) [0|0] "" Vector__XXX
 SG_ TAS_current_FL_K : 0|8@1+ (0.01,0) [0|0] "" Vector__XXX

BO_ 395 APP_inertial2: 8 Vector__XXX
 SG_ APP_inertial2Checksum : 56|8@1+ (1,0) [0|0] "" Vector__XXX
 SG_ APP_inertial2Counter : 52|4@1+ (1,0) [0|0] "" Vector__XXX
 SG_ APP_accelerometerScaleCompensationValid : 49|1@1+ (1,0) [0|0] "" Vector__XXX
 SG_ APP_accelerometerBiasCompensationValid : 48|1@1+ (1,0) [0|0] "" Vector__XXX
 SG_ APP_verticalAccelRaw : 32|16@1- (0.00125,0) [0|0] "" Vector__XXX
 SG_ APP_lateralAccelRaw : 16|16@1- (0.00125,0) [0|0] "" Vector__XXX
 SG_ APP_longitudinalAccelRaw : 0|16@1- (0.00125,0) [0|0] "" Vector__XXX

BO_ 401 DAS_autonomyDebugInfo: 8 Vector__XXX
 SG_ DAS_autonomyUnavailableReason : 2|9@1+ (1,0) [0|0] "" Vector__XXX
 SG_ DAS_autonomyUnsupervisedActive : 1|1@1+ (1,0) [0|0] "" Vector__XXX
 SG_ DAS_rmfActive : 0|1@1+ (1,0) [0|0] "" Vector__XXX

BO_ 405 DIF_limits: 8 Vector__XXX
 SG_ DIF_pstgDisableSW3PS : 63|1@1+ (1,0) [0|0] "" Vector__XXX
 SG_ DIF_pstgDisableHW3PS : 62|1@1+ (1,0) [0|0] "" Vector__XXX
 SG_ DIF_currentLimit : 46|16@1+ (0.1,0) [0|0] "" Vector__XXX
 SG_ DIF_magnetFluxError : 38|8@1- (8e-05,0) [0|0] "" Vector__XXX
 SG_ DIF_statorTempFromResist : 30|8@1+ (1,-40) [0|0] "" Vector__XXX
 SG_ DIF_limitStatorHousingTemp : 29|1@1+ (1,0) [0|0] "" Vector__XXX
 SG_ DIF_limitUnitSpinDownLearning : 28|1@1+ (1,0) [0|0] "" Vector__XXX
 SG_ DIF_limithvDcCableTemp : 27|1@1+ (1,0) [0|0] "" Vector__XXX
 SG_ DIF_limitRotorTemp : 26|1@1+ (1,0) [0|0] "" Vector__XXX
 SG_ DIF_limitposDcBusbarTemp : 25|1@1+ (1,0) [0|0] "" Vector__XXX
 SG_ DIF_limitnegDcBusbarTemp : 24|1@1+ (1,0) [0|0] "" Vector__XXX
 SG_ DIF_limitdcLinkCapTemp : 23|1@1+ (1,0) [0|0] "" Vector__XXX
 SG_ DIF_limitphaseOutLugTemp : 22|1@1+ (1,0) [0|0] "" Vector__XXX
 SG_ DIF_limitphaseOutBusBarWeldTemp : 21|1@1+ (1,0) [0|0] "" Vector__XXX
 SG_ DIF_limitphaseOutBusbarTemp : 20|1@1+ (1,0) [0|0] "" Vector__XXX
 SG_ DIF_limitClutch : 19|1@1+ (1,0) [0|0] "" Vector__XXX
 SG_ DIF_limitStatorFrequency : 18|1@1+ (1,0) [0|0] "" Vector__XXX
 SG_ DIF_limitOilPumpFluidTemp : 17|1@1+ (1,0) [0|0] "" Vector__XXX
 SG_ DIF_limitShockTorque : 16|1@1+ (1,0) [0|0] "" Vector__XXX
 SG_ DIF_limitUnitGPO : 15|1@1+ (1,0) [0|0] "" Vector__XXX
 SG_ DIF_limitDiff : 14|1@1+ (1,0) [0|0] "" Vector__XXX
 SG_ DIF_limitMotorSpeed : 13|1@1+ (1,0) [0|0] "" Vector__XXX
 SG_ DIF_limitDcCapTemp : 12|1@1+ (1,0) [0|0] "" Vector__XXX
 SG_ DIF_limitBaseSpeed : 11|1@1+ (1,0) [0|0] "" Vector__XXX
 SG_ DIF_limitTCRegen : 10|1@1+ (1,0) [0|0] "" Vector__XXX
 SG_ DIF_limitTCDrive : 9|1@1+ (1,0) [0|0] "" Vector__XXX
 SG_ DIF_limitMotorVoltage : 8|1@1+ (1,0) [0|0] "" Vector__XXX
 SG_ DIF_limitMotorCurrent : 7|1@1+ (1,0) [0|0] "" Vector__XXX
 SG_ DIF_limitDischargePower : 6|1@1+ (1,0) [0|0] "" Vector__XXX
 SG_ DIF_limitDeltaFluidTemp : 5|1@1+ (1,0) [0|0] "" Vector__XXX
 SG_ DIF_limitUnitLimp : 4|1@1+ (1,0) [0|0] "" Vector__XXX
 SG_ DIF_limitPoleTemp : 3|1@1+ (1,0) [0|0] "" Vector__XXX
 SG_ DIF_limitStatorTemp : 2|1@1+ (1,0) [0|0] "" Vector__XXX
 SG_ DIF_limitInverterTemp : 1|1@1+ (1,0) [0|0] "" Vector__XXX
 SG_ DIF_limitPCBTemp : 0|1@1+ (1,0) [0|0] "" Vector__XXX

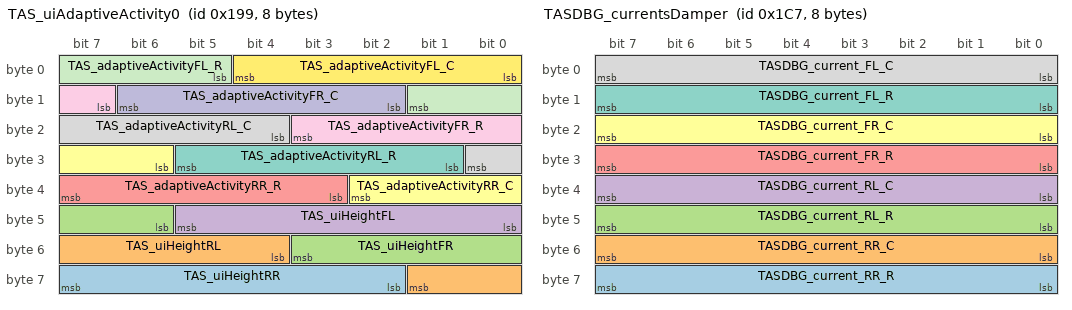
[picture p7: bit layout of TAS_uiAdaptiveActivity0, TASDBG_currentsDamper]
BO_ 409 TAS_uiAdaptiveActivity0: 8 Vector__XXX
 SG_ TAS_uiHeightRR : 58|6@1+ (4,-128) [0|0] "" Vector__XXX
 SG_ TAS_uiHeightRL : 52|6@1+ (4,-128) [0|0] "" Vector__XXX
 SG_ TAS_uiHeightFR : 46|6@1+ (4,-128) [0|0] "" Vector__XXX
 SG_ TAS_uiHeightFL : 40|6@1+ (4,-128) [0|0] "" Vector__XXX
 SG_ TAS_adaptiveActivityRR_R : 35|5@1+ (0.04,0) [0|0] "" Vector__XXX
 SG_ TAS_adaptiveActivityRR_C : 30|5@1+ (0.04,0) [0|0] "" Vector__XXX
 SG_ TAS_adaptiveActivityRL_R : 25|5@1+ (0.04,0) [0|0] "" Vector__XXX
 SG_ TAS_adaptiveActivityRL_C : 20|5@1+ (0.04,0) [0|0] "" Vector__XXX
 SG_ TAS_adaptiveActivityFR_R : 15|5@1+ (0.04,0) [0|0] "" Vector__XXX
 SG_ TAS_adaptiveActivityFR_C : 10|5@1+ (0.04,0) [0|0] "" Vector__XXX
 SG_ TAS_adaptiveActivityFL_R : 5|5@1+ (0.04,0) [0|0] "" Vector__XXX
 SG_ TAS_adaptiveActivityFL_C : 0|5@1+ (0.04,0) [0|0] "" Vector__XXX

BO_ 410 TAS_uiAdaptiveActivity1: 8 Vector__XXX
 SG_ TAS_bodyAccelRR : 24|8@1+ (0.05,-5) [0|0] "" Vector__XXX
 SG_ TAS_bodyAccelRL : 16|8@1+ (0.05,-5) [0|0] "" Vector__XXX
 SG_ TAS_bodyAccelFR : 8|8@1+ (0.05,-5) [0|0] "" Vector__XXX
 SG_ TAS_bodyAccelFL : 0|8@1+ (0.05,-5) [0|0] "" Vector__XXX

BO_ 443 UI_peripheralPowerRequests: 8 Vector__XXX
 SG_ UI_usbFrontHubPowerStateRequest : 0|2@1+ (1,0) [0|0] "" Vector__XXX

BO_ 454 GTW_canErrorCounters: 6 Vector__XXX
 SG_ GTW_CH_canRxErrCount : 40|8@1+ (1,0) [0|0] "" Vector__XXX
 SG_ GTW_CH_canTxErrCount : 32|8@1+ (1,0) [0|0] "" Vector__XXX
 SG_ GTW_VEH_canRxErrCount : 24|8@1+ (1,0) [0|0] "" Vector__XXX
 SG_ GTW_VEH_canTxErrCount : 16|8@1+ (1,0) [0|0] "" Vector__XXX
 SG_ GTW_PARTY_canRxErrCount : 8|8@1+ (1,0) [0|0] "" Vector__XXX
 SG_ GTW_PARTY_canTxErrCount : 0|8@1+ (1,0) [0|0] "" Vector__XXX

BO_ 455 TASDBG_currentsDamper: 8 Vector__XXX
 SG_ TASDBG_current_RR_R : 56|8@1+ (0.0075,0) [0|0] "" Vector__XXX
 SG_ TASDBG_current_RR_C : 48|8@1+ (0.0075,0) [0|0] "" Vector__XXX
 SG_ TASDBG_current_RL_R : 40|8@1+ (0.0075,0) [0|0] "" Vector__XXX
 SG_ TASDBG_current_RL_C : 32|8@1+ (0.0075,0) [0|0] "" Vector__XXX
 SG_ TASDBG_current_FR_R : 24|8@1+ (0.0075,0) [0|0] "" Vector__XXX
 SG_ TASDBG_current_FR_C : 16|8@1+ (0.0075,0) [0|0] "" Vector__XXX
 SG_ TASDBG_current_FL_R : 8|8@1+ (0.0075,0) [0|0] "" Vector__XXX
 SG_ TASDBG_current_FL_C : 0|8@1+ (0.0075,0) [0|0] "" Vector__XXX

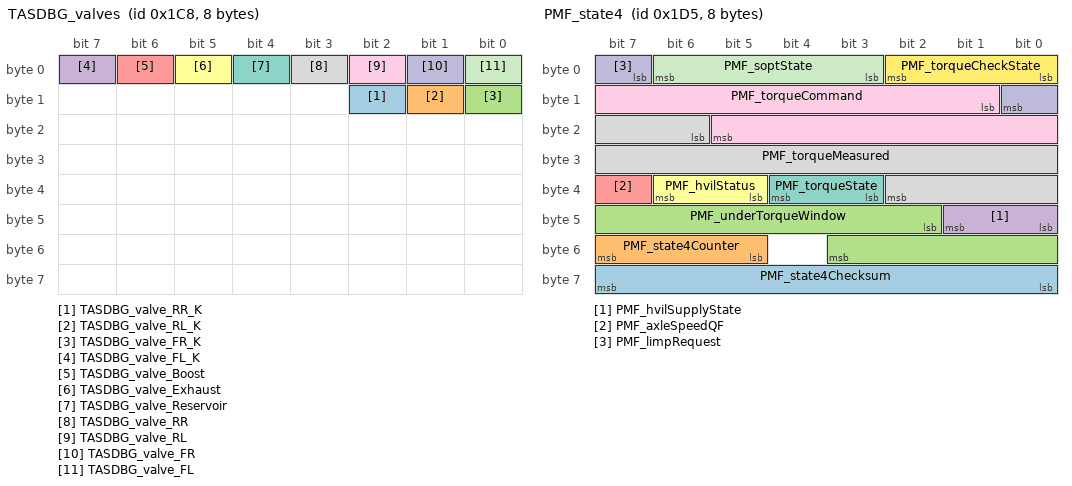
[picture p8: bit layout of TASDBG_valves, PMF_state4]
BO_ 456 TASDBG_valves: 8 Vector__XXX
 SG_ TASDBG_valve_RR_K : 10|1@1+ (1,0) [0|0] "" Vector__XXX
 SG_ TASDBG_valve_RL_K : 9|1@1+ (1,0) [0|0] "" Vector__XXX
 SG_ TASDBG_valve_FR_K : 8|1@1+ (1,0) [0|0] "" Vector__XXX
 SG_ TASDBG_valve_FL_K : 7|1@1+ (1,0) [0|0] "" Vector__XXX
 SG_ TASDBG_valve_Boost : 6|1@1+ (1,0) [0|0] "" Vector__XXX
 SG_ TASDBG_valve_Exhaust : 5|1@1+ (1,0) [0|0] "" Vector__XXX
 SG_ TASDBG_valve_Reservoir : 4|1@1+ (1,0) [0|0] "" Vector__XXX
 SG_ TASDBG_valve_RR : 3|1@1+ (1,0) [0|0] "" Vector__XXX
 SG_ TASDBG_valve_RL : 2|1@1+ (1,0) [0|0] "" Vector__XXX
 SG_ TASDBG_valve_FR : 1|1@1+ (1,0) [0|0] "" Vector__XXX
 SG_ TASDBG_valve_FL : 0|1@1+ (1,0) [0|0] "" Vector__XXX

BO_ 469 PMF_state4: 8 Vector__XXX
 SG_ PMF_state4Checksum : 56|8@1+ (1,0) [0|0] "" Vector__XXX
 SG_ PMF_state4Counter : 53|3@1+ (1,0) [0|0] "" Vector__XXX
 SG_ PMF_underTorqueWindow : 42|10@1+ (0.005,0) [0|0] "" Vector__XXX
 SG_ PMF_hvilSupplyState : 40|2@1+ (1,0) [0|0] "" Vector__XXX
 SG_ PMF_axleSpeedQF : 39|1@1+ (1,0) [0|0] "" Vector__XXX
 SG_ PMF_hvilStatus : 37|2@1+ (1,0) [0|0] "" Vector__XXX
 SG_ PMF_torqueState : 35|2@1+ (1,0) [0|0] "" Vector__XXX
 SG_ PMF_torqueMeasured : 22|13@1- (2,0) [0|0] "" Vector__XXX
 SG_ PMF_torqueCommand : 9|13@1- (2,0) [0|0] "" Vector__XXX
 SG_ PMF_limpRequest : 7|2@1+ (1,0) [0|0] "" Vector__XXX
 SG_ PMF_soptState : 3|4@1+ (1,0) [0|0] "" Vector__XXX
 SG_ PMF_torqueCheckState : 0|3@1+ (1,0) [0|0] "" Vector__XXX

BO_ 474 VCSEC_IsoTpPipeRemoteUI: 8 Vector__XXX
 SG_ VCSEC_IsoTpRemoteUI7 : 56|8@1+ (1,0) [0|0] "" Vector__XXX
 SG_ VCSEC_IsoTpRemoteUI6 : 48|8@1+ (1,0) [0|0] "" Vector__XXX
 SG_ VCSEC_IsoTpRemoteUI5 : 40|8@1+ (1,0) [0|0] "" Vector__XXX
 SG_ VCSEC_IsoTpRemoteUI4 : 32|8@1+ (1,0) [0|0] "" Vector__XXX
 SG_ VCSEC_IsoTpRemoteUI3 : 24|8@1+ (1,0) [0|0] "" Vector__XXX
 SG_ VCSEC_IsoTpRemoteUI2 : 16|8@1+ (1,0) [0|0] "" Vector__XXX
 SG_ VCSEC_IsoTpRemoteUI1 : 8|8@1+ (1,0) [0|0] "" Vector__XXX
 SG_ VCSEC_IsoTpRemoteUI0 : 0|8@1+ (1,0) [0|0] "" Vector__XXX

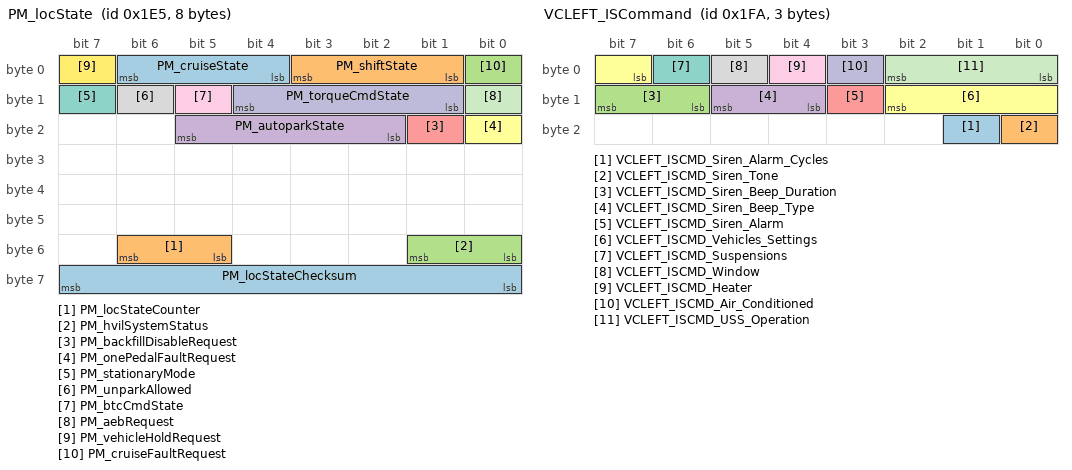
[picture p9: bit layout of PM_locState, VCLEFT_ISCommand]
BO_ 485 PM_locState: 8 Vector__XXX
 SG_ PM_locStateChecksum : 56|8@1+ (1,0) [0|0] "" Vector__XXX
 SG_ PM_locStateCounter : 53|2@1+ (1,0) [0|0] "" Vector__XXX
 SG_ PM_hvilSystemStatus : 48|2@1+ (1,0) [0|0] "" Vector__XXX
 SG_ PM_autoparkState : 18|4@1+ (1,0) [0|0] "" Vector__XXX
 SG_ PM_backfillDisableRequest : 17|1@1+ (1,0) [0|0] "" Vector__XXX
 SG_ PM_onePedalFaultRequest : 16|1@1+ (1,0) [0|0] "" Vector__XXX
 SG_ PM_stationaryMode : 15|1@1+ (1,0) [0|0] "" Vector__XXX
 SG_ PM_unparkAllowed : 14|1@1+ (1,0) [0|0] "" Vector__XXX
 SG_ PM_btcCmdState : 13|1@1+ (1,0) [0|0] "" Vector__XXX
 SG_ PM_torqueCmdState : 9|4@1+ (1,0) [0|0] "" Vector__XXX
 SG_ PM_aebRequest : 8|1@1+ (1,0) [0|0] "" Vector__XXX
 SG_ PM_vehicleHoldRequest : 7|1@1+ (1,0) [0|0] "" Vector__XXX
 SG_ PM_cruiseState : 4|3@1+ (1,0) [0|0] "" Vector__XXX
 SG_ PM_shiftState : 1|3@1+ (1,0) [0|0] "" Vector__XXX
 SG_ PM_cruiseFaultRequest : 0|1@1+ (1,0) [0|0] "" Vector__XXX

BO_ 504 VCLEFT_intrusionSensorStatus: 4 Vector__XXX
 SG_ VCLEFT_intrusionUltraTripped : 26|1@1+ (1,0) [0|0] "" Vector__XXX
 SG_ VCLEFT_intrusionTiltTripped : 25|1@1+ (1,0) [0|0] "" Vector__XXX
 SG_ VCLEFT_sirenMIA : 24|1@1+ (1,0) [0|0] "" Vector__XXX
 SG_ VCLEFT_DBG_System_Error : 23|1@1+ (1,0) [0|0] "" Vector__XXX
 SG_ VCLEFT_DBG_LM_SelfTest_Status : 22|1@1+ (1,0) [0|0] "" Vector__XXX
 SG_ VCLEFT_DBG_USS_SelfTest_Status : 21|1@1+ (1,0) [0|0] "" Vector__XXX
 SG_ VCLEFT_DBG_Eeprom_ST_Status : 20|1@1+ (1,0) [0|0] "" Vector__XXX
 SG_ VCLEFT_DBG_Reserved_08 : 19|1@1+ (1,0) [0|0] "" Vector__XXX
 SG_ VCLEFT_DBG_Reserved_07 : 18|1@1+ (1,0) [0|0] "" Vector__XXX
 SG_ VCLEFT_DBG_Siren_is_sounding : 17|1@1+ (1,0) [0|0] "" Vector__XXX
 SG_ VCLEFT_DBG_Invalid_Parameter : 16|1@1+ (1,0) [0|0] "" Vector__XXX
 SG_ VCLEFT_DBG_Siren_Int_Trigger : 15|1@1+ (1,0) [0|0] "" Vector__XXX
 SG_ VCLEFT_DBG_Siren_ST_Status : 14|1@1+ (1,0) [0|0] "" Vector__XXX
 SG_ VCLEFT_DBG_LM_Alarm_Status : 13|1@1+ (1,0) [0|0] "" Vector__XXX
 SG_ VCLEFT_DBG_USS_Alarm_Status : 12|1@1+ (1,0) [0|0] "" Vector__XXX
 SG_ VCLEFT_DBG_Veh_Settings_Status : 8|4@1+ (1,0) [0|0] "" Vector__XXX
 SG_ VCLEFT_DBG_SelfTest_Status : 7|1@1+ (1,0) [0|0] "" Vector__XXX
 SG_ VCLEFT_DBG_Suspensions_Status : 6|1@1+ (1,0) [0|0] "" Vector__XXX
 SG_ VCLEFT_DBG_Window_Status : 5|1@1+ (1,0) [0|0] "" Vector__XXX
 SG_ VCLEFT_DBG_Heater_Status : 4|1@1+ (1,0) [0|0] "" Vector__XXX
 SG_ VCLEFT_DBG_Air_Cond_Status : 3|1@1+ (1,0) [0|0] "" Vector__XXX
 SG_ VCLEFT_DBG_System_Status : 0|3@1+ (1,0) [0|0] "" Vector__XXX

BO_ 506 VCLEFT_ISCommand: 3 Vector__XXX
 SG_ VCLEFT_ISCMD_Siren_Alarm_Cycles : 17|1@1+ (1,0) [0|0] "" Vector__XXX
 SG_ VCLEFT_ISCMD_Siren_Tone : 16|1@1+ (1,0) [0|0] "" Vector__XXX
 SG_ VCLEFT_ISCMD_Siren_Beep_Duration : 14|2@1+ (1,0) [0|0] "" Vector__XXX
 SG_ VCLEFT_ISCMD_Siren_Beep_Type : 12|2@1+ (1,0) [0|0] "" Vector__XXX
 SG_ VCLEFT_ISCMD_Siren_Alarm : 11|1@1+ (1,0) [0|0] "" Vector__XXX
 SG_ VCLEFT_ISCMD_Vehicles_Settings : 7|4@1+ (1,0) [0|0] "" Vector__XXX
 SG_ VCLEFT_ISCMD_Suspensions : 6|1@1+ (1,0) [0|0] "" Vector__XXX
 SG_ VCLEFT_ISCMD_Window : 5|1@1+ (1,0) [0|0] "" Vector__XXX
 SG_ VCLEFT_ISCMD_Heater : 4|1@1+ (1,0) [0|0] "" Vector__XXX
 SG_ VCLEFT_ISCMD_Air_Conditioned : 3|1@1+ (1,0) [0|0] "" Vector__XXX
 SG_ VCLEFT_ISCMD_USS_Operation : 0|3@1+ (1,0) [0|0] "" Vector__XXX

BO_ 507 VCLEFT_TLCStatus: 8 Vector__XXX
 SG_ VCLEFT_TLCTotalCurrent m0 : 56|8@1+ (0.1,0) [0|0] "" Vector__XXX
 SG_ VCLEFT_TLCReverseCurrent m0 : 48|8@1+ (0.1,0) [0|0] "" Vector__XXX
 SG_ VCLEFT_TLCState_Reverse m1 : 41|3@1+ (1,0) [0|0] "" Vector__XXX
 SG_ VCLEFT_TLCFogCurrent m0 : 40|8@1+ (0.1,0) [0|0] "" Vector__XXX
 SG_ VCLEFT_TLCState_Fog m1 : 38|3@1+ (1,0) [0|0] "" Vector__XXX
 SG_ VCLEFT_TLCState_Stop m1 : 35|3@1+ (1,0) [0|0] "" Vector__XXX
 SG_ VCLEFT_TLCState_Tail m1 : 32|3@1+ (1,0) [0|0] "" Vector__XXX
 SG_ VCLEFT_TLCStopCurrent m0 : 32|8@1+ (0.1,0) [0|0] "" Vector__XXX
 SG_ VCLEFT_TLCState_RightTurn m1 : 29|3@1+ (1,0) [0|0] "" Vector__XXX
 SG_ VCLEFT_TLCState_LeftTurn m1 : 26|3@1+ (1,0) [0|0] "" Vector__XXX
 SG_ VCLEFT_TLCTailCurrent m0 : 24|8@1+ (0.1,0) [0|0] "" Vector__XXX
 SG_ VCLEFT_TLCRightTurnVoltage m1 : 18|8@1+ (0.1,0) [0|0] "" Vector__XXX
 SG_ VCLEFT_TLCRightTurnCurrent m0 : 16|8@1+ (0.1,0) [0|0] "" Vector__XXX
 SG_ VCLEFT_TLCLeftTurnVoltage m1 : 10|8@1+ (0.1,0) [0|0] "" Vector__XXX
 SG_ VCLEFT_TLCLeftTurnCurrent m0 : 8|8@1+ (0.1,0) [0|0] "" Vector__XXX
 SG_ VCLEFT_TLCTemperature m1 : 2|8@1- (1,68) [0|0] "" Vector__XXX
 SG_ VCLEFT_TLCStatusIndex M : 0|2@1+ (1,0) [0|0] "" Vector__XXX

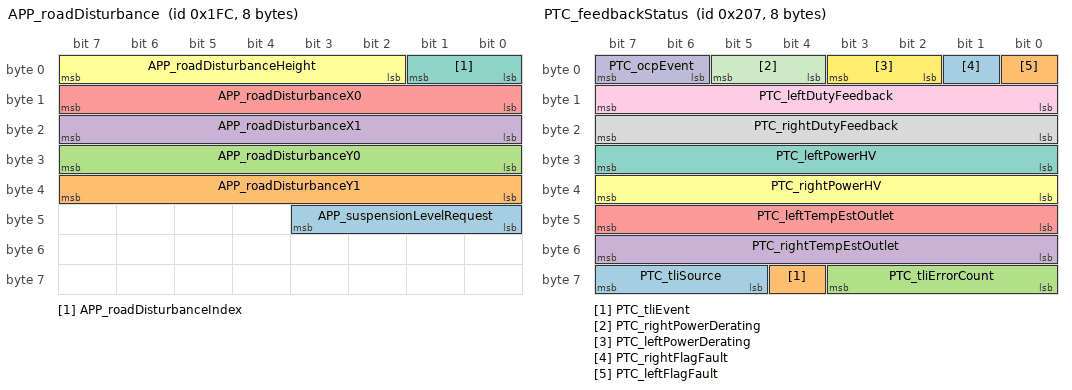
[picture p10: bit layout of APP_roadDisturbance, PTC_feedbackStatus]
BO_ 508 APP_roadDisturbance: 8 Vector__XXX
 SG_ APP_suspensionLevelRequest : 40|4@1+ (1,0) [0|0] "" Vector__XXX
 SG_ APP_roadDisturbanceY1 : 32|8@1+ (0.1,-12.8) [0|0] "" Vector__XXX
 SG_ APP_roadDisturbanceY0 : 24|8@1+ (0.1,-12.8) [0|0] "" Vector__XXX
 SG_ APP_roadDisturbanceX1 : 16|8@1+ (0.5,0) [0|0] "" Vector__XXX
 SG_ APP_roadDisturbanceX0 : 8|8@1+ (0.5,0) [0|0] "" Vector__XXX
 SG_ APP_roadDisturbanceHeight : 2|6@1+ (0.02,-0.64) [0|0] "" Vector__XXX
 SG_ APP_roadDisturbanceIndex : 0|2@1+ (1,0) [0|0] "" Vector__XXX

BO_ 519 PTC_feedbackStatus: 8 Vector__XXX
 SG_ PTC_tliSource : 61|3@1+ (1,0) [0|0] "" Vector__XXX
 SG_ PTC_tliEvent : 60|1@1+ (1,0) [0|0] "" Vector__XXX
 SG_ PTC_tliErrorCount : 56|4@1+ (1,0) [0|0] "" Vector__XXX
 SG_ PTC_rightTempEstOutlet : 48|8@1+ (1,-40) [0|0] "" Vector__XXX
 SG_ PTC_leftTempEstOutlet : 40|8@1+ (1,-40) [0|0] "" Vector__XXX
 SG_ PTC_rightPowerHV : 32|8@1+ (30,0) [0|0] "" Vector__XXX
 SG_ PTC_leftPowerHV : 24|8@1+ (30,0) [0|0] "" Vector__XXX
 SG_ PTC_rightDutyFeedback : 16|8@1+ (0.5,0) [0|0] "" Vector__XXX
 SG_ PTC_leftDutyFeedback : 8|8@1+ (0.5,0) [0|0] "" Vector__XXX
 SG_ PTC_ocpEvent : 6|2@1+ (1,0) [0|0] "" Vector__XXX
 SG_ PTC_rightPowerDerating : 4|2@1+ (1,0) [0|0] "" Vector__XXX
 SG_ PTC_leftPowerDerating : 2|2@1+ (1,0) [0|0] "" Vector__XXX
 SG_ PTC_rightFlagFault : 1|1@1+ (1,0) [0|0] "" Vector__XXX
 SG_ PTC_leftFlagFault : 0|1@1+ (1,0) [0|0] "" Vector__XXX

BO_ 521 DAS_longControl: 8 Vector__XXX
 SG_ DAS_longControlStack M : 61|3@1+ (1,0) [0|0] "" Vector__XXX
 SG_ DAS_velocityProfile_calcDelay m3 : 58|3@1+ (0.006666666666666667,0) [0|0] "" Vector__XXX
 SG_ DAS_torqueProfiler_jerkMaxPed m2 : 53|8@1+ (0.059,0) [0|0] "" Vector__XXX
 SG_ DAS_velocityProfile_maxAllowedTargetErrorReg m3 : 52|6@1- (0.1,1.1) [0|0] "" Vector__XXX
 SG_ DAS_pedalControl_speedMax m5 : 51|8@1+ (1,0) [0|0] "" Vector__XXX
 SG_ DAS_pedalControl_noGradeAccelMax m5 : 45|6@1+ (0.25,0) [0|0] "" Vector__XXX
 SG_ DAS_torqueProfiler_jerkMinPed m2 : 44|9@1+ (0.03,-15.232) [0|0] "" Vector__XXX
 SG_ DAS_velocityProfile_jerkFwd_t1t2 m3 : 44|8@1- (0.12,0) [0|0] "" Vector__XXX
 SG_ DAS_pedalControl_brakeTorqueCommand m5 : 32|13@1+ (3.5,0) [0|0] "" Vector__XXX
 SG_ DAS_torqueControl_standstillRequest m6 : 32|1@1+ (1,0) [0|0] "" Vector__XXX
 SG_ DAS_torqueProfiler_targetSpeedPed m2 : 32|12@1+ (0.1,0) [0|0] "" Vector__XXX
 SG_ DAS_velocityProfile_futureTargetSpeedFwd m3 : 32|12@1- (0.08,80.08) [0|0] "" Vector__XXX
 SG_ DAS_velocityProfile_jerkFwd_t0t1 m3 : 24|8@1- (0.12,0) [0|0] "" Vector__XXX
 SG_ DAS_torqueProfiler_accelMaxPed m2 : 23|9@1+ (0.04,-15) [0|0] "" Vector__XXX
 SG_ DAS_aebControl_targetAccelDis m4 : 18|11@1- (0.01,-7.5) [0|0] "" Vector__XXX
 SG_ DAS_aebControl_active m4 : 16|2@1+ (1,0) [0|0] "" Vector__XXX
 SG_ DAS_pedalControl_accelPedalPos m5 : 16|12@1+ (0.025,0) [0|0] "" Vector__XXX
 SG_ DAS_torqueControl_sysTorqueCommandFwd m6 : 16|15@1- (2,0) [0|0] "" Vector__XXX
 SG_ DAS_torqueProfiler_accelMinPed m2 : 14|9@1+ (0.04,-15) [0|0] "" Vector__XXX
 SG_ DAS_velocityProfile_accelFwd_t0 m3 : 13|11@1- (0.012,-0.216) [0|0] "" Vector__XXX
 SG_ DAS_gearRequest : 11|2@1+ (1,0) [0|0] "" Vector__XXX
 SG_ DAS_longControlCounter : 8|3@1+ (1,0) [0|0] "" Vector__XXX
 SG_ DAS_longControlChecksum : 0|8@1+ (1,0) [0|0] "" Vector__XXX

BO_ 538 TAS_uiControl: 8 Vector__XXX
 SG_ TAS_uiControlChecksum : 32|8@1+ (1,0) [0|0] "" Vector__XXX
 SG_ TAS_uiControlCounter : 28|4@1+ (1,0) [0|0] "" Vector__XXX
 SG_ TAS_restrictLevelingShowroom : 25|1@1+ (1,0) [0|0] "" Vector__XXX
 SG_ TAS_restrictLevelingTransport : 24|1@1+ (1,0) [0|0] "" Vector__XXX
 SG_ TAS_restrictLevelingSystemCheck : 23|1@1+ (1,0) [0|0] "" Vector__XXX
 SG_ TAS_restrictLevelingChargeCable : 22|1@1+ (1,0) [0|0] "" Vector__XXX
 SG_ TAS_restrictDownLevelingDoors : 21|1@1+ (1,0) [0|0] "" Vector__XXX
 SG_ TAS_restrictUpLevelingTrunk : 20|1@1+ (1,0) [0|0] "" Vector__XXX
 SG_ TAS_restrictUpLevelingFalcons : 19|1@1+ (1,0) [0|0] "" Vector__XXX
 SG_ TAS_launchModeState : 16|3@1+ (1,0) [0|0] "" Vector__XXX
 SG_ TAS_adaptiveRideSelectEnabled : 14|1@1+ (1,0) [0|0] "" Vector__XXX
 SG_ TAS_jackModeToggleEnabled : 13|1@1+ (1,0) [0|0] "" Vector__XXX
 SG_ TAS_levelSelectEnabled : 12|1@1+ (1,0) [0|0] "" Vector__XXX
 SG_ TAS_adaptiveRideModeOverride : 10|2@1+ (1,0) [0|0] "" Vector__XXX
 SG_ TAS_showSpinner : 9|1@1+ (1,0) [0|0] "" Vector__XXX
 SG_ TAS_extractAllowed : 7|1@1+ (1,0) [0|0] "" Vector__XXX
 SG_ TAS_veryHighAllowed : 6|1@1+ (1,0) [0|0] "" Vector__XXX
 SG_ TAS_highAllowed : 5|1@1+ (1,0) [0|0] "" Vector__XXX
 SG_ TAS_standardAllowed : 4|1@1+ (1,0) [0|0] "" Vector__XXX
 SG_ TAS_lowAllowed : 3|1@1+ (1,0) [0|0] "" Vector__XXX
 SG_ TAS_veryLowAllowed : 2|1@1+ (1,0) [0|0] "" Vector__XXX
 SG_ TAS_redWarningLamp : 1|1@1+ (1,0) [0|0] "" Vector__XXX
 SG_ TAS_yellowWarningLamp : 0|1@1+ (1,0) [0|0] "" Vector__XXX

BO_ 546 TAS_compTemp: 8 Vector__XXX
 SG_ TAS_compTempModel : 8|8@1+ (1,-40) [0|0] "" Vector__XXX
 SG_ TAS_compTempSensor : 0|8@1+ (1,-40) [0|0] "" Vector__XXX

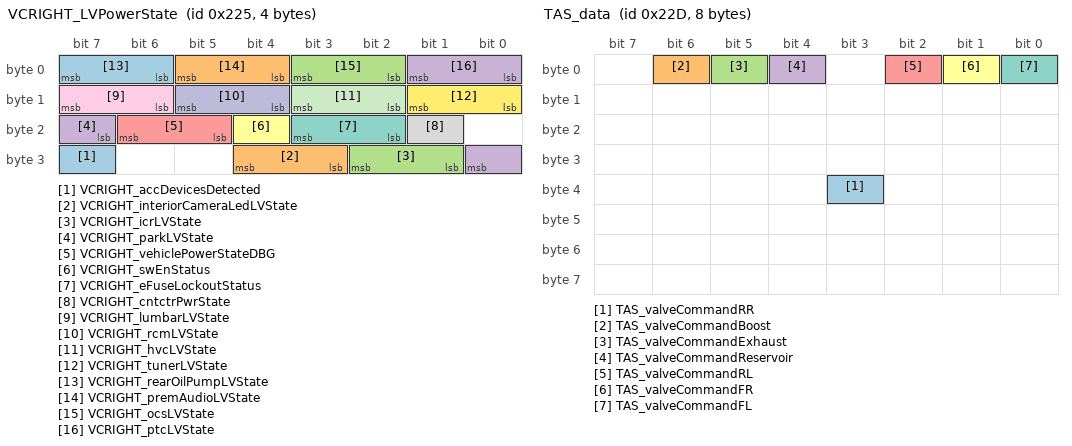
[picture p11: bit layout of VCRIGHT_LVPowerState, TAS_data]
BO_ 549 VCRIGHT_LVPowerState: 4 Vector__XXX
 SG_ VCRIGHT_accDevicesDetected : 31|1@1+ (1,0) [0|0] "" Vector__XXX
 SG_ VCRIGHT_interiorCameraLedLVState : 27|2@1+ (1,0) [0|0] "" Vector__XXX
 SG_ VCRIGHT_icrLVState : 25|2@1+ (1,0) [0|0] "" Vector__XXX
 SG_ VCRIGHT_parkLVState : 23|2@1+ (1,0) [0|0] "" Vector__XXX
 SG_ VCRIGHT_vehiclePowerStateDBG : 21|2@1+ (1,0) [0|0] "" Vector__XXX
 SG_ VCRIGHT_swEnStatus : 20|1@1+ (1,0) [0|0] "" Vector__XXX
 SG_ VCRIGHT_eFuseLockoutStatus : 18|2@1+ (1,0) [0|0] "" Vector__XXX
 SG_ VCRIGHT_cntctrPwrState : 17|1@1+ (1,0) [0|0] "" Vector__XXX
 SG_ VCRIGHT_lumbarLVState : 14|2@1+ (1,0) [0|0] "" Vector__XXX
 SG_ VCRIGHT_rcmLVState : 12|2@1+ (1,0) [0|0] "" Vector__XXX
 SG_ VCRIGHT_hvcLVState : 10|2@1+ (1,0) [0|0] "" Vector__XXX
 SG_ VCRIGHT_tunerLVState : 8|2@1+ (1,0) [0|0] "" Vector__XXX
 SG_ VCRIGHT_rearOilPumpLVState : 6|2@1+ (1,0) [0|0] "" Vector__XXX
 SG_ VCRIGHT_premAudioLVState : 4|2@1+ (1,0) [0|0] "" Vector__XXX
 SG_ VCRIGHT_ocsLVState : 2|2@1+ (1,0) [0|0] "" Vector__XXX
 SG_ VCRIGHT_ptcLVState : 0|2@1+ (1,0) [0|0] "" Vector__XXX

BO_ 551 OCS1P_debugCushionMutCNT: 8 Vector__XXX
 SG_ OCS1P_cushionMutCNTFreqMed : 48|16@1+ (10,0) [0|0] "" Vector__XXX
 SG_ OCS1P_cushionMutCNTDuty : 32|16@1+ (1,0) [0|0] "" Vector__XXX
 SG_ OCS1P_cushionMutCNTFreq : 0|32@1+ (1,0) [0|0] "" Vector__XXX

BO_ 554 HVP_hvsControl: 4 Vector__XXX
 SG_ HVP_dcLinkVoltageFiltered : 20|11@1- (1,0) [0|0] "" Vector__XXX
 SG_ HVP_pcsDcdcHwEnabled : 19|1@1+ (1,0) [0|0] "" Vector__XXX
 SG_ HVP_pcsChargeHwEnabled : 18|1@1+ (1,0) [0|0] "" Vector__XXX
 SG_ HVP_pcsControlRequest : 16|2@1+ (1,0) [0|0] "" Vector__XXX
 SG_ HVP_dcLinkVoltageRequest : 0|16@1- (0.1,0) [0|0] "" Vector__XXX

BO_ 555 DAS_matrixHighBeamRequest: 8 Vector__XXX
 SG_ DAS_azimuthSegmentLightRequests : 0|64@1+ (1,0) [0|0] "" Vector__XXX

BO_ 557 TAS_data: 8 Vector__XXX
 SG_ TAS_valveCommandRR : 35|1@1+ (1,0) [0|0] "" Vector__XXX
 SG_ TAS_valveCommandBoost : 6|1@1+ (1,0) [0|0] "" Vector__XXX
 SG_ TAS_valveCommandExhaust : 5|1@1+ (1,0) [0|0] "" Vector__XXX
 SG_ TAS_valveCommandReservoir : 4|1@1+ (1,0) [0|0] "" Vector__XXX
 SG_ TAS_valveCommandRL : 2|1@1+ (1,0) [0|0] "" Vector__XXX
 SG_ TAS_valveCommandFR : 1|1@1+ (1,0) [0|0] "" Vector__XXX
 SG_ TAS_valveCommandFL : 0|1@1+ (1,0) [0|0] "" Vector__XXX

BO_ 561 OCS1P_debugSeatbackSelfCNT: 8 Vector__XXX
 SG_ OCS1P_seatbackSelfCNTFreqMed : 48|16@1+ (10,0) [0|0] "" Vector__XXX
 SG_ OCS1P_seatbackSelfCNTDuty : 32|16@1+ (1,0) [0|0] "" Vector__XXX
 SG_ OCS1P_seatbackSelfCNTFreq : 0|32@1+ (1,0) [0|0] "" Vector__XXX

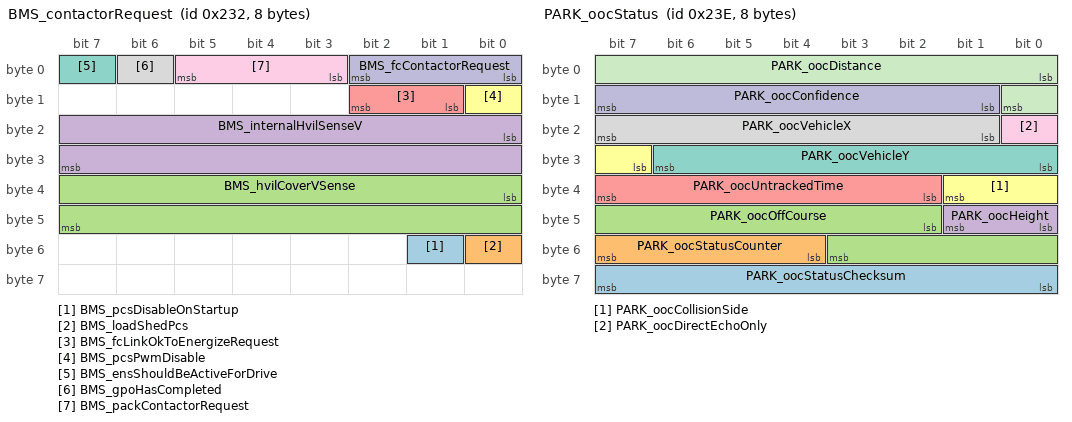
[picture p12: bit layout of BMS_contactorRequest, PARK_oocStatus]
BO_ 562 BMS_contactorRequest: 8 Vector__XXX
 SG_ BMS_pcsDisableOnStartup : 49|1@1+ (1,0) [0|0] "" Vector__XXX
 SG_ BMS_loadShedPcs : 48|1@1+ (1,0) [0|0] "" Vector__XXX
 SG_ BMS_hvilCoverVSense : 32|16@1+ (0.001,0) [0|0] "" Vector__XXX
 SG_ BMS_internalHvilSenseV : 16|16@1+ (0.001,0) [0|0] "" Vector__XXX
 SG_ BMS_fcLinkOkToEnergizeRequest : 9|2@1+ (1,0) [0|0] "" Vector__XXX
 SG_ BMS_pcsPwmDisable : 8|1@1+ (1,0) [0|0] "" Vector__XXX
 SG_ BMS_ensShouldBeActiveForDrive : 7|1@1+ (1,0) [0|0] "" Vector__XXX
 SG_ BMS_gpoHasCompleted : 6|1@1+ (1,0) [0|0] "" Vector__XXX
 SG_ BMS_packContactorRequest : 3|3@1+ (1,0) [0|0] "" Vector__XXX
 SG_ BMS_fcContactorRequest : 0|3@1+ (1,0) [0|0] "" Vector__XXX

BO_ 564 DCDC_power: 8 Vector__XXX
 SG_ DCDC_powerChecksum : 56|8@1+ (1,0) [0|0] "" Vector__XXX
 SG_ DCDC_powerCounter : 52|4@1+ (1,0) [0|0] "" Vector__XXX
 SG_ DCDC_powerMuxIndex M : 50|2@1+ (1,0) [0|0] "" Vector__XXX
 SG_ DCDC_type m0 : 45|2@1+ (1,0) [0|0] "" Vector__XXX
 SG_ DCDC_auxiliaryStageSaturationWarning m0 : 44|1@1+ (1,0) [0|0] "" Vector__XXX
 SG_ DCDC_packSideContLvOutputPowerLimit m1 : 40|10@1+ (10,0) [0|0] "" Vector__XXX
 SG_ DCDC_instantLvOutputPowerLimit m0 : 34|10@1+ (10,0) [0|0] "" Vector__XXX
 SG_ DCDC_minTargetContLvOutputPowerLimit m1 : 30|10@1+ (10,0) [0|0] "" Vector__XXX
 SG_ DCDC_continuousLvOutputPowerLimit m0 : 24|10@1+ (10,0) [0|0] "" Vector__XXX
 SG_ DCDC_severeOvLvInputPowerLimit m1 : 20|10@1+ (10,0) [0|0] "" Vector__XXX
 SG_ DCDC_filteredLvOutputPowerEstimated m0 : 12|12@1- (10,0) [0|0] "" Vector__XXX
 SG_ DCDC_severeUvLvOutputPowerLimit m1 : 10|10@1+ (10,0) [0|0] "" Vector__XXX
 SG_ DCDC_instantLvOutputPowerEstimated m0 : 0|12@1- (10,0) [0|0] "" Vector__XXX
 SG_ DCDC_transientLvOutputPowerLimit m1 : 0|10@1+ (10,0) [0|0] "" Vector__XXX

BO_ 565 OCS1P_debugTHS: 4 Vector__XXX
 SG_ OCS1P_humidity : 16|16@1+ (0.1,0) [0|0] "" Vector__XXX
 SG_ OCS1P_temperature : 0|16@1- (0.1,0) [0|0] "" Vector__XXX

BO_ 570 VCSEC_TPMSStatus: 8 Vector__XXX
 SG_ VCSEC_BLEOtherFailuresCount0 m4 : 56|5@1+ (1,0) [0|0] "" Vector__XXX
 SG_ VCSEC_BLEOtherFailuresCount1 m6 : 56|5@1+ (1,0) [0|0] "" Vector__XXX
 SG_ VCSEC_BLEOtherFailuresCount2 m8 : 56|5@1+ (1,0) [0|0] "" Vector__XXX
 SG_ VCSEC_BLEOtherFailuresCount3 m10 : 56|5@1+ (1,0) [0|0] "" Vector__XXX
 SG_ VCSEC_TPMSTotalResetsDueToSystem m24 : 56|8@1+ (1,0) [0|0] "" Vector__XXX
 SG_ VCSEC_TPMSTotalResetsDueToS_0000 m26 : 56|8@1+ (1,0) [0|0] "" Vector__XXX
 SG_ VCSEC_TPMSTotalResetsDueToS_0001 m28 : 56|8@1+ (1,0) [0|0] "" Vector__XXX
 SG_ VCSEC_TPMSTotalResetsDueToS_0002 m30 : 56|8@1+ (1,0) [0|0] "" Vector__XXX
 SG_ VCSEC_TPMSTotalResetsDueToUnknow m25 : 56|8@1+ (1,0) [0|0] "" Vector__XXX
 SG_ VCSEC_TPMSTotalResetsDueToU_0000 m27 : 56|8@1+ (1,0) [0|0] "" Vector__XXX
 SG_ VCSEC_TPMSTotalResetsDueToU_0001 m29 : 56|8@1+ (1,0) [0|0] "" Vector__XXX
 SG_ VCSEC_TPMSTotalResetsDueToU_0002 m31 : 56|8@1+ (1,0) [0|0] "" Vector__XXX
 SG_ VCSEC_TPMSDetailedAuthentication m16 : 48|4@1+ (1,0) [0|0] "" Vector__XXX
 SG_ VCSEC_TPMSDetailedAuthentic_0000 m17 : 48|4@1+ (1,0) [0|0] "" Vector__XXX
 SG_ VCSEC_TPMSDetailedAuthentic_0001 m18 : 48|4@1+ (1,0) [0|0] "" Vector__XXX
 SG_ VCSEC_TPMSDetailedAuthentic_0002 m19 : 48|4@1+ (1,0) [0|0] "" Vector__XXX
 SG_ VCSEC_TPMSTotalResetsDueToClockL m24 : 48|8@1+ (1,0) [0|0] "" Vector__XXX
 SG_ VCSEC_TPMSTotalResetsDueToC_0000 m26 : 48|8@1+ (1,0) [0|0] "" Vector__XXX
 SG_ VCSEC_TPMSTotalResetsDueToC_0001 m28 : 48|8@1+ (1,0) [0|0] "" Vector__XXX
 SG_ VCSEC_TPMSTotalResetsDueToC_0002 m30 : 48|8@1+ (1,0) [0|0] "" Vector__XXX
 SG_ VCSEC_TPMSTotalResetsDueToWatchd m25 : 48|8@1+ (1,0) [0|0] "" Vector__XXX
 SG_ VCSEC_TPMSTotalResetsDueToW_0000 m27 : 48|8@1+ (1,0) [0|0] "" Vector__XXX
 SG_ VCSEC_TPMSTotalResetsDueToW_0001 m29 : 48|8@1+ (1,0) [0|0] "" Vector__XXX
 SG_ VCSEC_TPMSTotalResetsDueToW_0002 m31 : 48|8@1+ (1,0) [0|0] "" Vector__XXX
 SG_ VCSEC_TPMSSensorType0 m20 : 44|3@1+ (1,0) [0|0] "" Vector__XXX
 SG_ VCSEC_TPMSSensorType1 m21 : 44|3@1+ (1,0) [0|0] "" Vector__XXX
 SG_ VCSEC_TPMSSensorType2 m22 : 44|3@1+ (1,0) [0|0] "" Vector__XXX
 SG_ VCSEC_TPMSSensorType3 m23 : 44|3@1+ (1,0) [0|0] "" Vector__XXX
 SG_ VCSEC_TPMSAuthenticateFailureRea m16 : 43|3@1+ (1,0) [0|0] "" Vector__XXX
 SG_ VCSEC_TPMSAuthenticateFailu_0000 m17 : 43|3@1+ (1,0) [0|0] "" Vector__XXX
 SG_ VCSEC_TPMSAuthenticateFailu_0001 m18 : 43|3@1+ (1,0) [0|0] "" Vector__XXX
 SG_ VCSEC_TPMSAuthenticateFailu_0002 m19 : 43|3@1+ (1,0) [0|0] "" Vector__XXX
 SG_ VCSEC_TPMSGenealogySensorState0 m20 : 41|3@1+ (1,0) [0|0] "" Vector__XXX
 SG_ VCSEC_TPMSGenealogySensorState1 m21 : 41|3@1+ (1,0) [0|0] "" Vector__XXX
 SG_ VCSEC_TPMSGenealogySensorState2 m22 : 41|3@1+ (1,0) [0|0] "" Vector__XXX
 SG_ VCSEC_TPMSGenealogySensorState3 m23 : 41|3@1+ (1,0) [0|0] "" Vector__XXX
 SG_ VCSEC_BLECRCErrorConnEventCount0 m4 : 40|14@1+ (1,0) [0|0] "" Vector__XXX
 SG_ VCSEC_BLECRCErrorConnEventCount1 m6 : 40|14@1+ (1,0) [0|0] "" Vector__XXX
 SG_ VCSEC_BLECRCErrorConnEventCount2 m8 : 40|14@1+ (1,0) [0|0] "" Vector__XXX
 SG_ VCSEC_BLECRCErrorConnEventCount3 m10 : 40|14@1+ (1,0) [0|0] "" Vector__XXX
 SG_ VCSEC_TPMSAuthenticateSensorStat m16 : 40|3@1+ (1,0) [0|0] "" Vector__XXX
 SG_ VCSEC_TPMSAuthenticateSenso_0000 m17 : 40|3@1+ (1,0) [0|0] "" Vector__XXX
 SG_ VCSEC_TPMSAuthenticateSenso_0001 m18 : 40|3@1+ (1,0) [0|0] "" Vector__XXX
 SG_ VCSEC_TPMSAuthenticateSenso_0002 m19 : 40|3@1+ (1,0) [0|0] "" Vector__XXX
 SG_ VCSEC_TPMSSensorMLXAppCRC0 m12 : 40|24@1+ (1,0) [0|0] "" Vector__XXX
 SG_ VCSEC_TPMSSensorMLXAppCRC1 m13 : 40|24@1+ (1,0) [0|0] "" Vector__XXX
 SG_ VCSEC_TPMSSensorMLXAppCRC2 m14 : 40|24@1+ (1,0) [0|0] "" Vector__XXX
 SG_ VCSEC_TPMSSensorMLXAppCRC3 m15 : 40|24@1+ (1,0) [0|0] "" Vector__XXX
 SG_ VCSEC_TPMSTotalResetsDueToCoreLo m25 : 40|8@1+ (1,0) [0|0] "" Vector__XXX
 SG_ VCSEC_TPMSTotalResetsDueToC_0003 m27 : 40|8@1+ (1,0) [0|0] "" Vector__XXX
 SG_ VCSEC_TPMSTotalResetsDueToC_0004 m29 : 40|8@1+ (1,0) [0|0] "" Vector__XXX
 SG_ VCSEC_TPMSTotalResetsDueToC_0005 m31 : 40|8@1+ (1,0) [0|0] "" Vector__XXX
 SG_ VCSEC_TPMSTotalResetsDueToVDDRLo m24 : 40|8@1+ (1,0) [0|0] "" Vector__XXX
 SG_ VCSEC_TPMSTotalResetsDueToV_0003 m26 : 40|8@1+ (1,0) [0|0] "" Vector__XXX
 SG_ VCSEC_TPMSTotalResetsDueToV_0004 m28 : 40|8@1+ (1,0) [0|0] "" Vector__XXX
 SG_ VCSEC_TPMSTotalResetsDueToV_0005 m30 : 40|8@1+ (1,0) [0|0] "" Vector__XXX
 SG_ VCSEC_TPMSTrimAdjusted0 m20 : 40|1@1+ (1,0) [0|0] "" Vector__XXX
 SG_ VCSEC_TPMSTrimAdjusted1 m21 : 40|1@1+ (1,0) [0|0] "" Vector__XXX
 SG_ VCSEC_TPMSTrimAdjusted2 m22 : 40|1@1+ (1,0) [0|0] "" Vector__XXX
 SG_ VCSEC_TPMSTrimAdjusted3 m23 : 40|1@1+ (1,0) [0|0] "" Vector__XXX
 SG_ VCSEC_TPMSSensor1Hash m33 : 36|28@1+ (1,0) [0|0] "" Vector__XXX
 SG_ VCSEC_TPMSSensor3Hash m34 : 36|28@1+ (1,0) [0|0] "" Vector__XXX
 SG_ VCSEC_TPMSFilteredBatVoltage3 m37 : 32|8@1+ (0.01,1.5) [0|0] "" Vector__XXX
 SG_ VCSEC_TPMSTemperatureCompen_0002 m36 : 32|8@1+ (0.01,1.5) [0|0] "" Vector__XXX
 SG_ VCSEC_TPMSTotalResetsDueToDCI0 m25 : 32|8@1+ (1,0) [0|0] "" Vector__XXX
 SG_ VCSEC_TPMSTotalResetsDueToDCI1 m27 : 32|8@1+ (1,0) [0|0] "" Vector__XXX
 SG_ VCSEC_TPMSTotalResetsDueToDCI2 m29 : 32|8@1+ (1,0) [0|0] "" Vector__XXX
 SG_ VCSEC_TPMSTotalResetsDueToDCI3 m31 : 32|8@1+ (1,0) [0|0] "" Vector__XXX
 SG_ VCSEC_TPMSTotalResetsDueToVDDLos m24 : 32|8@1+ (1,0) [0|0] "" Vector__XXX
 SG_ VCSEC_TPMSTotalResetsDueToV_0000 m26 : 32|8@1+ (1,0) [0|0] "" Vector__XXX
 SG_ VCSEC_TPMSTotalResetsDueToV_0001 m28 : 32|8@1+ (1,0) [0|0] "" Vector__XXX
 SG_ VCSEC_TPMSTotalResetsDueToV_0002 m30 : 32|8@1+ (1,0) [0|0] "" Vector__XXX
 SG_ VCSEC_BLEMissedConnEventCount0 m4 : 24|14@1+ (1,0) [0|0] "" Vector__XXX
 SG_ VCSEC_BLEMissedConnEventCount1 m6 : 24|14@1+ (1,0) [0|0] "" Vector__XXX
 SG_ VCSEC_BLEMissedConnEventCount2 m8 : 24|14@1+ (1,0) [0|0] "" Vector__XXX
 SG_ VCSEC_BLEMissedConnEventCount3 m10 : 24|14@1+ (1,0) [0|0] "" Vector__XXX
 SG_ VCSEC_TPMSFilteredBatVoltage1 m37 : 24|8@1+ (0.01,1.5) [0|0] "" Vector__XXX
 SG_ VCSEC_TPMSTemperatureCompen_0001 m36 : 24|8@1+ (0.01,1.5) [0|0] "" Vector__XXX
 SG_ VCSEC_TPMSTotalResetsDueToVDDSLo m24 : 24|8@1+ (1,0) [0|0] "" Vector__XXX
 SG_ VCSEC_TPMSTotalResetsDueToV_0006 m26 : 24|8@1+ (1,0) [0|0] "" Vector__XXX
 SG_ VCSEC_TPMSTotalResetsDueToV_0007 m28 : 24|8@1+ (1,0) [0|0] "" Vector__XXX
 SG_ VCSEC_TPMSTotalResetsDueToV_0008 m30 : 24|8@1+ (1,0) [0|0] "" Vector__XXX
 SG_ VCSEC_TPMSTotalResetsDueToW_0009 m25 : 24|8@1+ (1,0) [0|0] "" Vector__XXX
 SG_ VCSEC_TPMSTotalResetsDueToW_0010 m27 : 24|8@1+ (1,0) [0|0] "" Vector__XXX
 SG_ VCSEC_TPMSTotalResetsDueToW_0011 m29 : 24|8@1+ (1,0) [0|0] "" Vector__XXX
 SG_ VCSEC_TPMSTotalResetsDueToW_0012 m31 : 24|8@1+ (1,0) [0|0] "" Vector__XXX
 SG_ VCSEC_TPMSLastLocationSensor3 m35 : 19|3@1+ (1,0) [0|0] "" Vector__XXX
 SG_ VCSEC_TPMSFilteredBatVoltage2 m37 : 16|8@1+ (0.01,1.5) [0|0] "" Vector__XXX
 SG_ VCSEC_TPMSLastLocationSensor2 m35 : 16|3@1+ (1,0) [0|0] "" Vector__XXX
 SG_ VCSEC_TPMSTemperatureCompen_0000 m36 : 16|8@1+ (0.01,1.5) [0|0] "" Vector__XXX
 SG_ VCSEC_TPMSTotalResetsDueToPinRes m24 : 16|8@1+ (1,0) [0|0] "" Vector__XXX
 SG_ VCSEC_TPMSTotalResetsDueToP_0003 m26 : 16|8@1+ (1,0) [0|0] "" Vector__XXX
 SG_ VCSEC_TPMSTotalResetsDueToP_0004 m28 : 16|8@1+ (1,0) [0|0] "" Vector__XXX
 SG_ VCSEC_TPMSTotalResetsDueToP_0005 m30 : 16|8@1+ (1,0) [0|0] "" Vector__XXX
 SG_ VCSEC_TPMSTotalResetsDueToWakeup m25 : 16|8@1+ (1,0) [0|0] "" Vector__XXX
 SG_ VCSEC_TPMSTotalResetsDueToW_0006 m27 : 16|8@1+ (1,0) [0|0] "" Vector__XXX
 SG_ VCSEC_TPMSTotalResetsDueToW_0007 m29 : 16|8@1+ (1,0) [0|0] "" Vector__XXX
 SG_ VCSEC_TPMSTotalResetsDueToW_0008 m31 : 16|8@1+ (1,0) [0|0] "" Vector__XXX
 SG_ VCSEC_TPMSLastLocationSensor1 m35 : 11|3@1+ (1,0) [0|0] "" Vector__XXX
 SG_ VCSEC_BLESuccessfulConnEventCoun m4 : 8|15@1+ (1,0) [0|0] "" Vector__XXX
 SG_ VCSEC_BLESuccessfulConnEven_0000 m6 : 8|15@1+ (1,0) [0|0] "" Vector__XXX
 SG_ VCSEC_BLESuccessfulConnEven_0001 m8 : 8|15@1+ (1,0) [0|0] "" Vector__XXX
 SG_ VCSEC_BLESuccessfulConnEven_0002 m10 : 8|15@1+ (1,0) [0|0] "" Vector__XXX
 SG_ VCSEC_BLEUnsuccessfulConnEventRa m5 : 8|10@1+ (0.08,0) [0|0] "" Vector__XXX
 SG_ VCSEC_BLEUnsuccessfulConnEv_0000 m7 : 8|10@1+ (0.08,0) [0|0] "" Vector__XXX
 SG_ VCSEC_BLEUnsuccessfulConnEv_0001 m9 : 8|10@1+ (0.08,0) [0|0] "" Vector__XXX
 SG_ VCSEC_BLEUnsuccessfulConnEv_0002 m11 : 8|10@1+ (0.08,0) [0|0] "" Vector__XXX
 SG_ VCSEC_TPMSFilteredBatVoltage0 m37 : 8|8@1+ (0.01,1.5) [0|0] "" Vector__XXX
 SG_ VCSEC_TPMSLastLocationSensor0 m35 : 8|3@1+ (1,0) [0|0] "" Vector__XXX
 SG_ VCSEC_TPMSSensor0Hash m33 : 8|28@1+ (1,0) [0|0] "" Vector__XXX
 SG_ VCSEC_TPMSSensor2Hash m34 : 8|28@1+ (1,0) [0|0] "" Vector__XXX
 SG_ VCSEC_TPMSSensorMACAddress0 m0 : 8|48@1+ (1,0) [0|0] "" Vector__XXX
 SG_ VCSEC_TPMSSensorMACAddress1 m1 : 8|48@1+ (1,0) [0|0] "" Vector__XXX
 SG_ VCSEC_TPMSSensorMACAddress2 m2 : 8|48@1+ (1,0) [0|0] "" Vector__XXX
 SG_ VCSEC_TPMSSensorMACAddress3 m3 : 8|48@1+ (1,0) [0|0] "" Vector__XXX
 SG_ VCSEC_TPMSSensorParameterState m32 : 8|2@1+ (1,0) [0|0] "" Vector__XXX
 SG_ VCSEC_TPMSSensorTIAppCRC0 m12 : 8|32@1+ (1,0) [0|0] "" Vector__XXX
 SG_ VCSEC_TPMSSensorTIAppCRC1 m13 : 8|32@1+ (1,0) [0|0] "" Vector__XXX
 SG_ VCSEC_TPMSSensorTIAppCRC2 m14 : 8|32@1+ (1,0) [0|0] "" Vector__XXX
 SG_ VCSEC_TPMSSensorTIAppCRC3 m15 : 8|32@1+ (1,0) [0|0] "" Vector__XXX
 SG_ VCSEC_TPMSTemperatureCompensated m36 : 8|8@1+ (0.01,1.5) [0|0] "" Vector__XXX
 SG_ VCSEC_TPMSTotalResetsDueToPowerO m24 : 8|8@1+ (1,0) [0|0] "" Vector__XXX
 SG_ VCSEC_TPMSTotalResetsDueToP_0000 m26 : 8|8@1+ (1,0) [0|0] "" Vector__XXX
 SG_ VCSEC_TPMSTotalResetsDueToP_0001 m28 : 8|8@1+ (1,0) [0|0] "" Vector__XXX
 SG_ VCSEC_TPMSTotalResetsDueToP_0002 m30 : 8|8@1+ (1,0) [0|0] "" Vector__XXX
 SG_ VCSEC_TPMSTotalResetsDueToWarmRe m25 : 8|8@1+ (1,0) [0|0] "" Vector__XXX
 SG_ VCSEC_TPMSTotalResetsDueToW_0003 m27 : 8|8@1+ (1,0) [0|0] "" Vector__XXX
 SG_ VCSEC_TPMSTotalResetsDueToW_0004 m29 : 8|8@1+ (1,0) [0|0] "" Vector__XXX
 SG_ VCSEC_TPMSTotalResetsDueToW_0005 m31 : 8|8@1+ (1,0) [0|0] "" Vector__XXX
 SG_ VCSEC_TPMStotalAwakeTime0 m20 : 8|32@1+ (1,0) [0|0] "" Vector__XXX
 SG_ VCSEC_TPMStotalAwakeTime1 m21 : 8|32@1+ (1,0) [0|0] "" Vector__XXX
 SG_ VCSEC_TPMStotalAwakeTime2 m22 : 8|32@1+ (1,0) [0|0] "" Vector__XXX
 SG_ VCSEC_TPMStotalAwakeTime3 m23 : 8|32@1+ (1,0) [0|0] "" Vector__XXX
 SG_ VCSEC_TPMStotalCPUTime0 m16 : 8|32@1+ (1,0) [0|0] "" Vector__XXX
 SG_ VCSEC_TPMStotalCPUTime1 m17 : 8|32@1+ (1,0) [0|0] "" Vector__XXX
 SG_ VCSEC_TPMStotalCPUTime2 m18 : 8|32@1+ (1,0) [0|0] "" Vector__XXX
 SG_ VCSEC_TPMStotalCPUTime3 m19 : 8|32@1+ (1,0) [0|0] "" Vector__XXX
 SG_ VCSEC_TPMSSystemState : 6|1@1+ (1,0) [0|0] "" Vector__XXX
 SG_ VCSEC_TPMSStatusIndex M : 0|6@1+ (1,0) [0|0] "" Vector__XXX

BO_ 574 PARK_oocStatus: 8 Vector__XXX
 SG_ PARK_oocStatusChecksum : 56|8@1+ (1,0) [0|0] "" Vector__XXX
 SG_ PARK_oocStatusCounter : 52|4@1+ (1,0) [0|0] "" Vector__XXX
 SG_ PARK_oocOffCourse : 42|10@1+ (1,-512) [0|0] "" Vector__XXX
 SG_ PARK_oocHeight : 40|2@1+ (1,0) [0|0] "" Vector__XXX
 SG_ PARK_oocUntrackedTime : 34|6@1+ (0.1,0) [0|0] "" Vector__XXX
 SG_ PARK_oocCollisionSide : 31|3@1+ (1,0) [0|0] "" Vector__XXX
 SG_ PARK_oocVehicleY : 24|7@1+ (2,-128) [0|0] "" Vector__XXX
 SG_ PARK_oocVehicleX : 17|7@1+ (4,-114) [0|0] "" Vector__XXX
 SG_ PARK_oocDirectEchoOnly : 16|1@1+ (1,0) [0|0] "" Vector__XXX
 SG_ PARK_oocConfidence : 9|7@1+ (1,0) [0|0] "" Vector__XXX
 SG_ PARK_oocDistance : 0|9@1+ (1,0) [0|0] "" Vector__XXX

BO_ 576 PM_state2: 2 Vector__XXX
 SG_ PM_vehicleSpeedQF : 14|1@1+ (1,0) [0|0] "" Vector__XXX
 SG_ PM_ebrCmdState : 13|1@1+ (1,0) [0|0] "" Vector__XXX
 SG_ PM_vdcCmdState : 12|1@1+ (1,0) [0|0] "" Vector__XXX
 SG_ PM_state2Counter : 8|4@1+ (1,0) [0|0] "" Vector__XXX
 SG_ PM_state2Checksum : 0|8@1+ (1,0) [0|0] "" Vector__XXX

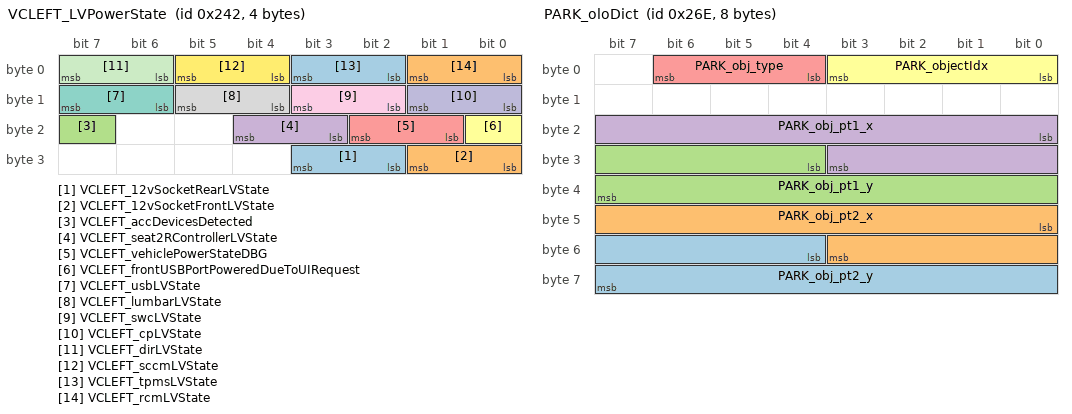
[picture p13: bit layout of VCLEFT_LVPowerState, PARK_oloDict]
BO_ 578 VCLEFT_LVPowerState: 4 Vector__XXX
 SG_ VCLEFT_12vSocketRearLVState : 26|2@1+ (1,0) [0|0] "" Vector__XXX
 SG_ VCLEFT_12vSocketFrontLVState : 24|2@1+ (1,0) [0|0] "" Vector__XXX
 SG_ VCLEFT_accDevicesDetected : 23|1@1+ (1,0) [0|0] "" Vector__XXX
 SG_ VCLEFT_seat2RControllerLVState : 19|2@1+ (1,0) [0|0] "" Vector__XXX
 SG_ VCLEFT_vehiclePowerStateDBG : 17|2@1+ (1,0) [0|0] "" Vector__XXX
 SG_ VCLEFT_frontUSBPortPoweredDueToUIRequest : 16|1@1+ (1,0) [0|0] "" Vector__XXX
 SG_ VCLEFT_usbLVState : 14|2@1+ (1,0) [0|0] "" Vector__XXX
 SG_ VCLEFT_lumbarLVState : 12|2@1+ (1,0) [0|0] "" Vector__XXX
 SG_ VCLEFT_swcLVState : 10|2@1+ (1,0) [0|0] "" Vector__XXX
 SG_ VCLEFT_cpLVState : 8|2@1+ (1,0) [0|0] "" Vector__XXX
 SG_ VCLEFT_dirLVState : 6|2@1+ (1,0) [0|0] "" Vector__XXX
 SG_ VCLEFT_sccmLVState : 4|2@1+ (1,0) [0|0] "" Vector__XXX
 SG_ VCLEFT_tpmsLVState : 2|2@1+ (1,0) [0|0] "" Vector__XXX
 SG_ VCLEFT_rcmLVState : 0|2@1+ (1,0) [0|0] "" Vector__XXX

BO_ 608 UNK_260: 8 Vector__XXX
 SG_ UNK_260_flag : 0|1@1+ (1,0) [0|1] "" Vector__XXX
 SG_ UNK_260_counter : 52|4@1+ (1,0) [0|15] "" Vector__XXX
 SG_ UNK_260_checksum : 56|8@1+ (1,0) [0|255] "" Vector__XXX

BO_ 622 PARK_oloDict: 8 Vector__XXX
 SG_ PARK_obj_pt2_y : 52|12@1+ (1,0) [0|0] "" Vector__XXX
 SG_ PARK_obj_pt2_x : 40|12@1+ (1,0) [0|0] "" Vector__XXX
 SG_ PARK_obj_pt1_y : 28|12@1+ (1,0) [0|0] "" Vector__XXX
 SG_ PARK_obj_pt1_x : 16|12@1+ (1,0) [0|0] "" Vector__XXX
 SG_ PARK_obj_type : 4|3@1+ (1,0) [0|0] "" Vector__XXX
 SG_ PARK_objectIdx : 0|4@1+ (1,0) [0|0] "" Vector__XXX

BO_ 630 DI_authenticityMsg: 8 Vector__XXX
 SG_ DI_salt7 : 56|8@1+ (1,0) [0|0] "" Vector__XXX
 SG_ DI_salt6 : 48|8@1+ (1,0) [0|0] "" Vector__XXX
 SG_ DI_salt5 : 40|8@1+ (1,0) [0|0] "" Vector__XXX
 SG_ DI_salt4 : 32|8@1+ (1,0) [0|0] "" Vector__XXX
 SG_ DI_salt3 : 24|8@1+ (1,0) [0|0] "" Vector__XXX
 SG_ DI_salt2 : 16|8@1+ (1,0) [0|0] "" Vector__XXX
 SG_ DI_salt1 : 8|8@1+ (1,0) [0|0] "" Vector__XXX
 SG_ DI_authenticityCommand : 0|8@1+ (1,0) [0|0] "" Vector__XXX

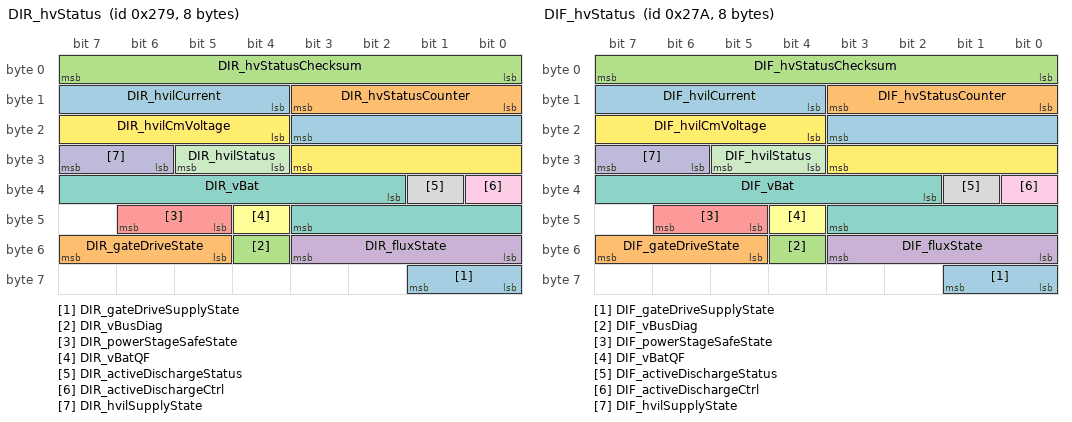
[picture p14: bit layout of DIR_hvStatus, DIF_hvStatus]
BO_ 633 DIR_hvStatus: 8 Vector__XXX
 SG_ DIR_gateDriveSupplyState : 56|2@1+ (1,0) [0|0] "" Vector__XXX
 SG_ DIR_gateDriveState : 53|3@1+ (1,0) [0|0] "" Vector__XXX
 SG_ DIR_vBusDiag : 52|1@1+ (1,0) [0|0] "" Vector__XXX
 SG_ DIR_fluxState : 48|4@1+ (1,0) [0|0] "" Vector__XXX
 SG_ DIR_powerStageSafeState : 45|2@1+ (1,0) [0|0] "" Vector__XXX
 SG_ DIR_vBatQF : 44|1@1+ (1,0) [0|0] "" Vector__XXX
 SG_ DIR_vBat : 34|10@1+ (1,0) [0|0] "" Vector__XXX
 SG_ DIR_activeDischargeStatus : 33|1@1+ (1,0) [0|0] "" Vector__XXX
 SG_ DIR_activeDischargeCtrl : 32|1@1+ (1,0) [0|0] "" Vector__XXX
 SG_ DIR_hvilSupplyState : 30|2@1+ (1,0) [0|0] "" Vector__XXX
 SG_ DIR_hvilStatus : 28|2@1+ (1,0) [0|0] "" Vector__XXX
 SG_ DIR_hvilCmVoltage : 20|8@1+ (0.08,0) [0|0] "" Vector__XXX
 SG_ DIR_hvilCurrent : 12|8@1+ (0.1,0) [0|0] "" Vector__XXX
 SG_ DIR_hvStatusCounter : 8|4@1+ (1,0) [0|0] "" Vector__XXX
 SG_ DIR_hvStatusChecksum : 0|8@1+ (1,0) [0|0] "" Vector__XXX

BO_ 634 DIF_hvStatus: 8 Vector__XXX
 SG_ DIF_gateDriveSupplyState : 56|2@1+ (1,0) [0|0] "" Vector__XXX
 SG_ DIF_gateDriveState : 53|3@1+ (1,0) [0|0] "" Vector__XXX
 SG_ DIF_vBusDiag : 52|1@1+ (1,0) [0|0] "" Vector__XXX
 SG_ DIF_fluxState : 48|4@1+ (1,0) [0|0] "" Vector__XXX
 SG_ DIF_powerStageSafeState : 45|2@1+ (1,0) [0|0] "" Vector__XXX
 SG_ DIF_vBatQF : 44|1@1+ (1,0) [0|0] "" Vector__XXX
 SG_ DIF_vBat : 34|10@1+ (1,0) [0|0] "" Vector__XXX
 SG_ DIF_activeDischargeStatus : 33|1@1+ (1,0) [0|0] "" Vector__XXX
 SG_ DIF_activeDischargeCtrl : 32|1@1+ (1,0) [0|0] "" Vector__XXX
 SG_ DIF_hvilSupplyState : 30|2@1+ (1,0) [0|0] "" Vector__XXX
 SG_ DIF_hvilStatus : 28|2@1+ (1,0) [0|0] "" Vector__XXX
 SG_ DIF_hvilCmVoltage : 20|8@1+ (0.08,0) [0|0] "" Vector__XXX
 SG_ DIF_hvilCurrent : 12|8@1+ (0.1,0) [0|0] "" Vector__XXX
 SG_ DIF_hvStatusCounter : 8|4@1+ (1,0) [0|0] "" Vector__XXX
 SG_ DIF_hvStatusChecksum : 0|8@1+ (1,0) [0|0] "" Vector__XXX

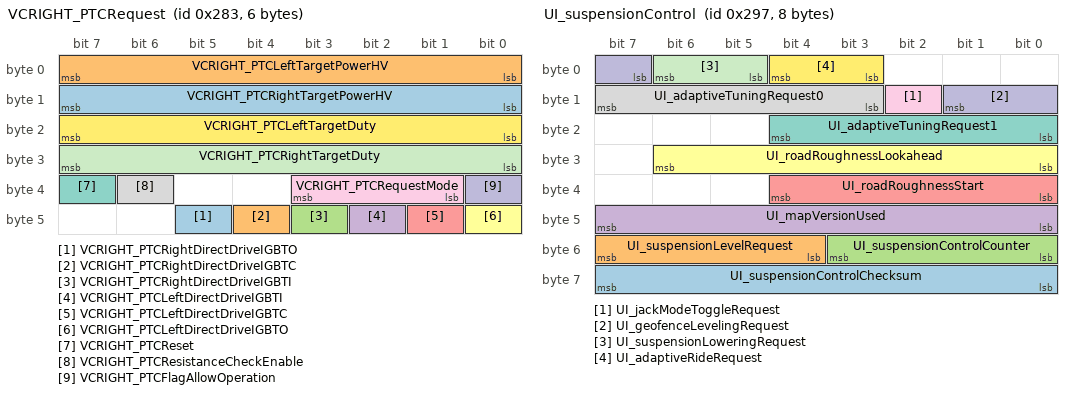
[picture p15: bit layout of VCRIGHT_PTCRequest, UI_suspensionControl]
BO_ 643 VCRIGHT_PTCRequest: 6 Vector__XXX
 SG_ VCRIGHT_PTCRightDirectDriveIGBTO : 45|1@1+ (1,0) [0|0] "" Vector__XXX
 SG_ VCRIGHT_PTCRightDirectDriveIGBTC : 44|1@1+ (1,0) [0|0] "" Vector__XXX
 SG_ VCRIGHT_PTCRightDirectDriveIGBTI : 43|1@1+ (1,0) [0|0] "" Vector__XXX
 SG_ VCRIGHT_PTCLeftDirectDriveIGBTI : 42|1@1+ (1,0) [0|0] "" Vector__XXX
 SG_ VCRIGHT_PTCLeftDirectDriveIGBTC : 41|1@1+ (1,0) [0|0] "" Vector__XXX
 SG_ VCRIGHT_PTCLeftDirectDriveIGBTO : 40|1@1+ (1,0) [0|0] "" Vector__XXX
 SG_ VCRIGHT_PTCReset : 39|1@1+ (1,0) [0|0] "" Vector__XXX
 SG_ VCRIGHT_PTCResistanceCheckEnable : 38|1@1+ (1,0) [0|0] "" Vector__XXX
 SG_ VCRIGHT_PTCRequestMode : 33|3@1+ (1,0) [0|0] "" Vector__XXX
 SG_ VCRIGHT_PTCFlagAllowOperation : 32|1@1+ (1,0) [0|0] "" Vector__XXX
 SG_ VCRIGHT_PTCRightTargetDuty : 24|8@1+ (0.5,0) [0|0] "" Vector__XXX
 SG_ VCRIGHT_PTCLeftTargetDuty : 16|8@1+ (0.5,0) [0|0] "" Vector__XXX
 SG_ VCRIGHT_PTCRightTargetPowerHV : 8|8@1+ (30,0) [0|0] "" Vector__XXX
 SG_ VCRIGHT_PTCLeftTargetPowerHV : 0|8@1+ (30,0) [0|0] "" Vector__XXX

BO_ 649 VCLEFT_logging10Hz: 8 Vector__XXX
 SG_ VCLEFT_hvacBlowerRsOnlineActive m0 : 63|1@1+ (1,0) [0|0] "" Vector__XXX
 SG_ VCLEFT_hvacBlowerSpiError m0 : 62|1@1+ (1,0) [0|0] "" Vector__XXX
 SG_ VCLEFT_hvacBlowerITerm m0 : 55|7@1+ (0.05,-1.5) [0|0] "" Vector__XXX
 SG_ VCLEFT_hvacBlowerCBCCtrlState m0 : 52|3@1+ (1,0) [0|0] "" Vector__XXX
 SG_ VCLEFT_hvacBlowerCBCEstState m0 : 48|4@1+ (1,0) [0|0] "" Vector__XXX
 SG_ VCLEFT_hvacBlower_IO_CBC_numUartErr m0 : 40|8@1+ (1,0) [0|0] "" Vector__XXX
 SG_ VCLEFT_hvacBlower_IO_CBC_Status m0 : 39|1@1+ (1,0) [0|0] "" Vector__XXX
 SG_ VCLEFT_hvacBlower_IO_CBC_TAIL_valid m0 : 38|1@1+ (1,0) [0|0] "" Vector__XXX
 SG_ VCLEFT_hvacBlower_IO_CBC_TAIL m0 : 34|4@1+ (1,0) [0|0] "" Vector__XXX
 SG_ VCLEFT_hvacBlower_IO_CBC_HEAD m0 : 30|4@1+ (1,0) [0|0] "" Vector__XXX
 SG_ VCLEFT_hvacBlowerIPhase2 m0 : 23|7@1+ (0.4,0) [0|0] "" Vector__XXX
 SG_ VCLEFT_hvacBlowerIPhase1 m0 : 16|7@1+ (0.4,0) [0|0] "" Vector__XXX
 SG_ VCLEFT_hvacBlowerIPhase0 m0 : 9|7@1+ (0.4,0) [0|0] "" Vector__XXX
 SG_ VCLEFT_hvacBlowerRs m0 : 1|8@1+ (0.25,0) [0|0] "" Vector__XXX
 SG_ VCLEFT_logging10HzIndex M : 0|1@1+ (1,0) [0|0] "" Vector__XXX

BO_ 654 UNK_28E_alive: 8 Vector__XXX
 SG_ UNK_28E_checksum : 0|8@1+ (1,0) [0|255] "" Vector__XXX
 SG_ UNK_28E_counter : 8|4@1+ (1,0) [0|15] "" Vector__XXX

BO_ 655 UNK_28F_alive: 8 Vector__XXX
 SG_ UNK_28F_checksum : 0|8@1+ (1,0) [0|255] "" Vector__XXX
 SG_ UNK_28F_counter : 8|4@1+ (1,0) [0|15] "" Vector__XXX

BO_ 660 UI_vehicleControl3: 8 Vector__XXX
 SG_ UI_selfParkStandingBy : 62|1@1+ (1,0) [0|0] "" Vector__XXX
 SG_ UI_derivedLoadshedFeature : 59|1@1+ (1,0) [0|0] "" Vector__XXX
 SG_ UI_closeTrunkRequest : 55|1@1+ (1,0) [0|0] "" Vector__XXX
 SG_ UI_windowRequest : 52|3@1+ (1,0) [0|0] "" Vector__XXX
 SG_ UI_windowRequestedRR : 51|1@1+ (1,0) [0|0] "" Vector__XXX
 SG_ UI_windowRequestedRL : 50|1@1+ (1,0) [0|0] "" Vector__XXX
 SG_ UI_windowRequestedFR : 49|1@1+ (1,0) [0|0] "" Vector__XXX
 SG_ UI_windowRequestedFL : 48|1@1+ (1,0) [0|0] "" Vector__XXX
 SG_ UI_windowPercentageRequest : 42|6@1- (5,0) [0|0] "" Vector__XXX
 SG_ UI_keepOnAccessoryPortsReq : 38|1@1+ (1,0) [0|0] "" Vector__XXX
 SG_ UI_blindSpotIndicatorLightRequest : 35|1@1+ (1,0) [0|0] "" Vector__XXX
 SG_ UI_displayRedShiftActive : 24|1@1+ (1,0) [0|0] "" Vector__XXX
 SG_ UI_UMC3UpdateInhibit : 22|1@1+ (1,0) [0|0] "" Vector__XXX
 SG_ UI_packTempLoggingRequest : 18|1@1+ (1,0) [0|0] "" Vector__XXX
 SG_ UI_shortHornRequest : 17|1@1+ (1,0) [0|0] "" Vector__XXX
 SG_ UI_VCSECFeature5 : 16|1@1+ (1,0) [0|0] "" Vector__XXX
 SG_ UI_VCSECFeature4 : 15|1@1+ (1,0) [0|0] "" Vector__XXX
 SG_ UI_VCSECFeature3 : 14|1@1+ (1,0) [0|0] "" Vector__XXX
 SG_ UI_VCSECFeature2 : 13|1@1+ (1,0) [0|0] "" Vector__XXX
 SG_ UI_headlightPulseRequest : 12|1@1+ (1,0) [0|0] "" Vector__XXX
 SG_ UI_steeringWheelHeatLevelReq : 10|2@1+ (1,0) [0|0] "" Vector__XXX
 SG_ UI_steeringWheelHeatAutoReq : 9|1@1+ (1,0) [0|0] "" Vector__XXX
 SG_ UI_lightShowClosuresEnabled : 8|1@1+ (1,0) [0|0] "" Vector__XXX
 SG_ UI_keyPairResponse : 6|2@1+ (1,0) [0|0] "" Vector__XXX
 SG_ UI_drivingSideVEH : 4|2@1+ (1,0) [0|0] "" Vector__XXX
 SG_ UI_phoneCallActive : 3|1@1+ (1,0) [0|0] "" Vector__XXX
 SG_ UI_keylessDrivingEnabled : 2|1@1+ (1,0) [0|0] "" Vector__XXX
 SG_ UI_lightFlashRequest : 0|2@1+ (1,0) [0|0] "" Vector__XXX

BO_ 661 UI_powerRationalityConfig: 8 Vector__XXX
 SG_ UI_powerRationalityConfigIndex M : 56|8@1+ (1,0) [0|0] "" Vector__XXX
 SG_ UI_vcleftCfgCutoffDynamicC m8 : 32|16@1- (50,0) [0|0] "" Vector__XXX
 SG_ UI_vcleftCfgCutoffStaticC m7 : 32|16@1- (50,0) [0|0] "" Vector__XXX
 SG_ UI_vcleftCfgRationalityDynamicC m2 : 32|16@1- (50,0) [0|0] "" Vector__XXX
 SG_ UI_vcleftCfgRationalityStaticC m1 : 32|16@1- (50,0) [0|0] "" Vector__XXX
 SG_ UI_vcrightCfgCutoffDynamicC m11 : 32|16@1- (50,0) [0|0] "" Vector__XXX
 SG_ UI_vcrightCfgCutoffStaticC m10 : 32|16@1- (50,0) [0|0] "" Vector__XXX
 SG_ UI_vcrightCfgRationalityDynamicC m5 : 32|16@1- (50,0) [0|0] "" Vector__XXX
 SG_ UI_vcrightCfgRationalityStaticC m4 : 32|16@1- (50,0) [0|0] "" Vector__XXX
 SG_ UI_vcleftCfgCutoffDynamicB m8 : 16|16@1- (1,0) [0|0] "" Vector__XXX
 SG_ UI_vcleftCfgCutoffStaticB m7 : 16|16@1- (1,0) [0|0] "" Vector__XXX
 SG_ UI_vcleftCfgRationalityDynamicB m2 : 16|16@1- (1,0) [0|0] "" Vector__XXX
 SG_ UI_vcleftCfgRationalityStaticB m1 : 16|16@1- (1,0) [0|0] "" Vector__XXX
 SG_ UI_vcrightCfgCutoffDynamicB m11 : 16|16@1- (1,0) [0|0] "" Vector__XXX
 SG_ UI_vcrightCfgCutoffStaticB m10 : 16|16@1- (1,0) [0|0] "" Vector__XXX
 SG_ UI_vcrightCfgRationalityDynamicB m5 : 16|16@1- (1,0) [0|0] "" Vector__XXX
 SG_ UI_vcrightCfgRationalityStaticB m4 : 16|16@1- (1,0) [0|0] "" Vector__XXX
 SG_ UI_vcleftCfgCutoffTime1 m6 : 12|4@1+ (1,0) [0|0] "" Vector__XXX
 SG_ UI_vcleftCfgRationalityTime1 m0 : 12|4@1+ (1,0) [0|0] "" Vector__XXX
 SG_ UI_vcrightCfgCutoffTime1 m9 : 12|4@1+ (1,0) [0|0] "" Vector__XXX
 SG_ UI_vcrightCfgRationalityTime1 m3 : 12|4@1+ (1,0) [0|0] "" Vector__XXX
 SG_ UI_vcleftCfgCutoffThreshold1 m6 : 8|4@1+ (1,0) [0|0] "" Vector__XXX
 SG_ UI_vcleftCfgRationalityThreshold1 m0 : 8|4@1+ (1,0) [0|0] "" Vector__XXX
 SG_ UI_vcrightCfgCutoffThreshold1 m9 : 8|4@1+ (1,0) [0|0] "" Vector__XXX
 SG_ UI_vcrightCfgRationalityThreshold1 m3 : 8|4@1+ (1,0) [0|0] "" Vector__XXX
 SG_ UI_vcleftCfgCutoffTime0 m6 : 4|4@1+ (1,0) [0|0] "" Vector__XXX
 SG_ UI_vcleftCfgRationalityTime0 m0 : 4|4@1+ (1,0) [0|0] "" Vector__XXX
 SG_ UI_vcrightCfgCutoffTime0 m9 : 4|4@1+ (1,0) [0|0] "" Vector__XXX
 SG_ UI_vcrightCfgRationalityTime0 m3 : 4|4@1+ (1,0) [0|0] "" Vector__XXX
 SG_ UI_vcleftCfgCutoffDynamicA m8 : 0|16@1+ (50,0) [0|0] "" Vector__XXX
 SG_ UI_vcleftCfgCutoffStaticA m7 : 0|16@1+ (50,0) [0|0] "" Vector__XXX
 SG_ UI_vcleftCfgCutoffThreshold0 m6 : 0|4@1+ (1,0) [0|0] "" Vector__XXX
 SG_ UI_vcleftCfgRationalityDynamicA m2 : 0|16@1+ (50,0) [0|0] "" Vector__XXX
 SG_ UI_vcleftCfgRationalityStaticA m1 : 0|16@1+ (50,0) [0|0] "" Vector__XXX
 SG_ UI_vcleftCfgRationalityThreshold0 m0 : 0|4@1+ (1,0) [0|0] "" Vector__XXX
 SG_ UI_vcrightCfgCutoffDynamicA m11 : 0|16@1+ (50,0) [0|0] "" Vector__XXX
 SG_ UI_vcrightCfgCutoffStaticA m10 : 0|16@1+ (50,0) [0|0] "" Vector__XXX
 SG_ UI_vcrightCfgCutoffThreshold0 m9 : 0|4@1+ (1,0) [0|0] "" Vector__XXX
 SG_ UI_vcrightCfgRationalityDynamicA m5 : 0|16@1+ (50,0) [0|0] "" Vector__XXX
 SG_ UI_vcrightCfgRationalityStaticA m4 : 0|16@1+ (50,0) [0|0] "" Vector__XXX
 SG_ UI_vcrightCfgRationalityThreshold0 m3 : 0|4@1+ (1,0) [0|0] "" Vector__XXX

BO_ 663 UI_suspensionControl: 8 Vector__XXX
 SG_ UI_suspensionControlChecksum : 56|8@1+ (1,0) [0|0] "" Vector__XXX
 SG_ UI_suspensionLevelRequest : 52|4@1+ (1,0) [0|0] "" Vector__XXX
 SG_ UI_suspensionControlCounter : 48|4@1+ (1,0) [0|0] "" Vector__XXX
 SG_ UI_mapVersionUsed : 40|8@1+ (1,0) [0|0] "" Vector__XXX
 SG_ UI_roadRoughnessStart : 32|5@1+ (10,0) [0|0] "" Vector__XXX
 SG_ UI_roadRoughnessLookahead : 24|7@1+ (0.01,0) [0|0] "" Vector__XXX
 SG_ UI_adaptiveTuningRequest1 : 16|5@1- (0.1,0) [0|0] "" Vector__XXX
 SG_ UI_adaptiveTuningRequest0 : 11|5@1- (0.1,0) [0|0] "" Vector__XXX
 SG_ UI_jackModeToggleRequest : 10|1@1+ (1,0) [0|0] "" Vector__XXX
 SG_ UI_geofenceLevelingRequest : 7|3@1+ (1,0) [0|0] "" Vector__XXX
 SG_ UI_suspensionLoweringRequest : 5|2@1+ (1,0) [0|0] "" Vector__XXX
 SG_ UI_adaptiveRideRequest : 3|2@1+ (1,0) [0|0] "" Vector__XXX

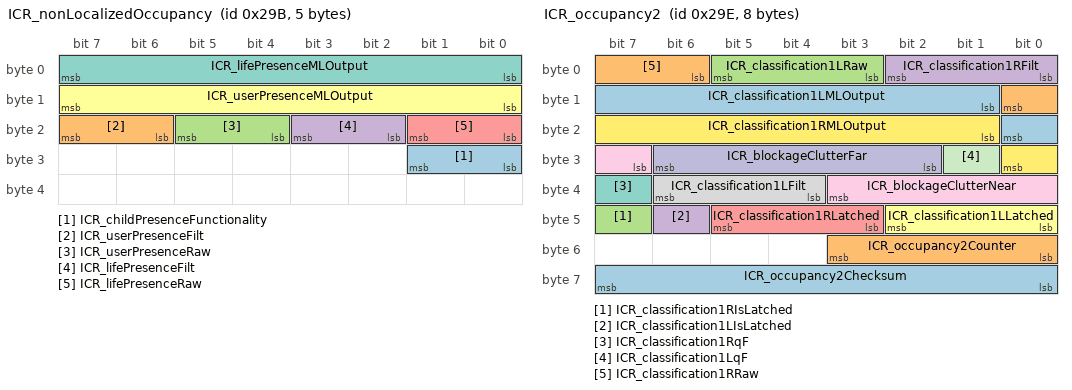
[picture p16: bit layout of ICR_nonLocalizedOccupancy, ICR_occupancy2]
BO_ 667 ICR_nonLocalizedOccupancy: 5 Vector__XXX
 SG_ ICR_childPresenceFunctionality : 24|2@1+ (1,0) [0|0] "" Vector__XXX
 SG_ ICR_userPresenceFilt : 22|2@1+ (1,0) [0|0] "" Vector__XXX
 SG_ ICR_userPresenceRaw : 20|2@1+ (1,0) [0|0] "" Vector__XXX
 SG_ ICR_lifePresenceFilt : 18|2@1+ (1,0) [0|0] "" Vector__XXX
 SG_ ICR_lifePresenceRaw : 16|2@1+ (1,0) [0|0] "" Vector__XXX
 SG_ ICR_userPresenceMLOutput : 8|8@1+ (0.004,0) [0|0] "" Vector__XXX
 SG_ ICR_lifePresenceMLOutput : 0|8@1+ (0.004,0) [0|0] "" Vector__XXX

BO_ 670 ICR_occupancy2: 8 Vector__XXX
 SG_ ICR_occupancy2Checksum : 56|8@1+ (1,0) [0|0] "" Vector__XXX
 SG_ ICR_occupancy2Counter : 48|4@1+ (1,0) [0|0] "" Vector__XXX
 SG_ ICR_classification1RIsLatched : 47|1@1+ (1,0) [0|0] "" Vector__XXX
 SG_ ICR_classification1LIsLatched : 46|1@1+ (1,0) [0|0] "" Vector__XXX
 SG_ ICR_classification1RLatched : 43|3@1+ (1,0) [0|0] "" Vector__XXX
 SG_ ICR_classification1LLatched : 40|3@1+ (1,0) [0|0] "" Vector__XXX
 SG_ ICR_classification1RqF : 39|1@1+ (1,0) [0|0] "" Vector__XXX
 SG_ ICR_classification1LFilt : 36|3@1+ (1,0) [0|0] "" Vector__XXX
 SG_ ICR_blockageClutterNear : 31|5@1- (0.5,-1.5) [0|0] "" Vector__XXX
 SG_ ICR_blockageClutterFar : 26|5@1- (0.5,-1.5) [0|0] "" Vector__XXX
 SG_ ICR_classification1LqF : 25|1@1+ (1,0) [0|0] "" Vector__XXX
 SG_ ICR_classification1RMLOutput : 17|8@1+ (0.004,0) [0|0] "" Vector__XXX
 SG_ ICR_classification1LMLOutput : 9|8@1+ (0.004,0) [0|0] "" Vector__XXX
 SG_ ICR_classification1RRaw : 6|3@1+ (1,0) [0|0] "" Vector__XXX
 SG_ ICR_classification1LRaw : 3|3@1+ (1,0) [0|0] "" Vector__XXX
 SG_ ICR_classification1RFilt : 0|3@1+ (1,0) [0|0] "" Vector__XXX

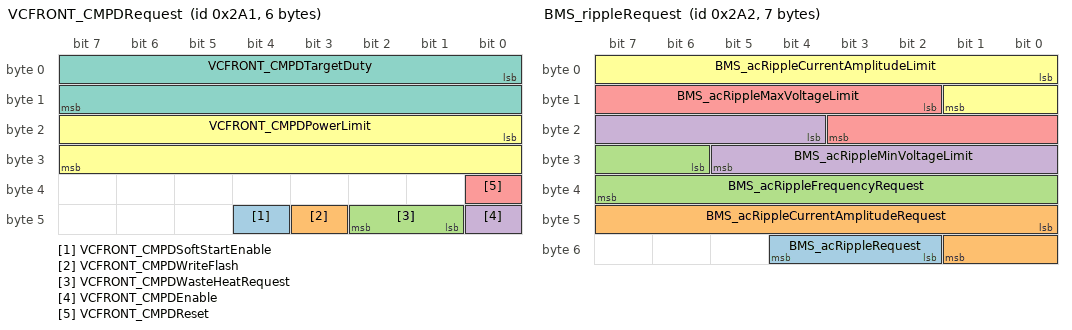
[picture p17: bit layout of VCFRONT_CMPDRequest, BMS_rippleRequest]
BO_ 673 VCFRONT_CMPDRequest: 6 Vector__XXX
 SG_ VCFRONT_CMPDSoftStartEnable : 44|1@1+ (1,0) [0|0] "" Vector__XXX
 SG_ VCFRONT_CMPDWriteFlash : 43|1@1+ (1,0) [0|0] "" Vector__XXX
 SG_ VCFRONT_CMPDWasteHeatRequest : 41|2@1+ (1,0) [0|0] "" Vector__XXX
 SG_ VCFRONT_CMPDEnable : 40|1@1+ (1,0) [0|0] "" Vector__XXX
 SG_ VCFRONT_CMPDReset : 32|1@1+ (1,0) [0|0] "" Vector__XXX
 SG_ VCFRONT_CMPDPowerLimit : 16|16@1+ (1,0) [0|0] "" Vector__XXX
 SG_ VCFRONT_CMPDTargetDuty : 0|16@1+ (0.1,0) [0|0] "" Vector__XXX

BO_ 674 BMS_rippleRequest: 7 Vector__XXX
 SG_ BMS_acRippleRequest : 50|3@1+ (1,0) [0|0] "" Vector__XXX
 SG_ BMS_acRippleCurrentAmplitudeRequest : 40|10@1+ (1,0) [0|0] "" Vector__XXX
 SG_ BMS_acRippleFrequencyRequest : 30|10@1+ (1,0) [0|0] "" Vector__XXX
 SG_ BMS_acRippleMinVoltageLimit : 20|10@1+ (1,0) [0|0] "" Vector__XXX
 SG_ BMS_acRippleMaxVoltageLimit : 10|10@1+ (1,0) [0|0] "" Vector__XXX
 SG_ BMS_acRippleCurrentAmplitudeLimit : 0|10@1+ (1,0) [0|0] "" Vector__XXX

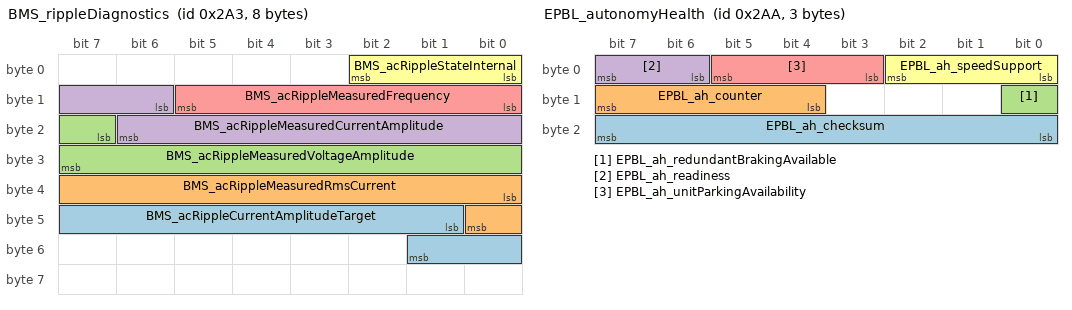
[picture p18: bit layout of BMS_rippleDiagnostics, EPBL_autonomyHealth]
BO_ 675 BMS_rippleDiagnostics: 8 Vector__XXX
 SG_ BMS_acRippleCurrentAmplitudeTarget : 41|9@1+ (1,0) [0|0] "" Vector__XXX
 SG_ BMS_acRippleMeasuredRmsCurrent : 32|9@1+ (1,0) [0|0] "" Vector__XXX
 SG_ BMS_acRippleMeasuredVoltageAmplitude : 23|9@1+ (1,0) [0|0] "" Vector__XXX
 SG_ BMS_acRippleMeasuredCurrentAmplitude : 14|9@1+ (1,0) [0|0] "" Vector__XXX
 SG_ BMS_acRippleMeasuredFrequency : 8|6@1+ (1,80) [0|0] "" Vector__XXX
 SG_ BMS_acRippleStateInternal : 0|3@1+ (1,0) [0|0] "" Vector__XXX

BO_ 678 CMPD_motorState: 8 Vector__XXX
 SG_ CMPD_motorOverloadCountdown : 16|13@1+ (1,0) [0|0] "" Vector__XXX
 SG_ CMPD_motorCurrent : 0|16@1+ (0.1,0) [0|0] "" Vector__XXX

BO_ 682 EPBL_autonomyHealth: 3 Vector__XXX
 SG_ EPBL_ah_checksum : 16|8@1+ (1,0) [0|0] "" Vector__XXX
 SG_ EPBL_ah_counter : 12|4@1+ (1,0) [0|0] "" Vector__XXX
 SG_ EPBL_ah_redundantBrakingAvailable : 8|1@1+ (1,0) [0|0] "" Vector__XXX
 SG_ EPBL_ah_readiness : 6|2@1+ (1,0) [0|0] "" Vector__XXX
 SG_ EPBL_ah_unitParkingAvailability : 3|3@1+ (1,0) [0|0] "" Vector__XXX
 SG_ EPBL_ah_speedSupport : 0|3@1+ (1,0) [0|0] "" Vector__XXX

BO_ 693 PCS_dcdcRailStatus_2B5: 8 Vector__XXX
 SG_ PCS_dcdcLvOutputCurrent : 32|13@1- (0.1,0) [0|0] "" Vector__XXX
 SG_ PCS_dcdcHvBusVolt : 16|14@1+ (0.1,0) [0|0] "" Vector__XXX
 SG_ PCS_dcdcLvBusVolt : 0|13@1+ (0.01,0) [0|0] "" Vector__XXX

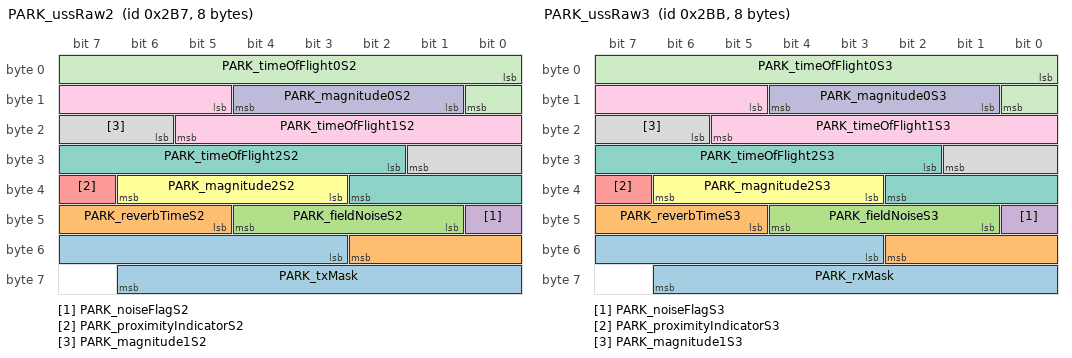
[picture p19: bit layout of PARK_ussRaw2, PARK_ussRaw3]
BO_ 695 PARK_ussRaw2: 8 Vector__XXX
 SG_ PARK_txMask : 51|12@1+ (1,0) [0|0] "" Vector__XXX
 SG_ PARK_reverbTimeS2 : 45|6@1+ (0.0512,0) [0|0] "" Vector__XXX
 SG_ PARK_fieldNoiseS2 : 41|4@1+ (1,0) [0|0] "" Vector__XXX
 SG_ PARK_noiseFlagS2 : 40|1@1+ (1,0) [0|0] "" Vector__XXX
 SG_ PARK_proximityIndicatorS2 : 39|1@1+ (1,0) [0|0] "" Vector__XXX
 SG_ PARK_magnitude2S2 : 35|4@1+ (2,0) [0|0] "" Vector__XXX
 SG_ PARK_timeOfFlight2S2 : 26|9@1+ (0.0512,0) [0|0] "" Vector__XXX
 SG_ PARK_magnitude1S2 : 22|4@1+ (2,0) [0|0] "" Vector__XXX
 SG_ PARK_timeOfFlight1S2 : 13|9@1+ (0.0512,0) [0|0] "" Vector__XXX
 SG_ PARK_magnitude0S2 : 9|4@1+ (2,0) [0|0] "" Vector__XXX
 SG_ PARK_timeOfFlight0S2 : 0|9@1+ (0.0512,0) [0|0] "" Vector__XXX

BO_ 699 PARK_ussRaw3: 8 Vector__XXX
 SG_ PARK_rxMask : 51|12@1+ (1,0) [0|0] "" Vector__XXX
 SG_ PARK_reverbTimeS3 : 45|6@1+ (0.0512,0) [0|0] "" Vector__XXX
 SG_ PARK_fieldNoiseS3 : 41|4@1+ (1,0) [0|0] "" Vector__XXX
 SG_ PARK_noiseFlagS3 : 40|1@1+ (1,0) [0|0] "" Vector__XXX
 SG_ PARK_proximityIndicatorS3 : 39|1@1+ (1,0) [0|0] "" Vector__XXX
 SG_ PARK_magnitude2S3 : 35|4@1+ (2,0) [0|0] "" Vector__XXX
 SG_ PARK_timeOfFlight2S3 : 26|9@1+ (0.0512,0) [0|0] "" Vector__XXX
 SG_ PARK_magnitude1S3 : 22|4@1+ (2,0) [0|0] "" Vector__XXX
 SG_ PARK_timeOfFlight1S3 : 13|9@1+ (0.0512,0) [0|0] "" Vector__XXX
 SG_ PARK_magnitude0S3 : 9|4@1+ (2,0) [0|0] "" Vector__XXX
 SG_ PARK_timeOfFlight0S3 : 0|9@1+ (0.0512,0) [0|0] "" Vector__XXX

CM_ BO_ 49 "ESP32-DualCAN Model3_CH. Seen on this car: 8-byte frames; fit good (bits covered 92%, mux 100%, ranges 100%).";
VAL_ 49 EPAS3P_state 0 "STANDBY" 1 "DRIVE" 2 "SUPPORT" 3 "CHARGE" 4 "FEIM" 5 "CLEAR_FAULT" 6 "FAULT" 7 "WELD" 8 "TEST" 9 "SNA" 10 "DIAG" ;
CM_ BO_ 81 "ESP32-DualCAN Model3_CH. Seen on this car: 8-byte frames; fit good (bits covered 92%, mux 100%, ranges 100%).";
VAL_ 81 EPAS3S_state 0 "STANDBY" 1 "DRIVE" 2 "SUPPORT" 3 "CHARGE" 4 "FEIM" 5 "CLEAR_FAULT" 6 "FAULT" 7 "WELD" 8 "TEST" 9 "SNA" 10 "DIAG" ;
CM_ BO_ 82 "ESP32-DualCAN Model3_CH. Seen on this car: 8-byte frames; fit ok (bits covered 100%, mux 100%, ranges 100%).";
VAL_ 82 EPAS3P_eacStatus 0 "INHIBITED" 1 "AVAILABLE" 2 "ACTIVE" 3 "FAULT" 4 "LKA_ELK_AVAILABLE" 5 "LKA_ACTIVE" 6 "ELK_AVAILABLE" 7 "ELK_ACTIVE" ;
VAL_ 82 EPAS3P_handsOnLevel 0 "0" 1 "1" 2 "2" 3 "3" ;
VAL_ 82 EPAS3P_torsionBarTorque 4094 "UNDEFINABLE_DATA" 4095 "SNA" ;
VAL_ 82 EPAS3P_eacErrorCode 0 "EAC_ERROR_IDLE" 1 "EAC_ERROR_MIN_SPEED" 2 "EAC_ERROR_MAX_SPEED" 3 "EAC_ERROR_HANDS_ON" 4 "EAC_ERROR_TMP_FAULT" 5 "EAR_ERROR_MAX_STEER_DELTA" 6 "EAC_ERROR_HIGH_ANGLE_REQ" 7 "EAC_ERROR_HIGH_ANGLE_RATE_REQ" 8 "EAC_ERROR_HIGH_ANGLE_SAFETY" 9 "EAC_ERROR_HIGH_ANGLE_RATE_SAFETY" 10 "EAC_ERROR_HIGH_MMOT_SAFETY" 11 "EAC_ERROR_HIGH_TORSION_SAFETY" 12 "EAC_ERROR_LOW_ASSIST" 13 "EAC_ERROR_PINION_VEL_DIFF" 14 "EAC_EXTERNAL_MONITOR_INHIBIT" 15 "SNA" ;
VAL_ 82 EPAS3P_steeringRackForce 1022 "NOT_IN_SPEC" 1023 "SNA" ;
VAL_ 82 EPAS3P_steeringFault 0 "NO_FAULT" 1 "FAULT" ;
VAL_ 82 EPAS3P_steeringReduced 0 "NORMAL_ASSIST" 1 "REDUCED_ASSIST" ;
VAL_ 82 EPAS3P_internalSASQF 0 "UNDEFINABLE_ACCURACY" 1 "IN_SPEC" ;
VAL_ 82 EPAS3P_currentTuneMode 0 "DM_COMFORT" 1 "DM_STANDARD" 2 "DM_SPORT" 3 "RWD_COMFORT" 4 "RWD_STANDARD" 5 "RWD_SPORT" ;
CM_ BO_ 290 "ESP32-DualCAN Model3_VEH. Seen on this car: 8-byte frames; fit good (bits covered 100%, mux 100%, ranges 100%).";
VAL_ 290 VCLEFT_rearDoorState 0 "UNKNOWN" 1 "CLOSED" 2 "WAIT_FOR_SHORT_DROP" 3 "RELEASING_LATCH" 4 "OPEN" 5 "AJAR" 6 "INIT" ;
VAL_ 290 VCLEFT_frontDoorState 0 "UNKNOWN" 1 "CLOSED" 2 "WAIT_FOR_SHORT_DROP" 3 "RELEASING_LATCH" 4 "OPEN" 5 "AJAR" 6 "INIT" ;
CM_ BO_ 296 "ESP32-DualCAN Model3_VEH. Seen on this car: 6-byte frames; fit ok (bits covered 100%, mux 100%, ranges 100%).";
VAL_ 296 DI_proximity 0 "SNA" 1 "DISCONNECTED" 2 "UNLATCHED" 3 "LATCHED" ;
VAL_ 296 DI_vehicleSpeedLimitReason 0 "NONE" 1 "DRIVE_UNIT_LIMIT" 2 "FACTORY_LOW_BRAKE_FLUID" 3 "FACTORY_MODE" 4 "SERVICE_MODE" 5 "MAX_CAR_CONFIG" 6 "SPINDOWN_LEARNING" 7 "TRAILER_MODE" 8 "TAS" 9 "LOAD_SHED" 10 "FRUNK_OPEN" 11 "USER" ;
VAL_ 296 DI_vehicleSpeedLimit 511 "SNA" ;
VAL_ 296 DI_vehicleSpeedLimitType 0 "NONE" 1 "USER" 2 "POWERTRAIN" ;
CM_ BO_ 305 "ESP32-DualCAN Model3_CH. Seen on this car: 8-byte frames; fit good (bits covered 100%, mux 100%, ranges 100%, checksum 100%).";
CM_ BO_ 313 "ESP32-DualCAN Model3_VEH. Seen on this car: 1-byte frames; fit poor (bits covered 0%, mux 100%, ranges 100%).";
CM_ BO_ 321 "ESP32-DualCAN Model3_CH. Seen on this car: 8-byte frames; fit good (bits covered 100%, mux 100%, ranges 100%, checksum 100%).";
CM_ BO_ 326 "ESP32-DualCAN Model3_CH. Seen on this car: 8-byte frames; fit good (bits covered 88%, mux 100%, ranges 100%, checksum 100%).";
CM_ BO_ 329 "ESP32-DualCAN Model3_CH. Seen on this car: 8-byte frames; fit good (bits covered 100%, mux 100%, ranges 100%, checksum 100%).";
VAL_ 329 IBST_brakeTorqueTarget 8191 "SNA" ;
CM_ BO_ 331 "ESP32-DualCAN Model3_CH. Not seen on this car in the logs.";
CM_ BO_ 337 "Unknown 1 Hz status: only bits 48-49 change.";
CM_ BO_ 356 "ESP32-DualCAN Model3_VEH. Not seen on this car in the logs.";
CM_ BO_ 357 "ESP32-DualCAN Model3_VEH. Not seen on this car in the logs.";
CM_ BO_ 358 "ESP32-DualCAN Model3_VEH. Not seen on this car in the logs.";
VAL_ 358 TAS_temp_FR_R 31 "SNA" ;
VAL_ 358 TAS_temp_RR_R 31 "SNA" ;
VAL_ 358 TAS_temp_FR_C 31 "SNA" ;
VAL_ 358 TAS_temp_RR_C 31 "SNA" ;
VAL_ 358 TAS_temp_FL_R 31 "SNA" ;
VAL_ 358 TAS_temp_RL_R 31 "SNA" ;
VAL_ 358 TAS_temp_FL_C 31 "SNA" ;
VAL_ 358 TAS_temp_RL_C 31 "SNA" ;
VAL_ 358 TAS_tempIndex 0 "Mux0" 1 "Mux1" 2 "Mux2" ;
CM_ BO_ 359 "ESP32-DualCAN Model3_VEH. Not seen on this car in the logs.";
CM_ BO_ 395 "ESP32-DualCAN Model3_CH. Not seen on this car in the logs.";
CM_ BO_ 401 "ESP32-DualCAN Model3_CH. Not seen on this car in the logs.";
CM_ BO_ 405 "ESP32-DualCAN Model3_VEH. Not seen on this car in the logs.";
VAL_ 405 DIF_currentLimit 8191 "SNA" ;
CM_ BO_ 409 "ESP32-DualCAN Model3_VEH. Not seen on this car in the logs.";
VAL_ 409 TAS_uiHeightRR 63 "SNA" ;
VAL_ 409 TAS_uiHeightRL 63 "SNA" ;
VAL_ 409 TAS_uiHeightFR 63 "SNA" ;
VAL_ 409 TAS_uiHeightFL 63 "SNA" ;
VAL_ 409 TAS_adaptiveActivityRR_R 31 "SNA" ;
VAL_ 409 TAS_adaptiveActivityRR_C 31 "SNA" ;
VAL_ 409 TAS_adaptiveActivityRL_R 31 "SNA" ;
VAL_ 409 TAS_adaptiveActivityRL_C 31 "SNA" ;
VAL_ 409 TAS_adaptiveActivityFR_R 31 "SNA" ;
VAL_ 409 TAS_adaptiveActivityFR_C 31 "SNA" ;
VAL_ 409 TAS_adaptiveActivityFL_R 31 "SNA" ;
VAL_ 409 TAS_adaptiveActivityFL_C 31 "SNA" ;
CM_ BO_ 410 "ESP32-DualCAN Model3_VEH. Not seen on this car in the logs.";
VAL_ 410 TAS_bodyAccelRR 255 "SNA" ;
VAL_ 410 TAS_bodyAccelRL 255 "SNA" ;
VAL_ 410 TAS_bodyAccelFR 255 "SNA" ;
VAL_ 410 TAS_bodyAccelFL 255 "SNA" ;
CM_ BO_ 443 "ESP32-DualCAN Model3_VEH. Not seen on this car in the logs.";
CM_ BO_ 454 "ESP32-DualCAN Model3_CH. Seen on this car: 6-byte frames; fit ok (bits covered 100%, mux 100%, ranges 100%).";
CM_ BO_ 455 "ESP32-DualCAN Model3_VEH. Not seen on this car in the logs.";
VAL_ 455 TASDBG_current_RR_R 31 "SNA" ;
VAL_ 455 TASDBG_current_RR_C 31 "SNA" ;
VAL_ 455 TASDBG_current_RL_R 31 "SNA" ;
VAL_ 455 TASDBG_current_RL_C 31 "SNA" ;
VAL_ 455 TASDBG_current_FR_R 31 "SNA" ;
VAL_ 455 TASDBG_current_FR_C 31 "SNA" ;
VAL_ 455 TASDBG_current_FL_R 31 "SNA" ;
VAL_ 455 TASDBG_current_FL_C 31 "SNA" ;
CM_ BO_ 456 "ESP32-DualCAN Model3_VEH. Not seen on this car in the logs.";
CM_ BO_ 469 "ESP32-DualCAN Model3_VEH. Not seen on this car in the logs.";
VAL_ 469 PMF_hvilSupplyState 0 "NOT_AVAILABLE" 1 "INACTIVE" 2 "ACTIVE" ;
VAL_ 469 PMF_axleSpeedQF 0 "NOT_QUALIFIED" 1 "QUALIFIED" ;
VAL_ 469 PMF_hvilStatus 0 "DISABLED" 1 "OPEN" 2 "CLOSED" 3 "SNA" ;
VAL_ 469 PMF_torqueCommand 4294963200 "SNA" ;
VAL_ 469 PMF_soptState 0 "INIT" 1 "PSTG_BRING_UP" 2 "ASC_TEST" 3 "CURRENT_TEST" 4 "TEST_PASSED" 5 "TEST_SKIPPED" 6 "TEST_FAILED" 7 "SNA" ;
CM_ BO_ 473 "ESP32-DualCAN Model3_VEH. Seen on this car: 3-byte frames; fit poor (bits covered 0%, mux 100%, ranges 100%).; 5 signals past the 3 bytes this car sends were left out";
CM_ BO_ 474 "ESP32-DualCAN Model3_VEH. Seen on this car: 8-byte frames; fit good (bits covered 100%, mux 100%, ranges 100%).";
CM_ BO_ 485 "ESP32-DualCAN Model3_VEH. Seen on this car: 8-byte frames; fit good (bits covered 100%, mux 100%, ranges 100%, checksum 100%).";
VAL_ 485 PM_hvilSystemStatus 0 "DISABLED" 1 "OPEN" 2 "CLOSED" 3 "SNA" ;
VAL_ 485 PM_autoparkState 0 "UNAVAILABLE" 1 "STANDBY" 2 "STARTED" 3 "ACTIVE" 4 "COMPLETE" 5 "PAUSED" 6 "ABORTED" 7 "RESUMED" 8 "UNPARK_COMPLETE" 9 "SELFPARK_STARTED" 15 "SNA" ;
VAL_ 485 PM_cruiseState 0 "UNAVAILABLE" 1 "STANDBY" 2 "ENABLED" 3 "STANDSTILL" 4 "OVERRIDE" 5 "FAULT" 6 "PRE_FAULT" 7 "PRE_CANCEL" ;
CM_ BO_ 504 "ESP32-DualCAN Model3_VEH. Seen on this car: 4-byte frames; fit poor (bits covered 0%, mux 100%, ranges 100%).";
VAL_ 504 VCLEFT_DBG_LM_SelfTest_Status 0 "IDLE" 1 "RX" ;
VAL_ 504 VCLEFT_DBG_USS_SelfTest_Status 0 "IDLE" 1 "RX" ;
VAL_ 504 VCLEFT_DBG_Eeprom_ST_Status 0 "IDLE" 1 "RX" ;
VAL_ 504 VCLEFT_DBG_Siren_ST_Status 0 "IDLE" 1 "RX" ;
VAL_ 504 VCLEFT_DBG_LM_Alarm_Status 0 "IDLE" 1 "RX" ;
VAL_ 504 VCLEFT_DBG_USS_Alarm_Status 0 "IDLE" 1 "RX" ;
VAL_ 504 VCLEFT_DBG_Veh_Settings_Status 0 "IDLE" 1 "RX" ;
VAL_ 504 VCLEFT_DBG_SelfTest_Status 0 "IDLE" 1 "RX" ;
VAL_ 504 VCLEFT_DBG_Suspensions_Status 0 "IDLE" 1 "RX" ;
VAL_ 504 VCLEFT_DBG_Window_Status 0 "IDLE" 1 "RX" ;
VAL_ 504 VCLEFT_DBG_Heater_Status 0 "IDLE" 1 "RX" ;
VAL_ 504 VCLEFT_DBG_Air_Cond_Status 0 "IDLE" 1 "RX" ;
VAL_ 504 VCLEFT_DBG_System_Status 0 "IDLE" 1 "RX" ;
CM_ BO_ 505 "ESP32-DualCAN Model3_VEH. Seen on this car: 8-byte frames; fit good (bits covered 100%, mux 100%, ranges 100%).";
VAL_ 505 VCSEC_chargeportRequestReason 0 "NONE" 1 "RKE" 2 "UHF" ;
VAL_ 505 VCSEC_snapshotRequested 0 "NONE" 1 "HANDLE_PULL_WITHOUT_AUTH" 2 "AUTHED_WITHOUT_HANDLE_PULL" 3 "AUTO_PRESENT_DOOR_CLOSE_TIMEOUT" 4 "AUTO_PRESENT_DOOR_CLOSE_WITHOUT_PEDESTRIAN_DETECTED" 5 "INTRUSION_DETECTED" 6 "TRIGGER_6" 7 "TRIGGER_7" 8 "TRIGGER_8" 9 "TRIGGER_9" 10 "TRIGGER_10" 11 "TRIGGER_11" 12 "TRIGGER_12" 13 "TRIGGER_13" 14 "TRIGGER_14" 15 "TRIGGER_15" ;
VAL_ 505 VCSEC_closeAllStatus 0 "NOT_AVAILABLE" 1 "AVAILABLE" 2 "CANCELABLE" ;
VAL_ 505 VCSEC_rearTrunkRequestReason 0 "REASON_NONE" 1 "REASON_RKE" 2 "REASON_CLOSE_ALL" 3 "REASON_AUTO_PRESENT" 4 "KEYFOB_UNLOCK_OPEN" 5 "UI_STOP_ALL" ;
VAL_ 505 VCSEC_rearRightRequestReason 0 "REASON_NONE" 1 "REASON_RKE" 2 "REASON_CLOSE_ALL" 3 "REASON_AUTO_PRESENT" 4 "KEYFOB_UNLOCK_OPEN" 5 "UI_STOP_ALL" ;
VAL_ 505 VCSEC_rearLeftRequestReason 0 "REASON_NONE" 1 "REASON_RKE" 2 "REASON_CLOSE_ALL" 3 "REASON_AUTO_PRESENT" 4 "KEYFOB_UNLOCK_OPEN" 5 "UI_STOP_ALL" ;
VAL_ 505 VCSEC_frontRightRequestReason 0 "REASON_NONE" 1 "REASON_RKE" 2 "REASON_CLOSE_ALL" 3 "REASON_AUTO_PRESENT" 4 "KEYFOB_UNLOCK_OPEN" 5 "UI_STOP_ALL" ;
VAL_ 505 VCSEC_frontLeftRequestReason 0 "REASON_NONE" 1 "REASON_RKE" 2 "REASON_CLOSE_ALL" 3 "REASON_AUTO_PRESENT" 4 "KEYFOB_UNLOCK_OPEN" 5 "UI_STOP_ALL" ;
VAL_ 505 VCSEC_rearTrunkClosureRequest 0 "NONE" 1 "MOVE" 2 "STOP" 3 "OPEN" 4 "QUICK_OPEN" 5 "OPEN_REDUCED" 6 "CLOSE" ;
VAL_ 505 VCSEC_rearRightClosureRequest 0 "NONE" 1 "MOVE" 2 "STOP" 3 "OPEN" 4 "QUICK_OPEN" 5 "OPEN_REDUCED" 6 "CLOSE" ;
VAL_ 505 VCSEC_rearLeftClosureRequest 0 "NONE" 1 "MOVE" 2 "STOP" 3 "OPEN" 4 "QUICK_OPEN" 5 "OPEN_REDUCED" 6 "CLOSE" ;
VAL_ 505 VCSEC_frontRightClosureRequest 0 "NONE" 1 "MOVE" 2 "STOP" 3 "OPEN" 4 "QUICK_OPEN" 5 "OPEN_REDUCED" 6 "CLOSE" ;
VAL_ 505 VCSEC_frontLeftClosureRequest 0 "NONE" 1 "MOVE" 2 "STOP" 3 "OPEN" 4 "QUICK_OPEN" 5 "OPEN_REDUCED" 6 "CLOSE" ;
VAL_ 505 VCSEC_chargePortRequest 0 "NONE" 1 "OPEN" 2 "CLOSE" 3 "SNA" ;
CM_ BO_ 506 "ESP32-DualCAN Model3_VEH. Seen on this car: 3-byte frames; fit poor (bits covered 0%, mux 100%, ranges 100%).";
CM_ BO_ 507 "ESP32-DualCAN Model3_VEH. Seen on this car: 8-byte frames; fit weak (bits covered 0%, mux 100%, ranges 100%).";
VAL_ 507 VCLEFT_TLCState_Reverse 0 "OFF_WITHOUT_LOAD" 1 "OFF_WITH_LOAD" 2 "ON_WITHOUT_LOAD" 3 "ON_WITH_LOAD" 4 "FAULT" 5 "SNA" ;
VAL_ 507 VCLEFT_TLCState_Fog 0 "OFF_WITHOUT_LOAD" 1 "OFF_WITH_LOAD" 2 "ON_WITHOUT_LOAD" 3 "ON_WITH_LOAD" 4 "FAULT" 5 "SNA" ;
VAL_ 507 VCLEFT_TLCState_Stop 0 "OFF_WITHOUT_LOAD" 1 "OFF_WITH_LOAD" 2 "ON_WITHOUT_LOAD" 3 "ON_WITH_LOAD" 4 "FAULT" 5 "SNA" ;
VAL_ 507 VCLEFT_TLCState_Tail 0 "OFF_WITHOUT_LOAD" 1 "OFF_WITH_LOAD" 2 "ON_WITHOUT_LOAD" 3 "ON_WITH_LOAD" 4 "FAULT" 5 "SNA" ;
VAL_ 507 VCLEFT_TLCState_RightTurn 0 "OFF_WITHOUT_LOAD" 1 "OFF_WITH_LOAD" 2 "ON_WITHOUT_LOAD" 3 "ON_WITH_LOAD" 4 "FAULT" 5 "SNA" ;
VAL_ 507 VCLEFT_TLCState_LeftTurn 0 "OFF_WITHOUT_LOAD" 1 "OFF_WITH_LOAD" 2 "ON_WITHOUT_LOAD" 3 "ON_WITH_LOAD" 4 "FAULT" 5 "SNA" ;
VAL_ 507 VCLEFT_TLCRightTurnVoltage 255 "SNA" ;
VAL_ 507 VCLEFT_TLCLeftTurnVoltage 255 "SNA" ;
VAL_ 507 VCLEFT_TLCTemperature 4294967168 "SNA" ;
VAL_ 507 VCLEFT_TLCStatusIndex 0 "0" 1 "1" 2 "INVALID" ;
CM_ BO_ 508 "ESP32-DualCAN Model3_VEH. Not seen on this car in the logs.";
VAL_ 508 APP_suspensionLevelRequest 0 "NONE" 1 "VERY_LOW_LEVEL" 2 "LOW_LEVEL" 3 "STANDARD_LEVEL" 4 "HIGH_LEVEL_TEMPORARY" 5 "VERY_HIGH_LEVEL_TEMPORARY" 6 "HIGH_LEVEL_PERSIST" 7 "VERY_HIGH_LEVEL_PERSIST" ;
CM_ BO_ 519 "ESP32-DualCAN Model3_VEH. Not seen on this car in the logs.";
CM_ BO_ 521 "ESP32-DualCAN Model3_CH. Seen on this car: 8-byte frames; fit ok (bits covered 100%, mux 0%, ranges 100%, checksum 100%).";
VAL_ 521 DAS_pedalControl_accelPedalPos 255 "SNA" ;
VAL_ 521 DAS_gearRequest 0 "IDLE_SNA" 1 "PARK" 2 "REVERSE" 3 "NEUTRAL" 4 "DRIVE" ;
CM_ BO_ 524 "ESP32-DualCAN Model3_VEH. Seen on this car: 8-byte frames; fit good (bits covered 100%, mux 100%, ranges 100%).";
VAL_ 524 VCRIGHT_hvacPerfTestState 0 "STOPPED" 1 "WAITING" 2 "BLOWING" ;
VAL_ 524 VCRIGHT_tempAmbientRaw 0 "SNA" ;
VAL_ 524 VCRIGHT_tempEvaporatorTarget 255 "SNA" ;
VAL_ 524 VCRIGHT_tempEvaporator 2047 "SNA" ;
CM_ BO_ 538 "ESP32-DualCAN Model3_VEH. Not seen on this car in the logs.";
VAL_ 538 TAS_launchModeState 0 "BLOCKED" 1 "IDLE" 2 "LOWER_SUSPENSION" 3 "READY" 4 "RAISE_SUSPENSION" ;
VAL_ 538 TAS_adaptiveRideModeOverride 0 "COMFORT" 1 "AUTO" 2 "SPORT" 3 "SNA" ;
CM_ BO_ 546 "ESP32-DualCAN Model3_VEH. Not seen on this car in the logs.";
CM_ BO_ 549 "ESP32-DualCAN Model3_VEH. Seen on this car: 4-byte frames; fit ok (bits covered 100%, mux 100%, ranges 100%).";
VAL_ 549 VCRIGHT_icrLVState 0 "OFF" 1 "ON" 2 "GOING_DOWN" 3 "FAULT" ;
VAL_ 549 VCRIGHT_parkLVState 0 "OFF" 1 "ON" 2 "GOING_DOWN" 3 "FAULT" ;
VAL_ 549 VCRIGHT_vehiclePowerStateDBG 0 "INIT" 1 "LOW_POWER_AWAKE" 2 "CONDITIONING" 3 "ACCESSORY" 4 "ACCESSORY_PLUS" 5 "DRIVE" 6 "OTA" 7 "WAIT_FOR_HIGH_POWER" 8 "TURN_ON_LV" 9 "SYSTEM_CHECKS" 10 "LV_ON" 11 "JUMP_START" 12 "LV_SHUTDOWN" 13 "GO_QUIET" 14 "SLEEP_SHUTDOWN" 15 "LOW_POWER_STANDBY" 16 "RESET" ;
VAL_ 549 VCRIGHT_eFuseLockoutStatus 0 "IDLE" 1 "PENDING" 2 "ACTIVE" ;
VAL_ 549 VCRIGHT_lumbarLVState 0 "OFF" 1 "ON" 2 "GOING_DOWN" 3 "FAULT" ;
VAL_ 549 VCRIGHT_rcmLVState 0 "OFF" 1 "ON" 2 "GOING_DOWN" 3 "FAULT" ;
VAL_ 549 VCRIGHT_hvcLVState 0 "OFF" 1 "ON" 2 "GOING_DOWN" 3 "FAULT" ;
VAL_ 549 VCRIGHT_tunerLVState 0 "OFF" 1 "ON" 2 "GOING_DOWN" 3 "FAULT" ;
VAL_ 549 VCRIGHT_premAudioLVState 0 "OFF" 1 "ON" 2 "GOING_DOWN" 3 "FAULT" ;
VAL_ 549 VCRIGHT_ocsLVState 0 "OFF" 1 "ON" 2 "GOING_DOWN" 3 "FAULT" ;
VAL_ 549 VCRIGHT_ptcLVState 0 "OFF" 1 "ON" 2 "GOING_DOWN" 3 "FAULT" ;
CM_ BO_ 551 "ESP32-DualCAN Model3_CH. Seen on this car: 8-byte frames; fit good (bits covered 100%, mux 100%, ranges 100%).";
CM_ BO_ 554 "ESP32-DualCAN Model3_VEH. Seen on this car: 4-byte frames; fit ok (bits covered 100%, mux 100%, ranges 100%).";
VAL_ 554 HVP_dcLinkVoltageFiltered 4294966746 "SNA" ;
VAL_ 554 HVP_pcsControlRequest 0 "SHUTDOWN" 1 "SUPPORT" 2 "PRECHARGE" 3 "DISCHARGE" ;
CM_ BO_ 555 "ESP32-DualCAN Model3_VEH. Seen on this car: 8-byte frames; fit good (bits covered 100%, mux 100%, ranges 100%).";
CM_ BO_ 557 "ESP32-DualCAN Model3_VEH. Not seen on this car in the logs.";
CM_ BO_ 561 "ESP32-DualCAN Model3_CH. Seen on this car: 8-byte frames; fit good (bits covered 100%, mux 100%, ranges 100%).";
CM_ BO_ 562 "ESP32-DualCAN Model3_VEH. Seen on this car: 8-byte frames; fit good (bits covered 100%, mux 100%, ranges 100%).";
CM_ BO_ 564 "ESP32-DualCAN Model3_VEH. Seen on this car: 8-byte frames; fit ok (bits covered 100%, mux 100%, ranges 100%, checksum 0%).";
VAL_ 564 DCDC_type 0 "US_TESLA" 1 "EURO_IEC" 2 "GB" 3 "IEC_CCS" ;
CM_ BO_ 565 "ESP32-DualCAN Model3_CH. Seen on this car: 4-byte frames; fit ok (bits covered 100%, mux 100%, ranges 100%).";
CM_ BO_ 570 "ESP32-DualCAN Model3_VEH. Seen on this car: 8-byte frames; fit good (bits covered 100%, mux 87%, ranges 100%).";
VAL_ 570 VCSEC_TPMSSensorMLXAppCRC0 0 "TPMS_CRC_SNA" ;
VAL_ 570 VCSEC_TPMSSensorMLXAppCRC1 0 "TPMS_CRC_SNA" ;
VAL_ 570 VCSEC_TPMSSensorMLXAppCRC2 0 "TPMS_CRC_SNA" ;
VAL_ 570 VCSEC_TPMSSensorMLXAppCRC3 0 "TPMS_CRC_SNA" ;
VAL_ 570 VCSEC_TPMSSensorTIAppCRC0 0 "TPMS_CRC_SNA" ;
VAL_ 570 VCSEC_TPMSSensorTIAppCRC1 0 "TPMS_CRC_SNA" ;
VAL_ 570 VCSEC_TPMSSensorTIAppCRC2 0 "TPMS_CRC_SNA" ;
VAL_ 570 VCSEC_TPMSSensorTIAppCRC3 0 "TPMS_CRC_SNA" ;
VAL_ 570 VCSEC_TPMSSystemState 0 "IDLE" 1 "ACTIVE" ;
VAL_ 570 VCSEC_TPMSStatusIndex 0 "MAC_ADDRESS_SENSOR_0" 1 "MAC_ADDRESS_SENSOR_1" 2 "MAC_ADDRESS_SENSOR_2" 3 "MAC_ADDRESS_SENSOR_3" 4 "CONN_METRICS_SENSOR_0" 5 "CONN_METRICS_SENSOR_1" 6 "CONN_METRICS_SENSOR_2" 7 "CONN_METRICS_SENSOR_3" 8 "CRC_SENSOR_0" 9 "CRC_SENSOR_1" 10 "CRC_SENSOR_2" 11 "CRC_SENSOR_3" 12 "CPU_TIME_SENSOR_0" 13 "CPU_TIME_SENSOR_1" 14 "CPU_TIME_SENSOR_2" 15 "CPU_TIME_SENSOR_3" 16 "SLEEP_STATS_SENSOR_0" 17 "SLEEP_STATS_SENSOR_1" 18 "SLEEP_STATS_SENSOR_2" 19 "SLEEP_STATS_SENSOR_3" 20 "MAC_ADDRESS_SENSOR_4" 21 "MAC_ADDRESS_SENSOR_5" 22 "MAC_ADDRESS_SENSOR_6" 23 "MAC_ADDRESS_SENSOR_7" 24 "MAC_ADDRESS_SENSOR_8" 25 "MAC_ADDRESS_SENSOR_9" 26 "CONN_METRICS_SENSOR_4" 27 "CONN_METRICS_SENSOR_5" 28 "CONN_METRICS_SENSOR_6" 29 "CONN_METRICS_SENSOR_7" 30 "CONN_METRICS_SENSOR_8" 31 "CONN_METRICS_SENSOR_9" 32 "CRC_SENSOR_4" 33 "CRC_SENSOR_5" 34 "CRC_SENSOR_6" 35 "CRC_SENSOR_7" 36 "CRC_SENSOR_8" 37 "CRC_SENSOR_9" 38 "CPU_TIME_SENSOR_4" 39 "CPU_TIME_SENSOR_5" 40 "CPU_TIME_SENSOR_6" 41 "CPU_TIME_SENSOR_7" 42 "CPU_TIME_SENSOR_8" 43 "CPU_TIME_SENSOR_9" 44 "SLEEP_STATS_SENSOR_4" 45 "SLEEP_STATS_SENSOR_5" 46 "SLEEP_STATS_SENSOR_6" 47 "SLEEP_STATS_SENSOR_7" 48 "SLEEP_STATS_SENSOR_8" 49 "SLEEP_STATS_SENSOR_9" ;
CM_ BO_ 574 "ESP32-DualCAN Model3_VEH. Not seen on this car in the logs.";
CM_ BO_ 576 "ESP32-DualCAN Model3_CH. Seen on this car: 2-byte frames; fit ok (bits covered 100%, mux 100%, ranges 100%, checksum 100%).";
CM_ BO_ 578 "ESP32-DualCAN Model3_VEH. Seen on this car: 4-byte frames; fit ok (bits covered 100%, mux 100%, ranges 100%).";
VAL_ 578 VCLEFT_vehiclePowerStateDBG 0 "INIT" 1 "LOW_POWER_AWAKE" 2 "CONDITIONING" 3 "ACCESSORY" 4 "ACCESSORY_PLUS" 5 "DRIVE" 6 "OTA" 7 "WAIT_FOR_HIGH_POWER" 8 "TURN_ON_LV" 9 "SYSTEM_CHECKS" 10 "LV_ON" 11 "JUMP_START" 12 "LV_SHUTDOWN" 13 "GO_QUIET" 14 "SLEEP_SHUTDOWN" 15 "LOW_POWER_STANDBY" 16 "RESET" ;
VAL_ 578 VCLEFT_lumbarLVState 0 "OFF" 1 "ON" 2 "GOING_DOWN" 3 "FAULT" ;
VAL_ 578 VCLEFT_rcmLVState 0 "OFF" 1 "ON" 2 "GOING_DOWN" 3 "FAULT" ;
CM_ BO_ 579 "ESP32-DualCAN Model3_VEH. Seen on this car: 8-byte frames; fit good (bits covered 100%, mux 100%, ranges 100%).";
VAL_ 579 VCRIGHT_hvacModelInitStatus 0 "NOT_INIT_WAIT_FOR_SENSORS" 1 "NOT_INIT_WAIT_FOR_GTW" 2 "INIT_FROM_SENSORS" 3 "INIT_FROM_SENSORS_PREDICTION_ERROR" 4 "INIT_FORWARD_CALC" 5 "INIT_WAITING_FOR_SENSORS" ;
VAL_ 579 VCRIGHT_hvacDuctTargetRight 255 "SNA" ;
VAL_ 579 VCRIGHT_hvacSecondRowState 0 "AUTO" 1 "OFF" 2 "LOW" 3 "MED" 4 "HIGH" ;
VAL_ 579 VCRIGHT_tempDuctRightLower 255 "SNA" ;
VAL_ 579 VCRIGHT_hvacVentStatus 0 "BOTH" 1 "LEFT" 2 "RIGHT" ;
VAL_ 579 VCRIGHT_hvacPowerState 0 "OFF" 1 "ON" 2 "PRECONDITION" 3 "OVERHEAT_PROTECT_FANONLY" 4 "OVERHEAT_PROTECT" ;
VAL_ 579 VCRIGHT_hvacACRunning 0 "OFF" 1 "ON" ;
VAL_ 579 VCRIGHT_hvacDuctTargetLeft 255 "SNA" ;
VAL_ 579 VCRIGHT_hvacRecirc 0 "AUTO" 1 "RECIRC" 2 "FRESH" ;
VAL_ 579 VCRIGHT_tempDuctLeftLower 255 "SNA" ;
VAL_ 579 VCRIGHT_hvacBlowerSegment 0 "OFF" 1 "1" 2 "2" 3 "3" 4 "4" 5 "5" 6 "6" 7 "7" 8 "8" 9 "9" 10 "10" 11 "11" ;
VAL_ 579 VCRIGHT_hvacAirDistributionMode 0 "NONE" 1 "FLOOR" 2 "PANEL" 3 "PANEL_FLOOR" 4 "DEFROST" 5 "DEFROST_FLOOR" 6 "DEFROST_PANEL" 7 "DEFROST_PANEL_FLOOR" ;
VAL_ 579 VCRIGHT_solarLoadOnVehicle 255 "SNA" ;
VAL_ 579 VCRIGHT_hvacAirflowReason 0 "HVAC_OFF" 1 "MANUAL_FAN_SPEED" 2 "UI_SHORTCUT" 3 "CABIN_TEMPERATURE_CONTROL" 4 "MINIMUM_AUTO_AIRFLOW" 5 "STRATIFICATION_GLASS_ROOF" 6 "STRATIFICATION_INTERIOR_SURFACES" 7 "OCCUPANT_CONVECTION_REQUIREMENT" 8 "COLD_DUCT_LOCKOUT" 9 "CABIN_PURGE" 10 "CABIN_OVERHEAT_PROTECT" 11 "SCREEN_PROTECTION" 12 "EVAP_DRYING" 13 "EVAP_OIL_PURGE" 14 "BIOWEAPON_DEFENSE" 15 "NONE" ;
VAL_ 579 VCRIGHT_tempDuctRight 255 "SNA" ;
VAL_ 579 VCRIGHT_autoDefogStatus 0 "NONE" 1 "DEFOG" 2 "INTERMEDIATE_DEFOG" ;
VAL_ 579 VCRIGHT_hvacEvapInletTempEstimate 1023 "SNA" ;
VAL_ 579 VCRIGHT_hvacFrontLeftSeatHeatStatus 0 "OFF" 1 "LEVEL1" 2 "LEVEL2" 3 "LEVEL3" ;
VAL_ 579 VCRIGHT_tempDuctLeft 255 "SNA" ;
VAL_ 579 VCRIGHT_tempDuctLeftUpper 255 "SNA" ;
VAL_ 579 VCRIGHT_tempDuctRightUpper 255 "SNA" ;
VAL_ 579 VCRIGHT_hvacSeatFrontLeftTempTarget 0 "OFF" ;
VAL_ 579 VCRIGHT_hvacFrontRightSeatHeatStatus 0 "OFF" 1 "LEVEL1" 2 "LEVEL2" 3 "LEVEL3" ;
VAL_ 579 VCRIGHT_hvacStatusIndex 0 "STATUS_UI" 1 "STATUS_VCFRONT" 2 "TARGETS_AND_MASS_FLOW" 3 "TEMPERATURES" 4 "TEMPERATURES_2" 5 "SEAT_CLIMATE" 6 "END" ;
CM_ BO_ 608 "Unknown 10 Hz: bit 0 flag, counter at 52; byte 7 = byte sum + 0x62.";
CM_ BO_ 611 "ESP32-DualCAN Model3_VEH. Seen on this car: 8-byte frames; fit good (bits covered 100%, mux 100%, ranges 100%).";
VAL_ 611 VCRIGHT_hvacIntakeActuatorState 0 "BRAKING" 1 "RUNNING" 2 "COASTING" ;
VAL_ 611 VCRIGHT_hvacLowerModeActState 0 "BRAKING" 1 "RUNNING" 2 "COASTING" ;
VAL_ 611 VCRIGHT_hvacUpperModeActState 0 "BRAKING" 1 "RUNNING" 2 "COASTING" ;
VAL_ 611 VCRIGHT_hvacRHVaneActuatorState 0 "BRAKING" 1 "RUNNING" 2 "COASTING" ;
VAL_ 611 VCRIGHT_hvacLHVaneActuatorState 0 "BRAKING" 1 "RUNNING" 2 "COASTING" ;
VAL_ 611 VCRIGHT_hvacRHBleedActuatorState 0 "BRAKING" 1 "RUNNING" 2 "COASTING" ;
VAL_ 611 VCRIGHT_hvacLHBleedActuatorState 0 "BRAKING" 1 "RUNNING" 2 "COASTING" ;
VAL_ 611 VCRIGHT_logging10HzIndex 0 "HVAC_ACTUATOR_TARGETS_1" 1 "HVAC_ACTUATOR_TARGETS_2" 2 "HVAC_ACTUATOR_POSITIONS_1" 3 "HVAC_ACTUATOR_POSITIONS_2" 4 "END" ;
CM_ BO_ 622 "ESP32-DualCAN Model3_CH. Not seen on this car in the logs.";
VAL_ 622 PARK_obj_type 0 "US_TESLA" 1 "EURO_IEC" 2 "GB" 3 "IEC_CCS" ;
CM_ BO_ 630 "ESP32-DualCAN Model3_VEH. Seen on this car: 8-byte frames; fit good (bits covered 100%, mux 100%, ranges 100%).";
CM_ BO_ 633 "ESP32-DualCAN Model3_VEH. Seen on this car: 8-byte frames; fit ok (bits covered 100%, mux 100%, ranges 100%, checksum 0%).";
VAL_ 633 DIR_gateDriveSupplyState 0 "DOWN" 1 "RISING" 2 "UP" 3 "FALLING" ;
VAL_ 633 DIR_gateDriveState 0 "INIT" 1 "SELFTEST" 2 "CONFIGURING" 3 "CONFIGURED" 4 "NOT_CONFIGURED" ;
VAL_ 633 DIR_powerStageSafeState 0 "NONE" 1 "ALL_OFF" 2 "3PS_HIGH" 3 "3PS_LOW" ;
VAL_ 633 DIR_vBatQF 0 "NOT_QUALIFIED" 1 "QUALIFIED" ;
VAL_ 633 DIR_hvilSupplyState 0 "NOT_AVAILABLE" 1 "INACTIVE" 2 "ACTIVE" ;
VAL_ 633 DIR_hvilStatus 0 "DISABLED" 1 "OPEN" 2 "CLOSED" 3 "SNA" ;
CM_ BO_ 634 "ESP32-DualCAN Model3_VEH. Not seen on this car in the logs.";
VAL_ 634 DIF_gateDriveSupplyState 0 "DOWN" 1 "RISING" 2 "UP" 3 "FALLING" ;
VAL_ 634 DIF_gateDriveState 0 "INIT" 1 "SELFTEST" 2 "CONFIGURING" 3 "CONFIGURED" 4 "NOT_CONFIGURED" ;
VAL_ 634 DIF_powerStageSafeState 0 "NONE" 1 "ALL_OFF" 2 "3PS_HIGH" 3 "3PS_LOW" ;
VAL_ 634 DIF_vBatQF 0 "NOT_QUALIFIED" 1 "QUALIFIED" ;
VAL_ 634 DIF_hvilSupplyState 0 "NOT_AVAILABLE" 1 "INACTIVE" 2 "ACTIVE" ;
VAL_ 634 DIF_hvilStatus 0 "DISABLED" 1 "OPEN" 2 "CLOSED" 3 "SNA" ;
CM_ BO_ 643 "ESP32-DualCAN Model3_VEH. Seen on this car: 6-byte frames; fit poor (bits covered 0%, mux 100%, ranges 100%).";
CM_ BO_ 649 "ESP32-DualCAN Model3_VEH. Seen on this car: 8-byte frames; fit good (bits covered 100%, mux 100%, ranges 100%).";
VAL_ 649 VCLEFT_hvacBlowerITerm 127 "SNA" ;
VAL_ 649 VCLEFT_hvacBlowerCBCCtrlState 0 "ERROR" 1 "IDLE" 2 "OFFLINE" 3 "ONLINE" 4 "COUNT" ;
VAL_ 649 VCLEFT_hvacBlowerCBCEstState 0 "ERROR" 1 "IDLE" 2 "ROVERL" 3 "RS" 4 "RAMPUP" 5 "IDRATED" 6 "RATEDFLUX_OL" 7 "RATEDFLUX" 8 "RAMPDOWN" 9 "LOCKROTOR" 10 "INDUCTANCE_EST" 11 "ROTOR_RESISTANCE" 12 "MOTOR_IDENTIFIED" 13 "ONLINE" 14 "COUNT" ;
VAL_ 649 VCLEFT_hvacBlower_IO_CBC_Status 0 "IDLE" 1 "RX" ;
VAL_ 649 VCLEFT_hvacBlowerIPhase2 255 "SNA" ;
VAL_ 649 VCLEFT_hvacBlowerIPhase1 255 "SNA" ;
VAL_ 649 VCLEFT_hvacBlowerIPhase0 255 "SNA" ;
VAL_ 649 VCLEFT_hvacBlowerRs 255 "SNA" ;
VAL_ 649 VCLEFT_logging10HzIndex 0 "Mux0" 1 "Mux1" ;
CM_ BO_ 654 "Alive message: checksum + counter only; no data seen (route 494, 2026-11-19). Byte sum + 0x90; bytes 2-7 constant.";
CM_ BO_ 655 "Alive message: checksum + counter only; no data seen (route 494, 2026-11-19). Byte sum + 0x91; bytes 2-7 constant.";
CM_ BO_ 660 "ESP32-DualCAN Model3_VEH. Seen on this car: 8-byte frames; fit good (bits covered 100%, mux 100%, ranges 100%).";
VAL_ 660 UI_windowRequest 0 "IDLE" 1 "GOTO_PERCENT" 2 "GOTO_VENT" 3 "GOTO_CLOSED" 5 "GOTO_CLOSED_CARWASH" 6 "GOTO_PERCENT_RELATIVE" ;
VAL_ 660 UI_packTempLoggingRequest 0 "FALSE" 1 "TRUE" ;
VAL_ 660 UI_lightFlashRequest 0 "INACTIVE" 1 "HOMELINK" 2 "MOBILE_APP" 3 "SENTRY" ;
CM_ BO_ 661 "ESP32-DualCAN Model3_VEH. Seen on this car: 8-byte frames; fit good (bits covered 100%, mux 100%, ranges 100%).";
CM_ BO_ 663 "ESP32-DualCAN Model3_VEH. Not seen on this car in the logs.";
VAL_ 663 UI_suspensionLevelRequest 0 "NONE" 1 "VERY_LOW_LEVEL" 2 "LOW_LEVEL" 3 "STANDARD_LEVEL" 4 "HIGH_LEVEL_TEMPORARY" 5 "VERY_HIGH_LEVEL_TEMPORARY" 6 "HIGH_LEVEL_PERSIST" 7 "VERY_HIGH_LEVEL_PERSIST" ;
VAL_ 663 UI_roadRoughnessStart 31 "SNA" ;
VAL_ 663 UI_roadRoughnessLookahead 127 "SNA" ;
VAL_ 663 UI_jackModeToggleRequest 0 "NONE" 1 "ACTIVE" ;
VAL_ 663 UI_geofenceLevelingRequest 0 "NONE" 1 "HIGH_TEMPORARY" 2 "VERY_HIGH_TEMPORARY" 3 "HIGH_PERSIST" 4 "VERY_HIGH_PERSIST" 5 "SNA" ;
VAL_ 663 UI_suspensionLoweringRequest 0 "NEVER" 1 "ALWAYS" 2 "AUTO" 3 "SNA" ;
VAL_ 663 UI_adaptiveRideRequest 0 "COMFORT" 1 "AUTO" 2 "SPORT" 3 "ADVANCED" ;
CM_ BO_ 667 "ESP32-DualCAN Model3_VEH. Seen on this car: 5-byte frames; fit weak (bits covered 69%, mux 100%, ranges 100%).";
CM_ BO_ 670 "ESP32-DualCAN Model3_VEH. Seen on this car: 8-byte frames; fit good (bits covered 100%, mux 100%, ranges 100%, checksum 100%).";
CM_ BO_ 673 "ESP32-DualCAN Model3_VEH. Seen on this car: 6-byte frames; fit ok (bits covered 100%, mux 100%, ranges 100%).";
CM_ BO_ 674 "ESP32-DualCAN Model3_VEH. Seen on this car: 7-byte frames; fit poor (bits covered 0%, mux 100%, ranges 100%).";
CM_ BO_ 675 "ESP32-DualCAN Model3_VEH. Seen on this car: 8-byte frames; fit good (bits covered 100%, mux 100%, ranges 100%).";
CM_ BO_ 678 "ESP32-DualCAN Model3_VEH. Seen on this car: 8-byte frames; fit good (bits covered 100%, mux 100%, ranges 100%).";
CM_ BO_ 682 "ESP32-DualCAN Model3_VEH. Seen on this car: 3-byte frames; fit ok (bits covered 100%, mux 100%, ranges 100%, checksum 100%).";
CM_ BO_ 693 "ESP32-DualCAN Model3_CH. Not seen on this car in the logs.";
CM_ BO_ 695 "ESP32-DualCAN Model3_CH. Not seen on this car in the logs.";
CM_ BO_ 699 "ESP32-DualCAN Model3_CH. Not seen on this car in the logs.";
CM_ BO_ 793 "ESP32-DualCAN Model3_VEH. Seen on this car: 8-byte frames; fit good (bits covered 100%, mux 100%, ranges 100%).";
VAL_ 793 VCSEC_infoAssemblyId 1 "ASSEMBLY1" 255 "ASSEMBLY_SNA" ;
VAL_ 793 VCSEC_infoBuildType 0 "UNKNOWN_BUILD" 1 "PLATFORM_BUILD" 2 "LOCAL_BUILD" 3 "TRACEABLE_CI_BUILD" 4 "MFG_BUILD" ;
VAL_ 793 VCSEC_infoIndex 0 "DEPRECATED_0" 1 "DEPRECATED_1" 2 "DEPRECATED_2" 3 "DEPRECATED_3" 4 "DEPRECATED_4" 5 "DEPRECATED_5" 6 "DEPRECATED_6" 7 "DEPRECATED_7" 8 "DEPRECATED_8" 9 "DEPRECATED_9" 10 "BUILD_HWID_COMPONENTID" 11 "PCBAID_ASSYID_USAGEID" 13 "APP_CRC" 14 "BOOTLOADER_SVN" 15 "BOOTLOADER_CRC" 16 "SUBCOMPONENT1" 17 "APP_GITHASH" 18 "BOOTLOADER_GITHASH" 19 "VERSION_DEPRECATED" 20 "UDS_PROTOCOL_BOOTCRC" 23 "SUBCOMPONENT2" 24 "SUBCOMPONENT3" 31 "SUBCOMPONENT4" 32 "SUBCOMPONENT5" 33 "SUBCOMPONENT6" 34 "SUBCOMPONENT7" 35 "SUBCOMPONENT8" 36 "SUBCOMPONENT9" 37 "SUBCOMPONENT10" 38 "SUBCOMPONENT11" 39 "SUBCOMPONENT12" 40 "SUBCOMPONENT13" 41 "SUBCOMPONENT14" 255 "END" ;
CM_ BO_ 794 "ESP32-DualCAN Model3_VEH. Seen on this car: 8-byte frames; fit good (bits covered 100%, mux 100%, ranges 100%, checksum 100%).";
VAL_ 794 VCRIGHT_occupantClassificationQF 0 "FAULTED" 1 "NOT_FAULTED" ;
VAL_ 794 VCRIGHT_occupantClassification 0 "EMPTY" 1 "INHIBIT" 2 "SMALL" 3 "LARGE" 4 "INIT" 5 "NOT_CONFIGURED" 7 "SNA" ;
VAL_ 794 VCRIGHT_seatTrackPosition 0 "FORWARD" 1 "REARWARD" 2 "NOT_CONFIGURED" 3 "FAULTED" 7 "SNA" ;
VAL_ 794 VCRIGHT_3RowRightOccupancyStatus 0 "UNOCCUPIED" 1 "OCCUPIED" 2 "OCCUPANCY_FAULTED" 3 "OCCUPANCY_SNA" ;
VAL_ 794 VCRIGHT_3RowLeftOccupancyStatus 0 "UNOCCUPIED" 1 "OCCUPIED" 2 "OCCUPANCY_FAULTED" 3 "OCCUPANCY_SNA" ;
VAL_ 794 VCRIGHT_3RowRightBuckleStatus 0 "UNLATCHED" 1 "LATCHED" 2 "FAULTED" 3 "SNA" ;
VAL_ 794 VCRIGHT_3RowLeftBuckleStatus 0 "UNLATCHED" 1 "LATCHED" 2 "FAULTED" 3 "SNA" ;
VAL_ 794 VCRIGHT_rearRightOccupancyStatus 0 "UNOCCUPIED" 1 "OCCUPIED" 2 "OCCUPANCY_FAULTED" 3 "OCCUPANCY_SNA" ;
VAL_ 794 VCRIGHT_rearRightBuckleStatus 0 "UNLATCHED" 1 "LATCHED" 2 "FAULTED" 3 "SNA" ;
VAL_ 794 VCRIGHT_rearCenterBuckleStatus 0 "UNLATCHED" 1 "LATCHED" 2 "FAULTED" 3 "SNA" ;
VAL_ 794 VCRIGHT_frontBuckleStatus 0 "UNLATCHED" 1 "LATCHED" 2 "FAULTED" 3 "SNA" ;
VAL_ 794 VCRIGHT_frontOccupancyStatus 0 "UNOCCUPIED" 1 "OCCUPIED" 2 "OCCUPANCY_FAULTED" 3 "NOT_CONFIGURED" 7 "OCCUPANCY_SNA" ;
CM_ BO_ 857 "ESP32-DualCAN Model3_VEH. Seen on this car: 8-byte frames; fit good (bits covered 100%, mux 100%, ranges 100%).";
VAL_ 857 VCSEC_Device0Formfactor 0 "UNKNOWN" 1 "NFC_CARD" 2 "3_BUTTON_BLE_CAR_KEYFOB" 3 "BLE_DEVICE" 4 "NFC_DEVICE" 5 "BLE_AND_NFC_DEVICE" 6 "IOS_DEVICE" 7 "ANDROID_DEVICE" 8 "3_BUTTON_BLE_CAR_KEYFOB_P60" 9 "CLOUD_KEY" 10 "3_BUTTON_GEN2_CAR_KEYFOB_P60" 11 "5_BUTTON_GEN2_CAR_KEYFOB_P60" 12 "3_BUTTON_GEN2_CAR_KEYFOB_P60_V2" 13 "3_BUTTON_GEN2_CAR_KEYFOB_P60_V3" ;
VAL_ 857 VCSEC_Device10Formfactor 0 "UNKNOWN" 1 "NFC_CARD" 2 "3_BUTTON_BLE_CAR_KEYFOB" 3 "BLE_DEVICE" 4 "NFC_DEVICE" 5 "BLE_AND_NFC_DEVICE" 6 "IOS_DEVICE" 7 "ANDROID_DEVICE" 8 "3_BUTTON_BLE_CAR_KEYFOB_P60" 9 "CLOUD_KEY" 10 "3_BUTTON_GEN2_CAR_KEYFOB_P60" 11 "5_BUTTON_GEN2_CAR_KEYFOB_P60" 12 "3_BUTTON_GEN2_CAR_KEYFOB_P60_V2" 13 "3_BUTTON_GEN2_CAR_KEYFOB_P60_V3" ;
VAL_ 857 VCSEC_Device11Formfactor 0 "UNKNOWN" 1 "NFC_CARD" 2 "3_BUTTON_BLE_CAR_KEYFOB" 3 "BLE_DEVICE" 4 "NFC_DEVICE" 5 "BLE_AND_NFC_DEVICE" 6 "IOS_DEVICE" 7 "ANDROID_DEVICE" 8 "3_BUTTON_BLE_CAR_KEYFOB_P60" 9 "CLOUD_KEY" 10 "3_BUTTON_GEN2_CAR_KEYFOB_P60" 11 "5_BUTTON_GEN2_CAR_KEYFOB_P60" 12 "3_BUTTON_GEN2_CAR_KEYFOB_P60_V2" 13 "3_BUTTON_GEN2_CAR_KEYFOB_P60_V3" ;
VAL_ 857 VCSEC_Device12Formfactor 0 "UNKNOWN" 1 "NFC_CARD" 2 "3_BUTTON_BLE_CAR_KEYFOB" 3 "BLE_DEVICE" 4 "NFC_DEVICE" 5 "BLE_AND_NFC_DEVICE" 6 "IOS_DEVICE" 7 "ANDROID_DEVICE" 8 "3_BUTTON_BLE_CAR_KEYFOB_P60" 9 "CLOUD_KEY" 10 "3_BUTTON_GEN2_CAR_KEYFOB_P60" 11 "5_BUTTON_GEN2_CAR_KEYFOB_P60" 12 "3_BUTTON_GEN2_CAR_KEYFOB_P60_V2" 13 "3_BUTTON_GEN2_CAR_KEYFOB_P60_V3" ;
VAL_ 857 VCSEC_Device13Formfactor 0 "UNKNOWN" 1 "NFC_CARD" 2 "3_BUTTON_BLE_CAR_KEYFOB" 3 "BLE_DEVICE" 4 "NFC_DEVICE" 5 "BLE_AND_NFC_DEVICE" 6 "IOS_DEVICE" 7 "ANDROID_DEVICE" 8 "3_BUTTON_BLE_CAR_KEYFOB_P60" 9 "CLOUD_KEY" 10 "3_BUTTON_GEN2_CAR_KEYFOB_P60" 11 "5_BUTTON_GEN2_CAR_KEYFOB_P60" 12 "3_BUTTON_GEN2_CAR_KEYFOB_P60_V2" 13 "3_BUTTON_GEN2_CAR_KEYFOB_P60_V3" ;
VAL_ 857 VCSEC_Device14Formfactor 0 "UNKNOWN" 1 "NFC_CARD" 2 "3_BUTTON_BLE_CAR_KEYFOB" 3 "BLE_DEVICE" 4 "NFC_DEVICE" 5 "BLE_AND_NFC_DEVICE" 6 "IOS_DEVICE" 7 "ANDROID_DEVICE" 8 "3_BUTTON_BLE_CAR_KEYFOB_P60" 9 "CLOUD_KEY" 10 "3_BUTTON_GEN2_CAR_KEYFOB_P60" 11 "5_BUTTON_GEN2_CAR_KEYFOB_P60" 12 "3_BUTTON_GEN2_CAR_KEYFOB_P60_V2" 13 "3_BUTTON_GEN2_CAR_KEYFOB_P60_V3" ;
VAL_ 857 VCSEC_Device15Formfactor 0 "UNKNOWN" 1 "NFC_CARD" 2 "3_BUTTON_BLE_CAR_KEYFOB" 3 "BLE_DEVICE" 4 "NFC_DEVICE" 5 "BLE_AND_NFC_DEVICE" 6 "IOS_DEVICE" 7 "ANDROID_DEVICE" 8 "3_BUTTON_BLE_CAR_KEYFOB_P60" 9 "CLOUD_KEY" 10 "3_BUTTON_GEN2_CAR_KEYFOB_P60" 11 "5_BUTTON_GEN2_CAR_KEYFOB_P60" 12 "3_BUTTON_GEN2_CAR_KEYFOB_P60_V2" 13 "3_BUTTON_GEN2_CAR_KEYFOB_P60_V3" ;
VAL_ 857 VCSEC_Device16Formfactor 0 "UNKNOWN" 1 "NFC_CARD" 2 "3_BUTTON_BLE_CAR_KEYFOB" 3 "BLE_DEVICE" 4 "NFC_DEVICE" 5 "BLE_AND_NFC_DEVICE" 6 "IOS_DEVICE" 7 "ANDROID_DEVICE" 8 "3_BUTTON_BLE_CAR_KEYFOB_P60" 9 "CLOUD_KEY" 10 "3_BUTTON_GEN2_CAR_KEYFOB_P60" 11 "5_BUTTON_GEN2_CAR_KEYFOB_P60" 12 "3_BUTTON_GEN2_CAR_KEYFOB_P60_V2" 13 "3_BUTTON_GEN2_CAR_KEYFOB_P60_V3" ;
VAL_ 857 VCSEC_Device17Formfactor 0 "UNKNOWN" 1 "NFC_CARD" 2 "3_BUTTON_BLE_CAR_KEYFOB" 3 "BLE_DEVICE" 4 "NFC_DEVICE" 5 "BLE_AND_NFC_DEVICE" 6 "IOS_DEVICE" 7 "ANDROID_DEVICE" 8 "3_BUTTON_BLE_CAR_KEYFOB_P60" 9 "CLOUD_KEY" 10 "3_BUTTON_GEN2_CAR_KEYFOB_P60" 11 "5_BUTTON_GEN2_CAR_KEYFOB_P60" 12 "3_BUTTON_GEN2_CAR_KEYFOB_P60_V2" 13 "3_BUTTON_GEN2_CAR_KEYFOB_P60_V3" ;
VAL_ 857 VCSEC_Device18Formfactor 0 "UNKNOWN" 1 "NFC_CARD" 2 "3_BUTTON_BLE_CAR_KEYFOB" 3 "BLE_DEVICE" 4 "NFC_DEVICE" 5 "BLE_AND_NFC_DEVICE" 6 "IOS_DEVICE" 7 "ANDROID_DEVICE" 8 "3_BUTTON_BLE_CAR_KEYFOB_P60" 9 "CLOUD_KEY" 10 "3_BUTTON_GEN2_CAR_KEYFOB_P60" 11 "5_BUTTON_GEN2_CAR_KEYFOB_P60" 12 "3_BUTTON_GEN2_CAR_KEYFOB_P60_V2" 13 "3_BUTTON_GEN2_CAR_KEYFOB_P60_V3" ;
VAL_ 857 VCSEC_Device19Formfactor 0 "UNKNOWN" 1 "NFC_CARD" 2 "3_BUTTON_BLE_CAR_KEYFOB" 3 "BLE_DEVICE" 4 "NFC_DEVICE" 5 "BLE_AND_NFC_DEVICE" 6 "IOS_DEVICE" 7 "ANDROID_DEVICE" 8 "3_BUTTON_BLE_CAR_KEYFOB_P60" 9 "CLOUD_KEY" 10 "3_BUTTON_GEN2_CAR_KEYFOB_P60" 11 "5_BUTTON_GEN2_CAR_KEYFOB_P60" 12 "3_BUTTON_GEN2_CAR_KEYFOB_P60_V2" 13 "3_BUTTON_GEN2_CAR_KEYFOB_P60_V3" ;
VAL_ 857 VCSEC_Device1Formfactor 0 "UNKNOWN" 1 "NFC_CARD" 2 "3_BUTTON_BLE_CAR_KEYFOB" 3 "BLE_DEVICE" 4 "NFC_DEVICE" 5 "BLE_AND_NFC_DEVICE" 6 "IOS_DEVICE" 7 "ANDROID_DEVICE" 8 "3_BUTTON_BLE_CAR_KEYFOB_P60" 9 "CLOUD_KEY" 10 "3_BUTTON_GEN2_CAR_KEYFOB_P60" 11 "5_BUTTON_GEN2_CAR_KEYFOB_P60" 12 "3_BUTTON_GEN2_CAR_KEYFOB_P60_V2" 13 "3_BUTTON_GEN2_CAR_KEYFOB_P60_V3" ;
VAL_ 857 VCSEC_Device2Formfactor 0 "UNKNOWN" 1 "NFC_CARD" 2 "3_BUTTON_BLE_CAR_KEYFOB" 3 "BLE_DEVICE" 4 "NFC_DEVICE" 5 "BLE_AND_NFC_DEVICE" 6 "IOS_DEVICE" 7 "ANDROID_DEVICE" 8 "3_BUTTON_BLE_CAR_KEYFOB_P60" 9 "CLOUD_KEY" 10 "3_BUTTON_GEN2_CAR_KEYFOB_P60" 11 "5_BUTTON_GEN2_CAR_KEYFOB_P60" 12 "3_BUTTON_GEN2_CAR_KEYFOB_P60_V2" 13 "3_BUTTON_GEN2_CAR_KEYFOB_P60_V3" ;
VAL_ 857 VCSEC_Device3Formfactor 0 "UNKNOWN" 1 "NFC_CARD" 2 "3_BUTTON_BLE_CAR_KEYFOB" 3 "BLE_DEVICE" 4 "NFC_DEVICE" 5 "BLE_AND_NFC_DEVICE" 6 "IOS_DEVICE" 7 "ANDROID_DEVICE" 8 "3_BUTTON_BLE_CAR_KEYFOB_P60" 9 "CLOUD_KEY" 10 "3_BUTTON_GEN2_CAR_KEYFOB_P60" 11 "5_BUTTON_GEN2_CAR_KEYFOB_P60" 12 "3_BUTTON_GEN2_CAR_KEYFOB_P60_V2" 13 "3_BUTTON_GEN2_CAR_KEYFOB_P60_V3" ;
VAL_ 857 VCSEC_Device4Formfactor 0 "UNKNOWN" 1 "NFC_CARD" 2 "3_BUTTON_BLE_CAR_KEYFOB" 3 "BLE_DEVICE" 4 "NFC_DEVICE" 5 "BLE_AND_NFC_DEVICE" 6 "IOS_DEVICE" 7 "ANDROID_DEVICE" 8 "3_BUTTON_BLE_CAR_KEYFOB_P60" 9 "CLOUD_KEY" 10 "3_BUTTON_GEN2_CAR_KEYFOB_P60" 11 "5_BUTTON_GEN2_CAR_KEYFOB_P60" 12 "3_BUTTON_GEN2_CAR_KEYFOB_P60_V2" 13 "3_BUTTON_GEN2_CAR_KEYFOB_P60_V3" ;
VAL_ 857 VCSEC_Device5Formfactor 0 "UNKNOWN" 1 "NFC_CARD" 2 "3_BUTTON_BLE_CAR_KEYFOB" 3 "BLE_DEVICE" 4 "NFC_DEVICE" 5 "BLE_AND_NFC_DEVICE" 6 "IOS_DEVICE" 7 "ANDROID_DEVICE" 8 "3_BUTTON_BLE_CAR_KEYFOB_P60" 9 "CLOUD_KEY" 10 "3_BUTTON_GEN2_CAR_KEYFOB_P60" 11 "5_BUTTON_GEN2_CAR_KEYFOB_P60" 12 "3_BUTTON_GEN2_CAR_KEYFOB_P60_V2" 13 "3_BUTTON_GEN2_CAR_KEYFOB_P60_V3" ;
VAL_ 857 VCSEC_Device6Formfactor 0 "UNKNOWN" 1 "NFC_CARD" 2 "3_BUTTON_BLE_CAR_KEYFOB" 3 "BLE_DEVICE" 4 "NFC_DEVICE" 5 "BLE_AND_NFC_DEVICE" 6 "IOS_DEVICE" 7 "ANDROID_DEVICE" 8 "3_BUTTON_BLE_CAR_KEYFOB_P60" 9 "CLOUD_KEY" 10 "3_BUTTON_GEN2_CAR_KEYFOB_P60" 11 "5_BUTTON_GEN2_CAR_KEYFOB_P60" 12 "3_BUTTON_GEN2_CAR_KEYFOB_P60_V2" 13 "3_BUTTON_GEN2_CAR_KEYFOB_P60_V3" ;
VAL_ 857 VCSEC_Device7Formfactor 0 "UNKNOWN" 1 "NFC_CARD" 2 "3_BUTTON_BLE_CAR_KEYFOB" 3 "BLE_DEVICE" 4 "NFC_DEVICE" 5 "BLE_AND_NFC_DEVICE" 6 "IOS_DEVICE" 7 "ANDROID_DEVICE" 8 "3_BUTTON_BLE_CAR_KEYFOB_P60" 9 "CLOUD_KEY" 10 "3_BUTTON_GEN2_CAR_KEYFOB_P60" 11 "5_BUTTON_GEN2_CAR_KEYFOB_P60" 12 "3_BUTTON_GEN2_CAR_KEYFOB_P60_V2" 13 "3_BUTTON_GEN2_CAR_KEYFOB_P60_V3" ;
VAL_ 857 VCSEC_Device8Formfactor 0 "UNKNOWN" 1 "NFC_CARD" 2 "3_BUTTON_BLE_CAR_KEYFOB" 3 "BLE_DEVICE" 4 "NFC_DEVICE" 5 "BLE_AND_NFC_DEVICE" 6 "IOS_DEVICE" 7 "ANDROID_DEVICE" 8 "3_BUTTON_BLE_CAR_KEYFOB_P60" 9 "CLOUD_KEY" 10 "3_BUTTON_GEN2_CAR_KEYFOB_P60" 11 "5_BUTTON_GEN2_CAR_KEYFOB_P60" 12 "3_BUTTON_GEN2_CAR_KEYFOB_P60_V2" 13 "3_BUTTON_GEN2_CAR_KEYFOB_P60_V3" ;
VAL_ 857 VCSEC_Device9Formfactor 0 "UNKNOWN" 1 "NFC_CARD" 2 "3_BUTTON_BLE_CAR_KEYFOB" 3 "BLE_DEVICE" 4 "NFC_DEVICE" 5 "BLE_AND_NFC_DEVICE" 6 "IOS_DEVICE" 7 "ANDROID_DEVICE" 8 "3_BUTTON_BLE_CAR_KEYFOB_P60" 9 "CLOUD_KEY" 10 "3_BUTTON_GEN2_CAR_KEYFOB_P60" 11 "5_BUTTON_GEN2_CAR_KEYFOB_P60" 12 "3_BUTTON_GEN2_CAR_KEYFOB_P60_V2" 13 "3_BUTTON_GEN2_CAR_KEYFOB_P60_V3" ;
VAL_ 857 VCSEC_Device0Role 0 "NONE" 1 "SERVICE_KEY" 2 "OWNER_KEY" 3 "USER_KEY" 4 "FM_KEY" ;
VAL_ 857 VCSEC_Device10Role 0 "NONE" 1 "SERVICE_KEY" 2 "OWNER_KEY" 3 "USER_KEY" 4 "FM_KEY" ;
VAL_ 857 VCSEC_Device11Role 0 "NONE" 1 "SERVICE_KEY" 2 "OWNER_KEY" 3 "USER_KEY" 4 "FM_KEY" ;
VAL_ 857 VCSEC_Device12Role 0 "NONE" 1 "SERVICE_KEY" 2 "OWNER_KEY" 3 "USER_KEY" 4 "FM_KEY" ;
VAL_ 857 VCSEC_Device13Role 0 "NONE" 1 "SERVICE_KEY" 2 "OWNER_KEY" 3 "USER_KEY" 4 "FM_KEY" ;
VAL_ 857 VCSEC_Device14Role 0 "NONE" 1 "SERVICE_KEY" 2 "OWNER_KEY" 3 "USER_KEY" 4 "FM_KEY" ;
VAL_ 857 VCSEC_Device15Role 0 "NONE" 1 "SERVICE_KEY" 2 "OWNER_KEY" 3 "USER_KEY" 4 "FM_KEY" ;
VAL_ 857 VCSEC_Device16Role 0 "NONE" 1 "SERVICE_KEY" 2 "OWNER_KEY" 3 "USER_KEY" 4 "FM_KEY" ;
VAL_ 857 VCSEC_Device17Role 0 "NONE" 1 "SERVICE_KEY" 2 "OWNER_KEY" 3 "USER_KEY" 4 "FM_KEY" ;
VAL_ 857 VCSEC_Device18Role 0 "NONE" 1 "SERVICE_KEY" 2 "OWNER_KEY" 3 "USER_KEY" 4 "FM_KEY" ;
VAL_ 857 VCSEC_Device19Role 0 "NONE" 1 "SERVICE_KEY" 2 "OWNER_KEY" 3 "USER_KEY" 4 "FM_KEY" ;
VAL_ 857 VCSEC_Device1Role 0 "NONE" 1 "SERVICE_KEY" 2 "OWNER_KEY" 3 "USER_KEY" 4 "FM_KEY" ;
VAL_ 857 VCSEC_Device2Role 0 "NONE" 1 "SERVICE_KEY" 2 "OWNER_KEY" 3 "USER_KEY" 4 "FM_KEY" ;
VAL_ 857 VCSEC_Device3Role 0 "NONE" 1 "SERVICE_KEY" 2 "OWNER_KEY" 3 "USER_KEY" 4 "FM_KEY" ;
VAL_ 857 VCSEC_Device4Role 0 "NONE" 1 "SERVICE_KEY" 2 "OWNER_KEY" 3 "USER_KEY" 4 "FM_KEY" ;
VAL_ 857 VCSEC_Device5Role 0 "NONE" 1 "SERVICE_KEY" 2 "OWNER_KEY" 3 "USER_KEY" 4 "FM_KEY" ;
VAL_ 857 VCSEC_Device6Role 0 "NONE" 1 "SERVICE_KEY" 2 "OWNER_KEY" 3 "USER_KEY" 4 "FM_KEY" ;
VAL_ 857 VCSEC_Device7Role 0 "NONE" 1 "SERVICE_KEY" 2 "OWNER_KEY" 3 "USER_KEY" 4 "FM_KEY" ;
VAL_ 857 VCSEC_Device8Role 0 "NONE" 1 "SERVICE_KEY" 2 "OWNER_KEY" 3 "USER_KEY" 4 "FM_KEY" ;
VAL_ 857 VCSEC_Device9Role 0 "NONE" 1 "SERVICE_KEY" 2 "OWNER_KEY" 3 "USER_KEY" 4 "FM_KEY" ;
VAL_ 857 VCSEC_DeviceStatusIndex 0 "0_VITALS" 1 "0_STATS" 2 "0_INFO" 3 "0_INFO2" 4 "0_MODEL_NUMBER" 5 "1_VITALS" 6 "1_STATS" 7 "1_INFO" 8 "1_INFO2" 9 "1_MODEL_NUMBER" 10 "2_VITALS" 11 "2_STATS" 12 "2_INFO" 13 "2_INFO2" 14 "2_MODEL_NUMBER" 15 "3_VITALS" 16 "3_STATS" 17 "3_INFO" 18 "3_INFO2" 19 "3_MODEL_NUMBER" 20 "4_VITALS" 21 "4_STATS" 22 "4_INFO" 23 "4_INFO2" 24 "4_MODEL_NUMBER" 25 "5_VITALS" 26 "5_STATS" 27 "5_INFO" 28 "5_INFO2" 29 "5_MODEL_NUMBER" 30 "6_VITALS" 31 "6_STATS" 32 "6_INFO" 33 "6_INFO2" 34 "6_MODEL_NUMBER" 35 "7_VITALS" 36 "7_STATS" 37 "7_INFO" 38 "7_INFO2" 39 "7_MODEL_NUMBER" 40 "8_VITALS" 41 "8_STATS" 42 "8_INFO" 43 "8_INFO2" 44 "8_MODEL_NUMBER" 45 "9_VITALS" 46 "9_STATS" 47 "9_INFO" 48 "9_INFO2" 49 "9_MODEL_NUMBER" 50 "10_VITALS" 51 "10_STATS" 52 "10_INFO" 53 "10_INFO2" 54 "10_MODEL_NUMBER" 55 "11_VITALS" 56 "11_STATS" 57 "11_INFO" 58 "11_INFO2" 59 "11_MODEL_NUMBER" 60 "12_VITALS" 61 "12_STATS" 62 "12_INFO" 63 "12_INFO2" 64 "12_MODEL_NUMBER" 65 "13_VITALS" 66 "13_STATS" 67 "13_INFO" 68 "13_INFO2" 69 "13_MODEL_NUMBER" 70 "14_VITALS" 71 "14_STATS" 72 "14_INFO" 73 "14_INFO2" 74 "14_MODEL_NUMBER" 75 "15_VITALS" 76 "15_STATS" 77 "15_INFO" 78 "15_INFO2" 79 "15_MODEL_NUMBER" 80 "16_VITALS" 81 "16_STATS" 82 "16_INFO" 83 "16_INFO2" 84 "16_MODEL_NUMBER" 85 "17_VITALS" 86 "17_STATS" 87 "17_INFO" 88 "17_INFO2" 89 "17_MODEL_NUMBER" 90 "18_VITALS" 91 "18_STATS" 92 "18_INFO" 93 "18_INFO2" 94 "18_MODEL_NUMBER" 95 "19_VITALS" 96 "19_STATS" 97 "19_INFO" 98 "19_INFO2" 99 "19_MODEL_NUMBER" ;
CM_ BO_ 899 "ESP32-DualCAN Model3_CH. Seen on this car: 8-byte frames; fit ok (bits covered 100%, mux 100%, ranges 100%, checksum 0%).";
VAL_ 899 VCRIGHT_occupantClassificationQF 0 "FAULTED" 1 "NOT_FAULTED" ;
VAL_ 899 VCRIGHT_occupantClassification 0 "EMPTY" 1 "INHIBIT" 2 "SMALL" 3 "LARGE" 4 "INIT" 5 "NOT_CONFIGURED" 7 "SNA" ;
VAL_ 899 VCRIGHT_seatTrackPosition 0 "FORWARD" 1 "REARWARD" 2 "NOT_CONFIGURED" 3 "FAULTED" 7 "SNA" ;
VAL_ 899 VCRIGHT_3RowRightOccupancyStatus 0 "UNOCCUPIED" 1 "OCCUPIED" 2 "OCCUPANCY_FAULTED" 3 "OCCUPANCY_SNA" ;
VAL_ 899 VCRIGHT_3RowLeftOccupancyStatus 0 "UNOCCUPIED" 1 "OCCUPIED" 2 "OCCUPANCY_FAULTED" 3 "OCCUPANCY_SNA" ;
VAL_ 899 VCRIGHT_3RowRightBuckleStatus 0 "UNLATCHED" 1 "LATCHED" 2 "FAULTED" 3 "SNA" ;
VAL_ 899 VCRIGHT_3RowLeftBuckleStatus 0 "UNLATCHED" 1 "LATCHED" 2 "FAULTED" 3 "SNA" ;
VAL_ 899 VCRIGHT_rearRightOccupancyStatus 0 "UNOCCUPIED" 1 "OCCUPIED" 2 "OCCUPANCY_FAULTED" 3 "OCCUPANCY_SNA" ;
VAL_ 899 VCRIGHT_rearRightBuckleStatus 0 "UNLATCHED" 1 "LATCHED" 2 "FAULTED" 3 "SNA" ;
VAL_ 899 VCRIGHT_rearCenterBuckleStatus 0 "UNLATCHED" 1 "LATCHED" 2 "FAULTED" 3 "SNA" ;
VAL_ 899 VCRIGHT_frontBuckleStatus 0 "UNLATCHED" 1 "LATCHED" 2 "FAULTED" 3 "SNA" ;
VAL_ 899 VCRIGHT_frontOccupancyStatus 0 "UNOCCUPIED" 1 "OCCUPIED" 2 "OCCUPANCY_FAULTED" 3 "NOT_CONFIGURED" 7 "OCCUPANCY_SNA" ;
CM_ BO_ 969 "ESP32-DualCAN Model3_VEH. Seen on this car: 8-byte frames; fit good (bits covered 100%, mux 100%, ranges 100%).";
VAL_ 969 VCSEC_BLEEndpointInfoIndex 0 "BLELeftInfo" 1 "BLERightInfo" 2 "BLERearInfo" 3 "BLECenterInfo" 4 "BLELeftAppGithash" 5 "BLERightAppGithash" 6 "BLERearAppGithash" 7 "BLECenterAppGithash" 8 "BLEFrontInfo" 9 "BLESecondaryInfo" 10 "BLENFCCradleInfo" 11 "BLELeftRearInfo" 12 "BLERightRearInfo" 13 "BLEFrontAppGithash" 14 "BLESecondaryAppGithash" 15 "BLENFCCradleAppGithash" 16 "BLELeftRearAppGithash" 17 "BLERightRearAppGithash" 18 "UWBLeftInfo" 19 "UWBRightInfo" 20 "UWBRearLeftInfo" 21 "UWBRearRightInfo" 22 "UWBFrontInfo" 23 "UWBLeftAppGithash" 24 "UWBRightAppGithash" 25 "UWBRearLeftAppGithash" 26 "UWBRearRightAppGithash" 27 "UWBFrontAppGithash" ;
CM_ BO_ 995 "ESP32-DualCAN Model3_VEH. Seen on this car: 5-byte frames; fit ok (bits covered 100%, mux 100%, ranges 100%). read by the app or firmware.";
VAL_ 995 VCRIGHT_rearFogLightStatus 0 "OFF" 1 "ON" 2 "FAULT" 3 "SNA" ;
VAL_ 995 VCRIGHT_reverseLightStatus 0 "OFF" 1 "ON" 2 "FAULT" 3 "SNA" ;
VAL_ 995 VCRIGHT_turnSignalStatus 0 "OFF" 1 "ON" 2 "FAULT" 3 "SNA" ;
VAL_ 995 VCRIGHT_tailLightStatus 0 "OFF" 1 "ON" 2 "FAULT" 3 "SNA" ;
VAL_ 995 VCRIGHT_brakeLightStatus 0 "OFF" 1 "ON" 2 "FAULT" 3 "SNA" ;
CM_ BO_ 1017 "ESP32-DualCAN Model3_VEH. Seen on this car: 8-byte frames; fit good (bits covered 100%, mux 86%, ranges 100%).";
VAL_ 1017 VCSEC_matrixIndex 0 "AlertMatrix0" 1 "AlertMatrix1" 2 "AlertMatrix2" 3 "AlertMatrix3" 4 "AlertMatrix4" 5 "AlertMatrix5" 6 "AlertMatrix6" 7 "AlertMatrix7" ;
CM_ BO_ 1251 "ESP32-DualCAN Model3_VEH. Seen on this car: 8-byte frames; fit good (bits covered 100%, mux 100%, ranges 100%).";
VAL_ 1251 VCRIGHT_frontSeatBackState 0 "STOPPED" 1 "MOVING_UP" 2 "MOVING_DOWN" 3 "RECALLING" 4 "CALIBRATING" 5 "UNDEFINED" ;
VAL_ 1251 VCRIGHT_frontSeatLiftState 0 "STOPPED" 1 "MOVING_UP" 2 "MOVING_DOWN" 3 "RECALLING" 4 "CALIBRATING" 5 "UNDEFINED" ;
VAL_ 1251 VCRIGHT_frontSeatTiltState 0 "STOPPED" 1 "MOVING_UP" 2 "MOVING_DOWN" 3 "RECALLING" 4 "CALIBRATING" 5 "UNDEFINED" ;
VAL_ 1251 VCRIGHT_frontSeatTrackState 0 "STOPPED" 1 "MOVING_UP" 2 "MOVING_DOWN" 3 "RECALLING" 4 "CALIBRATING" 5 "UNDEFINED" ;
VAL_ 1251 VCRIGHT_lumbarBState 0 "STOPPED" 1 "MOVING_UP" 2 "MOVING_DOWN" 3 "RECALLING" 4 "CALIBRATING" 5 "UNDEFINED" ;
VAL_ 1251 VCRIGHT_lumbarAState 0 "STOPPED" 1 "MOVING_UP" 2 "MOVING_DOWN" 3 "RECALLING" 4 "CALIBRATING" 5 "UNDEFINED" ;
VAL_ 1251 VCRIGHT_seatStatusIndex 0 "TRACK" 1 "BACK" 2 "LIFT" 3 "TILT" 4 "LUMBAR" 5 "POSITION" ;
